VERSION ""

NS_ :

BS_:

BU_: VSIM TTPM TCM SGW SCCM RF_HUB PTS PCM ORC ITBM IRCM IC FTM FDCM ETM ESM ESC ECM DTCM DIAGNOST CBC ATMM ASCM AFLS 4 _ 0 C I w E 6 S A V Vector__XXX T

BO_ 992 VIN: 8 ECM
 SG_ VIN_MSG : 0|2@1+ (1,0) [0|0] "" FTM,TTPM,ATMM,IRCM,SGW,ITBM,FDCM,VSIM,TCM,SCCM,RF_HUB,PTS,ORC,IC,ETM,ESM,ESC,DTCM,CBC,ASCM,AFLS
 SG_ VIN_DATA : 15|56@0+ (1,0) [0|0] "" FTM,TTPM,ATMM,IRCM,SGW,ITBM,FDCM,VSIM,TCM,SCCM,RF_HUB,PTS,ORC,IC,ETM,ESM,ESC,DTCM,CBC,ASCM,AFLS

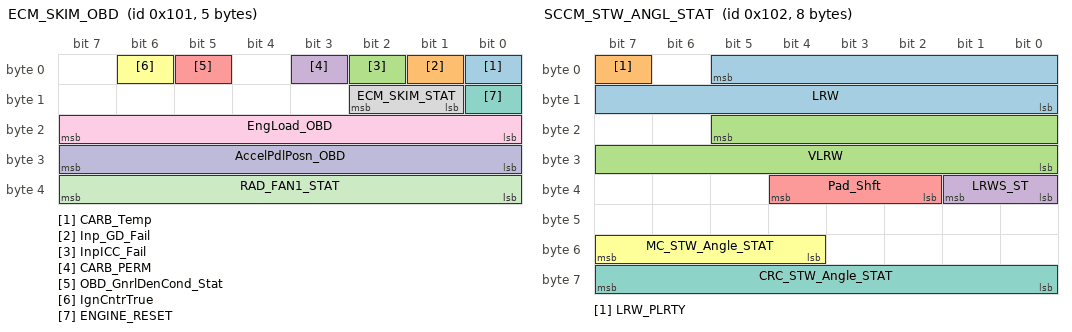
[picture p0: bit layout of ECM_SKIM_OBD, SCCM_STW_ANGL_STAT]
BO_ 257 ECM_SKIM_OBD: 5 ECM
 SG_ CARB_Temp : 0|1@1+ (1,0) [0|0] "" SGW,TCM
 SG_ Inp_GD_Fail : 1|1@1+ (1,0) [0|0] "" SGW,TCM
 SG_ InpICC_Fail : 2|1@1+ (1,0) [0|0] "" SGW,TCM
 SG_ CARB_PERM : 3|1@1+ (1,0) [0|0] "" SGW,TCM
 SG_ OBD_GnrlDenCond_Stat : 5|1@1+ (1,0) [0|0] "" SGW,TCM
 SG_ IgnCntrTrue : 6|1@1+ (1,0) [0|0] "" SGW,TCM
 SG_ ENGINE_RESET : 8|1@1+ (1,0) [0|0] "" SGW
 SG_ ECM_SKIM_STAT : 9|2@1+ (1,0) [0|0] "" SGW
 SG_ EngLoad_OBD : 16|8@1+ (0.3922,0) [0|100] "%" FTM,SGW,TCM,ETM
 SG_ AccelPdlPosn_OBD : 24|8@1+ (0.3922,0) [0|100] "%" SGW,VSIM,TCM,ETM
 SG_ RAD_FAN1_STAT : 32|8@1+ (1,0) [0|100] "%" FTM,SGW,ETM

BO_ 258 SCCM_STW_ANGL_STAT: 8 SCCM
 SG_ LRW : 5|14@0+ (0.5,-2048) [-2048|2047] "Degrees" FTM,IRCM,SGW,PCM,TCM,ORC,ESC,ECM,DTCM,CBC,ASCM,AFLS
 SG_ LRW_PLRTY : 7|1@1+ (1,0) [0|0] "" IRCM,SGW,ORC,ETM,ESC,AFLS
 SG_ VLRW : 21|14@0+ (0.5,-2048) [-2048|2047] "°/s" IRCM,SGW,PCM,ESC,ECM,DTCM,AFLS
 SG_ LRWS_ST : 32|2@1+ (1,0) [0|0] "" IRCM,SGW,PCM,ORC,ESC,ECM,DTCM,CBC,ASCM,AFLS
 SG_ Pad_Shft : 34|3@1+ (1,0) [0|0] "" SGW,PCM,TCM
 SG_ MC_STW_Angle_STAT : 52|4@1+ (1,0) [0|15] "" IRCM,SGW,PCM,PTS,ORC,ETM,ESC,ECM
 SG_ CRC_STW_Angle_STAT : 56|8@1+ (1,0) [0|0] "" IRCM,SGW,PCM,PTS,ORC,ETM,ESC,ECM

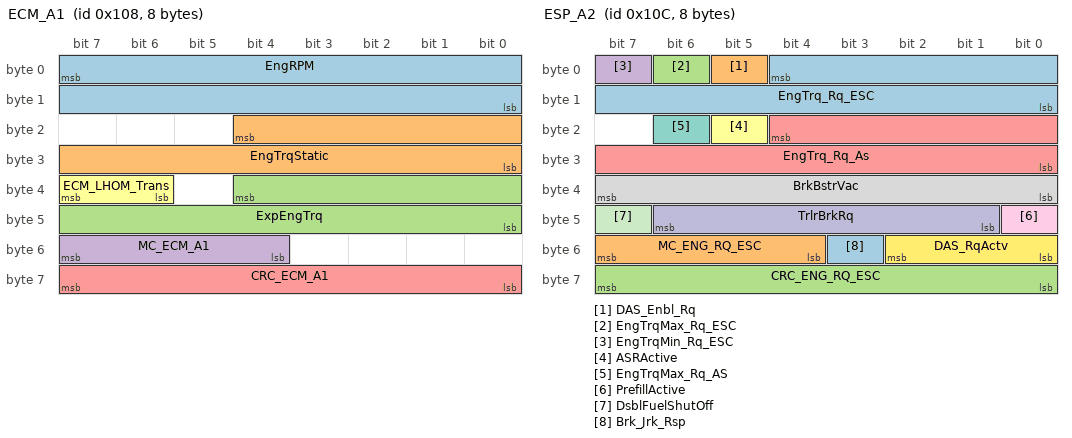
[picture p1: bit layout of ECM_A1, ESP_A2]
BO_ 264 ECM_A1: 8 ECM
 SG_ EngRPM : 7|16@0+ (1,0) [0|65534] "rpm" ATMM,IRCM,SGW,VSIM,TCM,RF_HUB,ORC,IC,ETM,ESC,DTCM,CBC,ASCM,AFLS
 SG_ EngTrqStatic : 20|13@0+ (0.25,-500) [-500|1547.5] "Nm" FTM,IRCM,SGW,TCM,ORC,ETM,ESC,DTCM
 SG_ ExpEngTrq : 36|13@0+ (0.25,-500) [-500|1547.5] "Nm" IRCM,SGW,TCM,ESC
 SG_ MC_ECM_A1 : 52|4@1+ (1,0) [0|15] "" IRCM,SGW,TCM,ESC
 SG_ CRC_ECM_A1 : 56|8@1+ (1,0) [0|0] "" IRCM,SGW,TCM,ESC
 SG_ ECM_LHOM_Trans : 38|2@1+ (1,0) [0|0] "" SGW,TCM

BO_ 268 ESP_A2: 8 ESC
 SG_ EngTrq_Rq_ESC : 4|13@0+ (0.25,-500) [-500|1547.5] "Nm" FTM,SGW,PCM,ETM,ECM
 SG_ DAS_Enbl_Rq : 5|1@1+ (1,0) [0|0] "" IRCM,SGW
 SG_ EngTrqMax_Rq_ESC : 6|1@1+ (1,0) [0|0] "" SGW,PCM,VSIM,TCM,ECM
 SG_ EngTrqMin_Rq_ESC : 7|1@1+ (1,0) [0|0] "" SGW,PCM,VSIM,TCM,ECM,DTCM
 SG_ EngTrq_Rq_As : 20|13@0+ (0.25,-500) [-500|1547.5] "Nm" IRCM,SGW,PCM,ORC,ECM
 SG_ ASRActive : 21|1@1+ (1,0) [0|0] "" FTM,IRCM,SGW,VSIM,ORC
 SG_ EngTrqMax_Rq_AS : 22|1@1+ (1,0) [0|0] "" SGW,PCM,ECM
 SG_ BrkBstrVac : 32|8@1+ (0.55,-119.7) [-119.7|20] "kPa" SGW,PCM,ORC,ECM
 SG_ PrefillActive : 40|1@1+ (1,0) [0|0] "" IRCM,SGW
 SG_ TrlrBrkRq : 41|6@1+ (2,0) [0|100] "%" SGW,ITBM
 SG_ DsblFuelShutOff : 47|1@1+ (1,0) [0|0] "" SGW,PCM,ECM
 SG_ DAS_RqActv : 48|3@1+ (1,0) [0|0] "" IRCM,SGW,ORC
 SG_ Brk_Jrk_Rsp : 51|1@1+ (1,0) [0|0] "" IRCM,SGW,ORC
 SG_ MC_ENG_RQ_ESC : 52|4@1+ (1,0) [0|15] "" IRCM,SGW,PCM,TCM,ECM
 SG_ CRC_ENG_RQ_ESC : 56|8@1+ (1,0) [0|0] "" IRCM,SGW,PCM,TCM,ECM

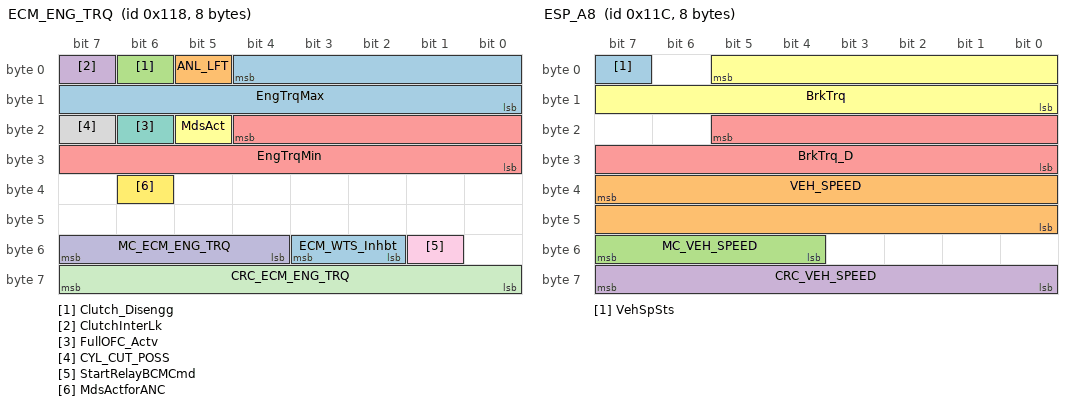
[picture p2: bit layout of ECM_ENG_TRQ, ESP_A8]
BO_ 280 ECM_ENG_TRQ: 8 ECM
 SG_ EngTrqMax : 4|13@0+ (0.25,-500) [-500|1547.5] "Nm" IRCM,SGW,TCM,ESC,DTCM
 SG_ ANL_LFT : 5|1@1+ (1,0) [0|0] "" SGW,CBC,ASCM
 SG_ Clutch_Disengg : 6|1@1+ (1,0) [0|0] "" SGW,ORC,ESC,CBC
 SG_ ClutchInterLk : 7|1@1+ (1,0) [0|0] "" SGW,ORC,ESC,DTCM
 SG_ EngTrqMin : 20|13@0+ (0.25,-500) [-500|1547.5] "Nm" IRCM,SGW,ESC,DTCM
 SG_ MdsAct : 21|1@1+ (1,0) [0|0] "" FTM,SGW,TCM,IC,ETM
 SG_ FullOFC_Actv : 22|1@1+ (1,0) [0|0] "" IRCM,SGW,ESC
 SG_ CYL_CUT_POSS : 23|1@1+ (1,0) [0|0] "" SGW
 SG_ StartRelayBCMCmd : 49|1@1+ (1,0) [0|0] "" SGW,CBC
 SG_ MC_ECM_ENG_TRQ : 52|4@1+ (1,0) [0|15] "" IRCM,SGW,TCM,ESC
 SG_ CRC_ECM_ENG_TRQ : 56|8@1+ (1,0) [0|0] "" IRCM,SGW,TCM,ESC
 SG_ MdsActforANC : 38|1@1+ (1,0) [0|0] "" ATMM,SGW,CBC
 SG_ ECM_WTS_Inhbt : 50|2@1+ (1,0) [0|0] "" SGW,CBC

BO_ 284 ESP_A8: 8 ESC
 SG_ VehSpSts : 7|1@1+ (1,0) [0|0] "" IRCM,SGW
 SG_ VEH_SPEED : 39|16@0+ (0.0078125,0) [0|511.984375] "km/h" FTM,TTPM,ATMM,IRCM,SGW,ITBM,FDCM,PCM,VSIM,TCM,RF_HUB,PTS,ORC,IC,ECM,DTCM,CBC,ASCM,AFLS
 SG_ MC_VEH_SPEED : 52|4@1+ (1,0) [0|15] "" IRCM,SGW,PCM,TCM,PTS,ORC,IC,ESM,ECM,CBC
 SG_ CRC_VEH_SPEED : 56|8@1+ (1,0) [0|0] "" IRCM,SGW,PCM,TCM,PTS,ORC,IC,ESM,ECM,CBC
 SG_ BrkTrq_D : 21|14@0+ (3,0) [0|49146] "Nm" IRCM,SGW,ECM
 SG_ BrkTrq : 5|14@0+ (3,0) [0|49146] "Nm" IRCM,SGW,ITBM,TCM,ORC,ECM

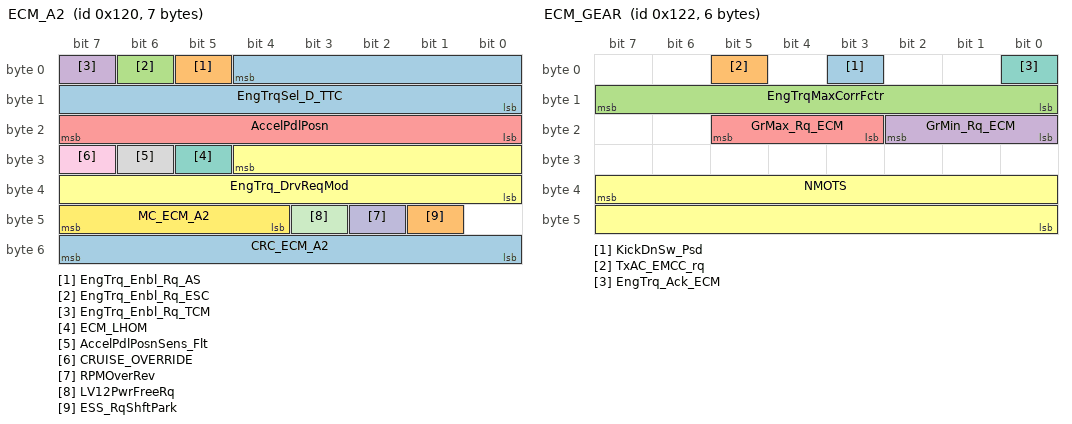
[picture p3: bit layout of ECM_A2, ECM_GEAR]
BO_ 288 ECM_A2: 7 ECM
 SG_ EngTrqSel_D_TTC : 4|13@0+ (0.25,-500) [-500|1547.5] "Nm" IRCM,SGW,TCM,ORC,ESC
 SG_ EngTrq_Enbl_Rq_AS : 5|1@1+ (1,0) [0|0] "" IRCM,SGW,ESC
 SG_ EngTrq_Enbl_Rq_ESC : 6|1@1+ (1,0) [0|0] "" IRCM,SGW,ESC
 SG_ EngTrq_Enbl_Rq_TCM : 7|1@1+ (1,0) [0|0] "" SGW,TCM,ORC
 SG_ AccelPdlPosn : 16|8@1+ (0.4,0) [0|100] "%" FTM,SGW,TCM,ETM,ESC,DTCM,CBC
 SG_ EngTrq_DrvReqMod : 28|13@0+ (0.25,-500) [-500|1547.5] "Nm" SGW,TCM,ESC
 SG_ ECM_LHOM : 29|1@1+ (1,0) [0|0] "" IRCM,SGW,TCM
 SG_ AccelPdlPosnSens_Flt : 30|1@1+ (1,0) [0|0] "" IRCM,SGW,TCM,ESC,CBC
 SG_ CRUISE_OVERRIDE : 31|1@1+ (1,0) [0|0] "" IRCM,SGW,TCM,ORC,ESC
 SG_ RPMOverRev : 42|1@1+ (1,0) [0|0] "" IRCM,SGW
 SG_ LV12PwrFreeRq : 43|1@1+ (1,0) [0|0] "" SGW,TCM,ESC
 SG_ MC_ECM_A2 : 44|4@1+ (1,0) [0|15] "" IRCM,SGW,TCM,ESC
 SG_ CRC_ECM_A2 : 48|8@1+ (1,0) [0|0] "" IRCM,SGW,TCM,ESC
 SG_ ESS_RqShftPark : 41|1@1+ (1,0) [0|0] "" SGW,TCM

BO_ 290 ECM_GEAR: 6 ECM
 SG_ KickDnSw_Psd : 3|1@1+ (1,0) [0|0] "" SGW,TCM,ESC
 SG_ TxAC_EMCC_rq : 5|1@1+ (1,0) [0|0] "" SGW,TCM
 SG_ EngTrqMaxCorrFctr : 8|8@1+ (0.0078,0) [0|1.98] "Nm" SGW,TCM
 SG_ GrMin_Rq_ECM : 16|3@1+ (1,0) [0|0] "" SGW,TCM
 SG_ GrMax_Rq_ECM : 19|3@1+ (1,0) [0|0] "" SGW,TCM
 SG_ NMOTS : 39|16@0+ (1,0) [0|65534] "rpm" SGW,TCM,ESC
 SG_ EngTrq_Ack_ECM : 0|1@1+ (1,0) [0|0] "" SGW,TCM

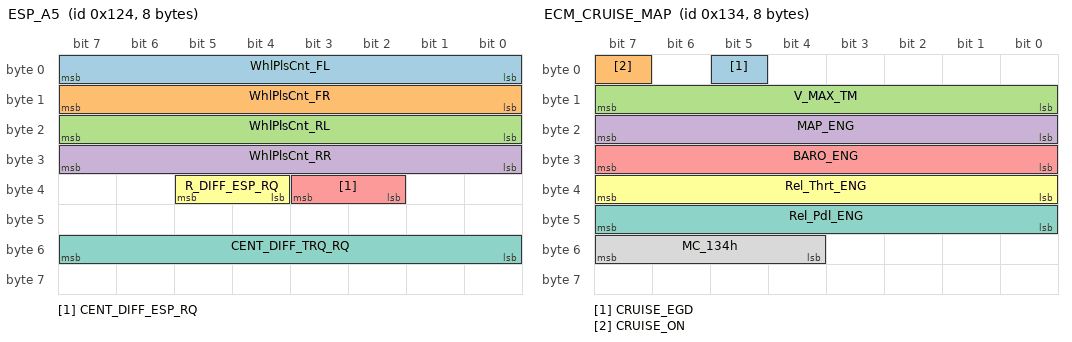
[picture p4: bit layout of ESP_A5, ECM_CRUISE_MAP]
BO_ 292 ESP_A5: 8 ESC
 SG_ WhlPlsCnt_FL : 0|8@1+ (1,0) [0|254] "Impulse" IRCM,SGW,RF_HUB,CBC
 SG_ WhlPlsCnt_FR : 8|8@1+ (1,0) [0|254] "Impulse" IRCM,SGW,RF_HUB,CBC
 SG_ WhlPlsCnt_RL : 16|8@1+ (1,0) [0|254] "Impulse" IRCM,SGW,RF_HUB,CBC
 SG_ WhlPlsCnt_RR : 24|8@1+ (1,0) [0|254] "Impulse" IRCM,SGW,RF_HUB,CBC
 SG_ CENT_DIFF_ESP_RQ : 34|2@1+ (1,0) [0|0] "" SGW,DTCM
 SG_ R_DIFF_ESP_RQ : 36|2@1+ (1,0) [0|0] "" SGW,FDCM
 SG_ CENT_DIFF_TRQ_RQ : 48|8@1+ (10,0) [0|2540] "Nm" SGW,DTCM

BO_ 308 ECM_CRUISE_MAP: 8 ECM
 SG_ CRUISE_EGD : 5|1@1+ (1,0) [0|0] "" FTM,SGW,VSIM,TCM,ORC,IC,ESC,CBC
 SG_ CRUISE_ON : 7|1@1+ (1,0) [0|0] "" FTM,SGW,TCM,ORC,IC,ESC
 SG_ V_MAX_TM : 8|8@1+ (1,0) [0|250] "km/h(mph)" SGW,TCM
 SG_ MAP_ENG : 16|8@1+ (0.8,0) [0|203.2] "kPa" FTM,SGW,ETM,ESC
 SG_ BARO_ENG : 24|8@1+ (1,0) [0|254] "kPaA" SGW,ETM,ESC
 SG_ Rel_Thrt_ENG : 32|8@1+ (0.019607843,0) [0|4.98] "Volts" SGW,ETM,ESC
 SG_ Rel_Pdl_ENG : 40|8@1+ (0.019607843,0) [0|4.98] "Volts" SGW,ETM,ESC
 SG_ MC_134h : 52|4@1+ (1,0) [0|15] "" SGW,TCM,ESC

BO_ 320 ESP_A1: 8 ESC
 SG_ Brk_Stat : 0|2@1+ (1,0) [0|0] "" FTM,SGW,ITBM,PCM,VSIM,TCM,ETM,ECM,CBC
 SG_ BrkPdl_Stat : 2|2@1+ (1,0) [0|0] "" IRCM,SGW,ITBM,PCM,VSIM,TCM,RF_HUB,ORC,ECM,DTCM,CBC
 SG_ BrkPdl_Flt : 4|1@1+ (1,0) [0|0] "" IRCM,SGW,PCM,TCM,ETM,ECM
 SG_ BrkIntrvntn_Actv_ESP : 5|1@1+ (1,0) [0|0] "" FTM,SGW,TCM,ORC,ETM,DTCM
 SG_ BrkIntrvntn_Actv_AS : 6|1@1+ (1,0) [0|0] "" IRCM,SGW,TCM,ETM
 SG_ BrkIntrvntn_Enbl : 7|1@1+ (1,0) [0|0] "" SGW,TCM,ORC,ECM
 SG_ EmgBrk_Actv : 8|1@1+ (1,0) [0|0] "" SGW,ORC
 SG_ FullBrk_Actv : 9|1@1+ (1,0) [0|0] "" SGW,ORC
 SG_ ESP_Sys_Stat : 10|2@1+ (1,0) [0|0] "" SGW,PCM,TCM,ETM,ECM
 SG_ ABS_BrkEvt : 14|1@1+ (1,0) [0|0] "" FTM,IRCM,SGW,PCM,VSIM,TCM,ORC,ETM,ECM,DTCM
 SG_ DTR_CC_Engaged : 15|1@1+ (1,0) [0|0] "" SGW,PCM,TCM,ECM,CBC
 SG_ GrMin_Rq_ESC : 16|3@1+ (1,0) [0|0] "" SGW,PCM,TCM
 SG_ GrMax_Rq_ESC : 19|3@1+ (1,0) [0|0] "" SGW,PCM,TCM
 SG_ GrMinMax_Rq_DTR : 22|1@1+ (1,0) [0|0] "" SGW,TCM
 SG_ DTR_CC_Enabled : 23|1@1+ (1,0) [0|0] "" SGW,PCM,ECM
 SG_ Brk_Thermdl : 25|1@1+ (1,0) [0|0] "" IRCM,SGW
 SG_ ShftChrDsp_Rq_ESC : 26|4@1+ (1,0) [0|0] "" SGW,PCM,TCM,ECM
 SG_ RollTestMd_Actv : 30|2@1+ (1,0) [0|0] "" IRCM,SGW,DTCM
 SG_ REF_VEH_SPEED : 33|10@0+ (0.5,0) [0|511] "km/h" SGW,TCM,ORC,ECM
 SG_ SPCR_AS_Off_Rq : 38|2@1+ (1,0) [0|0] "" IRCM,SGW,PCM,ECM
 SG_ MC_Brk_Stat : 52|4@1+ (1,0) [0|15] "" IRCM,SGW,PCM,TCM,PTS,ORC,ECM
 SG_ CRC_Brk_Stat : 56|8@1+ (1,0) [0|0] "" IRCM,SGW,PCM,TCM,PTS,ORC,ECM

BO_ 324 TRNS_SPD: 8 TCM
 SG_ K_STO_B : 0|1@1+ (1,0) [0|0] "" FTM,SGW,ETM,ECM
 SG_ EngSt_Enbl_Rq_TCM : 5|1@1+ (1,0) [0|0] "" FTM,SGW,RF_HUB,ETM
 SG_ Gr : 8|4@1+ (1,0) [0|0] "" FTM,IRCM,SGW,VSIM,RF_HUB,ORC,IC,ESC,ECM,DTCM,CBC,ASCM
 SG_ Gr_Target : 12|4@1+ (1,0) [0|0] "" FTM,IRCM,SGW,ESC,ECM,CBC
 SG_ K_G_B : 17|1@1+ (1,0) [0|0] "" FTM,SGW,ETM,ECM
 SG_ K_O_B : 18|1@1+ (1,0) [0|0] "" FTM,SGW,ETM,ECM
 SG_ K_S_B : 19|1@1+ (1,0) [0|0] "" FTM,SGW,ETM,ECM
 SG_ Trns_EMCC_Achvd : 20|1@1+ (1,0) [0|0] "" FTM,SGW,ETM,ECM
 SG_ OUTPUT_SPEED : 31|16@0+ (1,0) [0|65534] "rpm" FTM,SGW,ETM,ESC,ECM,DTCM
 SG_ N_Turb : 47|16@0+ (1,0) [0|65534] "rpm" FTM,SGW,ETM,ECM
 SG_ OutputSpdPolarity : 56|2@1+ (1,0) [0|0] "" SGW,ETM
 SG_ TCM_TmpManMd : 62|1@1+ (1,0) [0|0] "" SGW
 SG_ TCM_ManMd : 63|1@1+ (1,0) [0|0] "" SGW,IC
 SG_ DrvRst_Hi : 4|1@1+ (1,0) [0|0] "" SGW,ECM
 SG_ GearSwitchActiveSts : 2|1@1+ (1,0) [0|0] "" SGW,ETM
 SG_ KS : 16|1@1+ (1,0) [0|0] "" FTM,SGW,ETM,ECM
 SG_ TRNS_SPD_MC : 58|4@1+ (1,0) [0|15] "" FTM,SGW,ETM,ESC,ECM
 SG_ Ups_Inh_Act : 1|1@1+ (1,0) [0|0] "" SGW,ECM
 SG_ OD_OFF : 3|1@1+ (1,0) [0|0] "" SGW
 SG_ EngBrkCanRq : 22|1@1+ (1,0) [0|0] "" SGW,ECM
 SG_ PTO_Enbl : 23|1@1+ (1,0) [0|0] "" SGW,VSIM,ECM

BO_ 331 ESP_A3: 8 ESC
 SG_ BrkPrss_TMC : 2|11@0+ (0.1,0) [0|200] "bar" FTM,SGW,TCM,ORC,ETM,ECM
 SG_ HSA_BrkPrss : 32|6@1+ (1,0) [0|50] "bar" SGW,ITBM,PCM,ORC,ETM,ECM
 SG_ BrkBstrVac_OBD : 40|8@1+ (0.019607843,0) [0|5] "Volts" SGW,ECM
 SG_ MC_ESP_A3 : 52|4@1+ (1,0) [0|15] "" SGW,PCM,TCM,PTS,ORC,ECM
 SG_ CRC_ESP_A3 : 56|8@1+ (1,0) [0|0] "" SGW,PCM,TCM,PTS,ORC,ECM

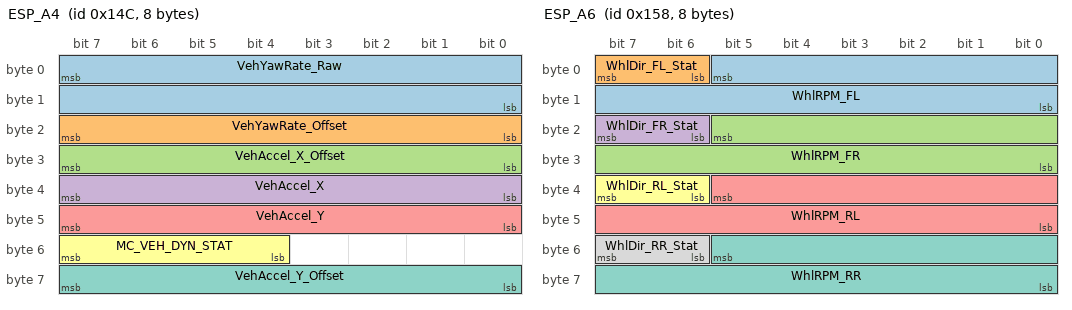
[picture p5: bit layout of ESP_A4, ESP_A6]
BO_ 332 ESP_A4: 8 ESC
 SG_ VehYawRate_Raw : 7|16@0+ (0.01,-327.68) [-327.68|327.66] "°/s" IRCM,SGW,ETM,DTCM,CBC,AFLS
 SG_ VehYawRate_Offset : 16|8@1+ (0.08,-10.24) [-6.96|6.96] "" IRCM,SGW,ORC,DTCM,AFLS
 SG_ VehAccel_X_Offset : 24|8@1+ (0.02,-2.56) [-2.56|2.52] "m/s²" IRCM,SGW,TCM,ETM,ECM,DTCM
 SG_ VehAccel_X : 32|8@1+ (0.08,-10.24) [-10.24|10.08] "m/s²" FTM,IRCM,SGW,TCM,ECM,DTCM,CBC,ASCM
 SG_ VehAccel_Y : 40|8@1+ (0.08,-10.24) [-10.24|10.08] "m/s²" FTM,IRCM,SGW,TCM,ECM,DTCM,CBC,ASCM
 SG_ MC_VEH_DYN_STAT : 52|4@1+ (1,0) [0|15] "" IRCM,SGW,PCM,TCM,PTS,ORC,ETM,ECM
 SG_ VehAccel_Y_Offset : 56|8@1+ (0.02,-2.56) [-2.56|2.52] "m/s²" IRCM,SGW,TCM,ETM,ECM,DTCM

BO_ 344 ESP_A6: 8 ESC
 SG_ WhlRPM_FL : 5|14@0+ (0.5,0) [0|8191] "rpm" FTM,IRCM,SGW,FDCM,TCM,ORC,ETM,DTCM
 SG_ WhlDir_FL_Stat : 6|2@1+ (1,0) [0|0] "" IRCM,SGW
 SG_ WhlRPM_FR : 21|14@0+ (0.5,0) [0|8191] "rpm" FTM,IRCM,SGW,FDCM,TCM,ORC,ETM,ECM,DTCM
 SG_ WhlDir_FR_Stat : 22|2@1+ (1,0) [0|0] "" IRCM,SGW
 SG_ WhlRPM_RL : 37|14@0+ (0.5,0) [0|8191] "rpm" FTM,IRCM,SGW,FDCM,TCM,ORC,ETM,DTCM
 SG_ WhlDir_RL_Stat : 38|2@1+ (1,0) [0|0] "" IRCM,SGW
 SG_ WhlRPM_RR : 53|14@0+ (0.5,0) [0|8191] "rpm" FTM,IRCM,SGW,FDCM,TCM,ORC,ETM,ECM,DTCM
 SG_ WhlDir_RR_Stat : 54|2@1+ (1,0) [0|0] "" IRCM,SGW

BO_ 352 DTCM_A1: 8 CBC
 SG_ TCASE_STAT : 1|3@1+ (1,0) [0|0] "" FTM,IRCM,SGW,FDCM,PCM,TCM,ORC,IC,ESC,ECM,CBC,ASCM
 SG_ ACT_CNT_DIF_TRQ : 24|8@1+ (10,0) [0|2540] "Nm" SGW,ESC
 SG_ DES_CNT_DIF_TRQ : 48|8@1+ (10,0) [0|2540] "Nm" SGW
 SG_ SHFT_ABRT : 4|1@1+ (1,0) [0|0] "" SGW

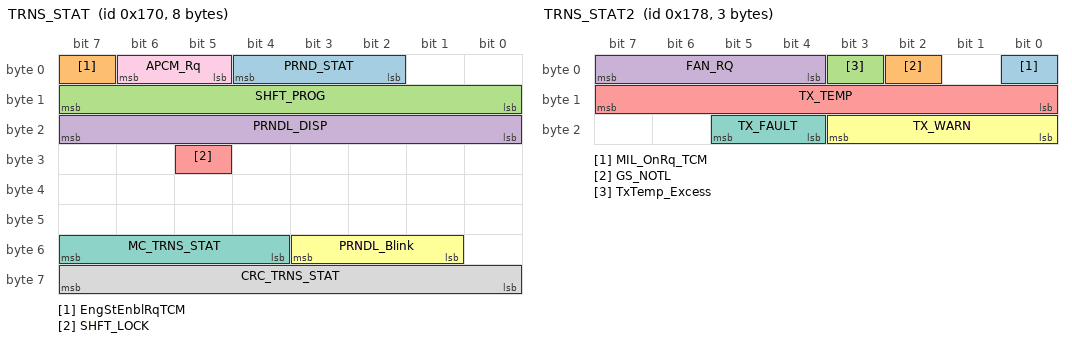
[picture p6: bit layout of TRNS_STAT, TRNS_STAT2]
BO_ 368 TRNS_STAT: 8 TCM
 SG_ PRND_STAT : 2|3@1+ (1,0) [0|0] "" FTM,IRCM,SGW,PTS,ORC,IC,ESC,ECM,CBC
 SG_ EngStEnblRqTCM : 7|1@1+ (1,0) [0|0] "" SGW,RF_HUB,ECM
 SG_ SHFT_PROG : 8|8@1+ (1,0) [0|0] "" FTM,SGW,IC,ESC,ECM,CBC
 SG_ PRNDL_DISP : 16|8@1+ (1,0) [0|0] "" SGW,VSIM,ORC,IC,ESM,ESC,ECM,DTCM,CBC,AFLS
 SG_ SHFT_LOCK : 29|1@1+ (1,0) [0|0] "" SGW,ESM
 SG_ PRNDL_Blink : 49|3@1+ (1,0) [0|0] "" SGW,IC,ESM
 SG_ MC_TRNS_STAT : 52|4@1+ (1,0) [0|15] "" IRCM,SGW,PTS,ESM,ESC,ECM
 SG_ CRC_TRNS_STAT : 56|8@1+ (1,0) [0|0] "" IRCM,SGW,PTS,ESM,ESC,ECM
 SG_ APCM_Rq : 5|2@1+ (1,0) [0|0] "" SGW,ESM

BO_ 376 TRNS_STAT2: 3 TCM
 SG_ MIL_OnRq_TCM : 0|1@1+ (1,0) [0|0] "" FTM,SGW,VSIM,ECM
 SG_ GS_NOTL : 2|1@1+ (1,0) [0|0] "" IRCM,SGW,ORC,ECM
 SG_ TxTemp_Excess : 3|1@1+ (1,0) [0|0] "" FTM,SGW,IC,ETM,ECM
 SG_ FAN_RQ : 4|4@1+ (7.2,0) [0|100] "%" SGW,ECM
 SG_ TX_TEMP : 8|8@1+ (1,-50) [-50|204] "°C" FTM,SGW,VSIM,IC,ECM,DTCM,CBC
 SG_ TX_WARN : 16|4@1+ (1,0) [0|0] "" SGW,IC,ETM
 SG_ TX_FAULT : 20|2@1+ (1,0) [0|0] "" SGW,RF_HUB,ETM

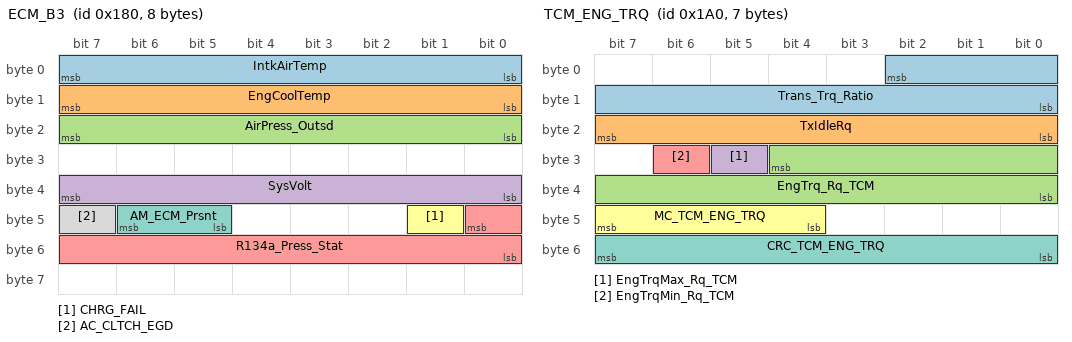
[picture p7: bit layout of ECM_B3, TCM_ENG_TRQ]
BO_ 384 ECM_B3: 8 ECM
 SG_ IntkAirTemp : 0|8@1+ (1,-40) [-40|214] "°C" SGW,VSIM,TCM,ETM
 SG_ EngCoolTemp : 8|8@1+ (1,-40) [-40|214] "°C" FTM,SGW,VSIM,TCM,IC,ETM,ESC,DTCM,CBC
 SG_ AirPress_Outsd : 16|8@1+ (1,0) [0|254] "kPaA" TTPM,IRCM,SGW,VSIM,TCM,RF_HUB,ESC
 SG_ SysVolt : 32|8@1+ (0.0618,0) [0|15.6972] "Volts" SGW
 SG_ R134a_Press_Stat : 40|9@0+ (0.1,0) [0|40] "bar" SGW,CBC
 SG_ CHRG_FAIL : 41|1@1+ (1,0) [0|0] "" FTM,SGW,IC,ETM
 SG_ AM_ECM_Prsnt : 45|2@1+ (1,0) [0|0] "" SGW,CBC
 SG_ AC_CLTCH_EGD : 47|1@1+ (1,0) [0|0] "" FTM,SGW,VSIM,TCM,CBC

BO_ 416 TCM_ENG_TRQ: 7 TCM
 SG_ Trans_Trq_Ratio : 2|11@0+ (0.01,0) [0|20.46] "" FTM,IRCM,SGW,ETM,ESC,ECM
 SG_ TxIdleRq : 16|8@1+ (4,500) [500|1516] "rpm" SGW,ESC,ECM
 SG_ EngTrq_Rq_TCM : 28|13@0+ (0.25,-500) [-500|1547.5] "Nm" SGW,ESC,ECM
 SG_ EngTrqMax_Rq_TCM : 29|1@1+ (1,0) [0|0] "" SGW,ESC,ECM
 SG_ EngTrqMin_Rq_TCM : 30|1@1+ (1,0) [0|0] "" SGW,ESC,ECM
 SG_ MC_TCM_ENG_TRQ : 44|4@1+ (1,0) [0|15] "" IRCM,SGW,ESC,ECM
 SG_ CRC_TCM_ENG_TRQ : 48|8@1+ (1,0) [0|0] "" IRCM,SGW,ESC,ECM

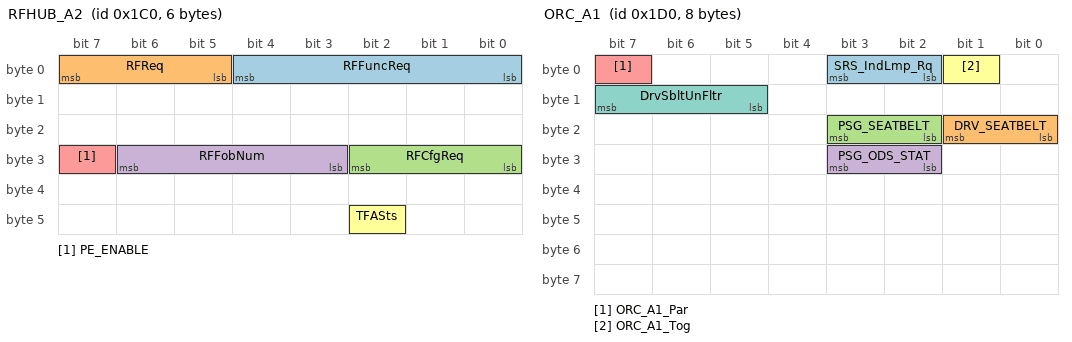
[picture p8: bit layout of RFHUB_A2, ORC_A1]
BO_ 448 RFHUB_A2: 6 RF_HUB
 SG_ RFFuncReq : 0|5@1+ (1,0) [0|0] "" SGW,VSIM,IC,ETM,CBC
 SG_ RFReq : 5|3@1+ (1,0) [0|0] "" SGW,IC,CBC
 SG_ RFCfgReq : 24|3@1+ (1,0) [0|0] "" SGW,CBC
 SG_ RFFobNum : 27|4@1+ (1,0) [0|0] "" SGW,CBC
 SG_ PE_ENABLE : 31|1@1+ (1,0) [0|0] "" SGW,IC,CBC
 SG_ TFASts : 42|1@1+ (1,0) [0|0] "" SGW,IC,CBC

BO_ 456 CBC_VTA: 4 CBC
 SG_ VTA_STAT : 0|3@1+ (1,0) [0|0] "" SGW,VSIM,RF_HUB,ETM

BO_ 464 ORC_A1: 8 ORC
 SG_ SRS_IndLmp_Rq : 2|2@1+ (1,0) [0|0] "" FTM,SGW,IC,ETM
 SG_ DRV_SEATBELT : 16|2@1+ (1,0) [0|0] "" FTM,IRCM,SGW,PCM,VSIM,TCM,IC,ETM,ESC,ECM
 SG_ PSG_SEATBELT : 18|2@1+ (1,0) [0|0] "" FTM,SGW,VSIM,IC
 SG_ PSG_ODS_STAT : 26|2@1+ (1,0) [0|0] "" FTM,SGW,VSIM,IC
 SG_ ORC_A1_Par : 7|1@1+ (1,0) [0|0] "" IRCM,SGW
 SG_ ORC_A1_Tog : 1|1@1+ (1,0) [0|0] "" IRCM,SGW
 SG_ DrvSbltUnFltr : 13|3@1+ (1,0) [0|0] "" SGW

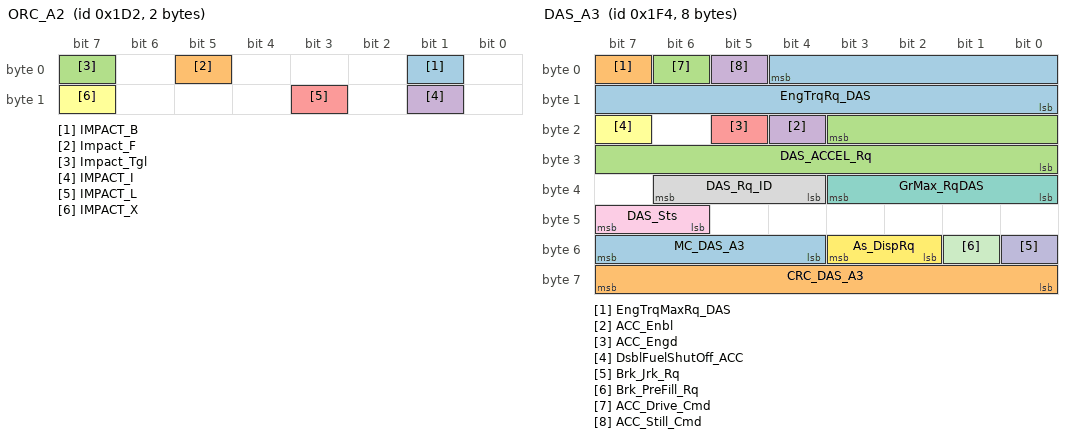
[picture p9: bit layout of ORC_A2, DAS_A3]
BO_ 466 ORC_A2: 2 ORC
 SG_ IMPACT_B : 1|1@1+ (1,0) [0|0] "" FTM,SGW,ETM
 SG_ Impact_F : 5|1@1+ (1,0) [0|0] "" FTM,SGW,ETM
 SG_ Impact_Tgl : 7|1@1+ (1,0) [0|0] "" FTM,SGW,PCM,ETM,ECM,CBC
 SG_ IMPACT_I : 9|1@1+ (1,0) [0|0] "" FTM,SGW,ETM
 SG_ IMPACT_L : 11|1@1+ (1,0) [0|0] "" SGW,ETM
 SG_ IMPACT_X : 15|1@1+ (1,0) [0|0] "" FTM,SGW,PCM,VSIM,ETM,ECM,CBC

BO_ 500 DAS_A3: 8 IRCM
 SG_ EngTrqRq_DAS : 4|13@0+ (0.25,-500) [-500|1547.5] "Nm" SGW,ETM,ESC
 SG_ EngTrqMaxRq_DAS : 7|1@1+ (1,0) [0|0] "" SGW,ESC
 SG_ DAS_ACCEL_Rq : 19|12@0+ (0.004885,-16) [-16|4] "m/s²" SGW,ORC,ESC
 SG_ ACC_Enbl : 20|1@1+ (1,0) [0|0] "" SGW,IC,ESC
 SG_ ACC_Engd : 21|1@1+ (1,0) [0|0] "" FTM,SGW,IC,ESC,CBC
 SG_ DsblFuelShutOff_ACC : 23|1@1+ (1,0) [0|0] "" SGW,ESC
 SG_ GrMax_RqDAS : 32|4@1+ (1,0) [0|0] "" SGW,ESC
 SG_ DAS_Rq_ID : 36|3@1+ (1,0) [0|0] "" SGW,ITBM,ORC,ESC
 SG_ DAS_Sts : 46|2@1+ (1,0) [0|0] "" SGW,ESC
 SG_ Brk_Jrk_Rq : 48|1@1+ (1,0) [0|0] "" SGW,ESC
 SG_ Brk_PreFill_Rq : 49|1@1+ (1,0) [0|0] "" SGW,ESC
 SG_ As_DispRq : 50|2@1+ (1,0) [0|0] "" SGW,ORC,IC,ESC
 SG_ MC_DAS_A3 : 52|4@1+ (1,0) [0|15] "" SGW,PCM,ESC,ECM
 SG_ CRC_DAS_A3 : 56|8@1+ (1,0) [0|0] "" SGW,ESC
 SG_ ACC_Drive_Cmd : 6|1@1+ (1,0) [0|0] "" SGW,ESC
 SG_ ACC_Still_Cmd : 5|1@1+ (1,0) [0|0] "" SGW,ORC,ESC

BO_ 501 DAS_A4: 8 IRCM
 SG_ HMI_Screens : 0|8@1+ (1,0) [0|254] "Text" SGW,IC
 SG_ SetSpeed_KPH : 8|8@1+ (1,0) [0|250] "km/h" SGW,PCM,TCM,IC,ECM
 SG_ SetSpeed_MPH : 16|8@1+ (1,0) [0|250] "mph" SGW,PCM,TCM,ORC,IC
 SG_ FCW_Error : 26|2@1+ (1,0) [0|0] "" SGW,ORC,IC,ETM
 SG_ ACCOnOff : 36|3@1+ (1,0) [0|0] "" FTM,SGW,ORC,IC,ETM
 SG_ Sm_ICON_Dspl : 40|6@1+ (1,0) [0|0] "" SGW,IC
 SG_ RadarBlocked : 46|1@1+ (1,0) [0|0] "" SGW,ORC,IC,CBC
 SG_ ACConlyNA_DASMSts : 48|1@1+ (1,0) [0|0] "" FTM,SGW,IC,ETM
 SG_ NCConlyNA_DASMSts : 49|1@1+ (1,0) [0|0] "" SGW,IC
 SG_ ACCFaulted : 50|1@1+ (1,0) [0|0] "" FTM,SGW,ORC,IC,ETM
 SG_ FCWonlyNA_DASMSts : 51|1@1+ (1,0) [0|0] "" SGW,IC
 SG_ ACCNA_DASMSts : 52|1@1+ (1,0) [0|0] "" SGW,IC
 SG_ NCCNA_DASMSts : 53|1@1+ (1,0) [0|0] "" SGW,IC
 SG_ ObjIntrstDist : 56|8@1+ (1,0) [0|253] "m" SGW,PCM,TCM,ORC,ESC
 SG_ CameraBlocked : 54|1@1+ (1,0) [0|0] "" SGW,ORC,IC,CBC
 SG_ CameraFailure : 55|1@1+ (1,0) [0|0] "" SGW,ORC,IC
 SG_ CIPV_Fused : 30|1@1+ (1,0) [0|0] "" SGW,ORC
 SG_ FCW_BrkOn : 29|1@1+ (1,0) [0|0] "" SGW,ORC,CBC
 SG_ FCWBrakingOff : 47|1@1+ (1,0) [0|0] "" SGW,IC
 SG_ ACC_EB_Req : 39|1@1+ (1,0) [0|0] "" SGW,PCM,ECM

BO_ 512 CBC_PT3: 8 CBC
 SG_ AirTemp_Outsd : 0|8@1+ (0.5,-40) [-40|85] "°C" IRCM,SGW,PCM,ORC,ECM,DTCM
 SG_ AMB_TEMP_AVG : 15|16@0+ (0.01,-40) [-40|85] "°C" SGW,VSIM,TCM,RF_HUB,PTS,ESC,ASCM
 SG_ AMB_TEMP_VOLT : 24|8@1+ (0.019607843,0) [0|4.98] "Volts" SGW,PCM,ECM
 SG_ FUEL_VOLT : 32|8@1+ (0.019607843,0) [0|4.98] "Volts" SGW,PCM,IC,ECM
 SG_ FUEL_VOLT2 : 40|8@1+ (0.019607843,0) [0|4.98] "Volts" SGW,PCM,IC,ECM
 SG_ BATT_VOLT : 48|8@1+ (0.1,0) [5|18] "Volts" TTPM,ATMM,IRCM,SGW,ITBM,FDCM,PCM,VSIM,TCM,SCCM,RF_HUB,PTS,ORC,IC,ETM,ESM,ESC,ECM,DTCM,ASCM,AFLS

BO_ 514 WHEEL_SPEED_2: 8 ESC
 SG_ BrkPdlRawStat : 33|10@0+ (0.0048828125,0) [0|4.9951171875] "Volts" FTM,SGW,PCM,ETM,ECM

BO_ 520 CBC_PT6: 8 CBC
 SG_ AC_OutptCurrStat : 8|8@1+ (0.008,0) [0|2] "Amp" SGW,PCM,ECM
 SG_ BrkPdlStat_CBC : 18|2@1+ (1,0) [0|0] "" SGW,RF_HUB
 SG_ CBCEngineOffRequest : 48|1@1+ (1,0) [0|0] "" ECM
 SG_ CRC_CBC_PT6 : 56|8@1+ (1,0) [0|0] "" ECM
 SG_ MC_CBC_PT6 : 52|4@1+ (1,0) [0|15] "" ECM

BO_ 557 SWS_8: 8 CBC
 SG_ HrnSwPsd : 8|1@1+ (1,0) [0|0] "" SGW,VSIM

BO_ 559 ECM_A5: 8 ECM
 SG_ ActlAccelPdlPosn : 0|8@1+ (0.4,0) [0|100] "%" FTM,IRCM,SGW,ORC,ETM,ESC
 SG_ MC_ECM_A5 : 52|4@1+ (1,0) [0|15] "" IRCM,SGW,ESC
 SG_ CRC_ECM_A5 : 56|8@1+ (1,0) [0|0] "" IRCM,SGW,ESC
 SG_ ECM_WARN_BTO : 48|1@1+ (1,0) [0|0] "" SGW,IC

BO_ 584 PN14_STAT: 8 CBC
 SG_ PN14_LS_Actv : 0|1@1+ (1,0) [0|0] "" SGW,IC
 SG_ Batt_ST_Crit : 42|1@1+ (1,0) [0|0] "" SGW,IC,ASCM

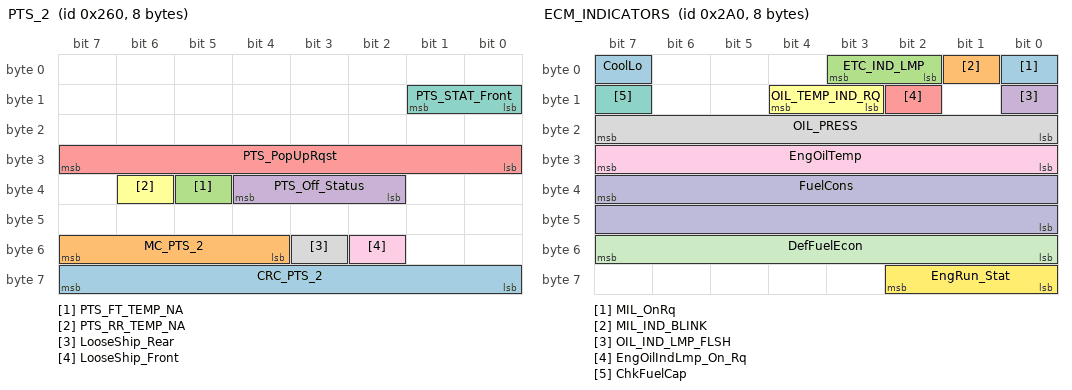
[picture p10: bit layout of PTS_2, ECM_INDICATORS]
BO_ 608 PTS_2: 8 PTS
 SG_ CRC_PTS_2 : 56|8@1+ (1,0) [0|0] "" SGW,ESC
 SG_ MC_PTS_2 : 52|4@1+ (1,0) [0|15] "" SGW,ESC
 SG_ PTS_FT_TEMP_NA : 37|1@1+ (1,0) [0|0] "" SGW,IC
 SG_ PTS_Off_Status : 34|3@1+ (1,0) [0|0] "" SGW,IC
 SG_ PTS_PopUpRqst : 24|8@1+ (1,0) [0|0] "" SGW,IC
 SG_ PTS_RR_TEMP_NA : 38|1@1+ (1,0) [0|0] "" SGW,IC
 SG_ PTS_STAT_Front : 8|2@1+ (1,0) [0|0] "" SGW,CBC
 SG_ LooseShip_Rear : 51|1@1+ (1,0) [0|0] "" SGW,IC
 SG_ LooseShip_Front : 50|1@1+ (1,0) [0|0] "" SGW,IC

BO_ 624 CBC_PT8: 8 CBC
 SG_ EngineOffTimer : 51|12@0+ (1,0) [0|4080] "min" SGW,PCM,ETM,ECM
 SG_ PNC_ALM_ACT : 55|1@1+ (1,0) [0|0] "" SGW,VSIM
 SG_ Gate_Req_PE : 22|2@1+ (1,0) [0|0] "" SGW,RF_HUB,ETM
 SG_ FuelTxfrSts : 42|2@1+ (1,0) [0|0] "" SGW,PCM,ECM
 SG_ HAZARD_STATUS : 47|1@1+ (1,0) [0|0] "" FTM,SGW,VSIM

BO_ 632 ECM_B2: 8 ECM
 SG_ CC_SetSpdDspl : 0|8@1+ (1,0) [0|250] "km/h" FTM,SGW,VSIM,IC
 SG_ EVPmpStat : 12|2@1+ (1,0) [0|0] "" SGW,ESC
 SG_ CC_SetSpdDsplMPH : 40|8@1+ (1,0) [0|254] "mph" FTM,SGW,IC,ETM
 SG_ IdleShutDwnApply : 11|1@1+ (1,0) [0|0] "" SGW,IC
 SG_ EnblFuelTxfr : 35|1@1+ (1,0) [0|0] "" SGW,CBC

BO_ 639 GW_IBS_DATA: 8 CBC
 SG_ IBS_Q_received : 7|16@0+ (0.125,0) [0|8191.75] "Ah" SGW
 SG_ IBS_Q_released : 23|16@0+ (0.125,0) [0|8191.75] "Ah" SGW
 SG_ IBS_Tm_Lst_Reset_Sec : 39|16@0+ (2,0) [0|86398] "sec" SGW
 SG_ IBS_Tm_Lst_Reset_Days : 51|12@0+ (1,0) [0|4094] "Days" SGW

BO_ 656 RF_CHAR: 4 RF_HUB
 SG_ UConnSeed1 : 0|8@1+ (1,0) [0|0] "" SGW,ETM
 SG_ UConnSeed2 : 8|8@1+ (1,0) [0|0] "" SGW,ETM
 SG_ UConnSeed3 : 16|8@1+ (1,0) [0|0] "" SGW,ETM
 SG_ UConnSeed4 : 24|8@1+ (1,0) [0|0] "" SGW,ETM

BO_ 660 DST_TOC: 8 ESC
 SG_ MC_294h : 52|4@1+ (1,0) [0|15] "" SGW
 SG_ CRC_294h : 56|8@1+ (1,0) [0|0] "" SGW
 SG_ BrkPrss_One : 17|10@0+ (0.0048828125,0) [0|4.9951171875] "Volts" SGW,PCM,ECM
 SG_ BrkPrss_Two : 33|10@0+ (0.0048828125,0) [0|4.9951171875] "Volts" SGW,PCM,ECM
 SG_ SyncPos : 37|3@1+ (1,0) [0|0] "" SGW,PCM,ECM

BO_ 672 ECM_INDICATORS: 8 ECM
 SG_ MIL_OnRq : 0|1@1+ (1,0) [0|0] "" FTM,SGW,VSIM,ORC,IC,ETM,CBC
 SG_ MIL_IND_BLINK : 1|1@1+ (1,0) [0|0] "" SGW,VSIM,ORC,IC,CBC
 SG_ ETC_IND_LMP : 2|2@1+ (1,0) [0|0] "" FTM,SGW,IC,ETM,CBC
 SG_ OIL_IND_LMP_FLSH : 8|1@1+ (1,0) [0|0] "" SGW,IC,ETM
 SG_ EngOilIndLmp_On_Rq : 10|1@1+ (1,0) [0|0] "" FTM,SGW,VSIM,IC,ETM,CBC
 SG_ OIL_TEMP_IND_RQ : 11|2@1+ (1,0) [0|0] "" FTM,SGW,IC,ETM
 SG_ ChkFuelCap : 15|1@1+ (1,0) [0|0] "" FTM,SGW,IC,ETM
 SG_ OIL_PRESS : 16|8@1+ (4,0) [0|1016] "kPaG" FTM,SGW,VSIM,IC,ETM
 SG_ EngOilTemp : 24|8@1+ (1,-40) [-40|160] "°C" FTM,SGW,TCM,IC,ETM
 SG_ FuelCons : 39|16@0+ (0.21668,0) [0|14200] "µl/100ms" FTM,SGW,VSIM,IC,ETM
 SG_ DefFuelEcon : 48|8@1+ (0.2,0) [0|50] "kmpl" SGW,IC
 SG_ EngRun_Stat : 56|3@1+ (1,0) [0|0] "" SGW,VSIM,TCM,RF_HUB,IC,ESC,CBC,ASCM
 SG_ CoolLo : 7|1@1+ (1,0) [0|0] "" FTM,SGW,IC

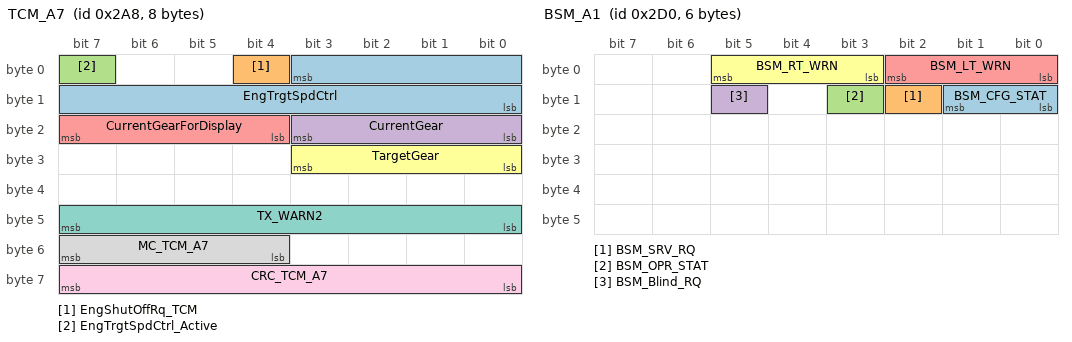
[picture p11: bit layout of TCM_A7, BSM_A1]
BO_ 680 TCM_A7: 8 TCM
 SG_ EngTrgtSpdCtrl : 3|12@0+ (2.5,0) [0|10235] "rpm" SGW,ECM
 SG_ EngShutOffRq_TCM : 4|1@1+ (1,0) [0|0] "" SGW,ECM
 SG_ EngTrgtSpdCtrl_Active : 7|1@1+ (1,0) [0|0] "" SGW,ECM
 SG_ CurrentGear : 16|4@1+ (1,0) [0|0] "" FTM,IRCM,SGW,ECM
 SG_ CurrentGearForDisplay : 20|4@1+ (1,0) [0|0] "" SGW,VSIM,IC
 SG_ TargetGear : 24|4@1+ (1,0) [0|0] "" IRCM,SGW,ECM
 SG_ TX_WARN2 : 40|8@1+ (1,0) [0|0] "" SGW,IC,ETM
 SG_ MC_TCM_A7 : 52|4@1+ (1,0) [0|15] "" IRCM,SGW,ESC,ECM
 SG_ CRC_TCM_A7 : 56|8@1+ (1,0) [0|0] "" IRCM,SGW,ESC,ECM

BO_ 698 Uconnect_1: 4 ETM
 SG_ UConnReq : 0|5@1+ (1,0) [0|0] "" RF_HUB
 SG_ UConnReqAuthCode : 15|16@0+ (1,0) [0|0] "" RF_HUB
 SG_ UConnReqFOBNum : 24|4@1+ (1,0) [0|0] "" RF_HUB

BO_ 706 EcuCfg15: 8 CBC
 SG_ EC_ECUCfg15_Stat : 0|2@1+ (1,0) [0|0] "" SGW,RF_HUB,ASCM
 SG_ EC_CBC15A : 2|6@1+ (1,0) [0|0] "" SGW,RF_HUB
 SG_ EC_CBC15B : 15|40@0+ (1,0) [0|0] "" SGW,RF_HUB
 SG_ EC_Suspension : 55|16@0+ (1,0) [0|0] "" SGW,RF_HUB

BO_ 707 EcuBuCfg15: 8 RF_HUB
 SG_ EC_BU_ECUCfg15_Stat : 0|2@1+ (1,0) [0|0] "" SGW,CBC
 SG_ EC_BU_CBC15A : 2|6@1+ (1,0) [0|0] "" SGW,CBC
 SG_ EC_BU_CBC15B : 15|40@0+ (1,0) [0|0] "" SGW,CBC
 SG_ EC_BU_Suspension : 55|16@0+ (1,0) [0|0] "" SGW,CBC

BO_ 719 STATUS_C_PTS: 8 PTS
 SG_ PTS_DBD : 16|1@1+ (1,0) [0|0] "" SGW,IC

BO_ 720 BSM_A1: 6 CBC
 SG_ BSM_CFG_STAT : 8|2@1+ (1,0) [0|0] "" IRCM,SGW,ORC,IC
 SG_ BSM_SRV_RQ : 10|1@1+ (1,0) [0|0] "" FTM,IRCM,SGW,ORC,IC
 SG_ BSM_OPR_STAT : 11|1@1+ (1,0) [0|0] "" FTM,IRCM,SGW,IC
 SG_ BSM_Blind_RQ : 13|1@1+ (1,0) [0|0] "" IRCM,SGW,ORC,IC
 SG_ BSM_LT_WRN : 0|3@1+ (1,0) [0|0] "" IRCM,SGW,ORC
 SG_ BSM_RT_WRN : 3|3@1+ (1,0) [0|0] "" IRCM,SGW,ORC

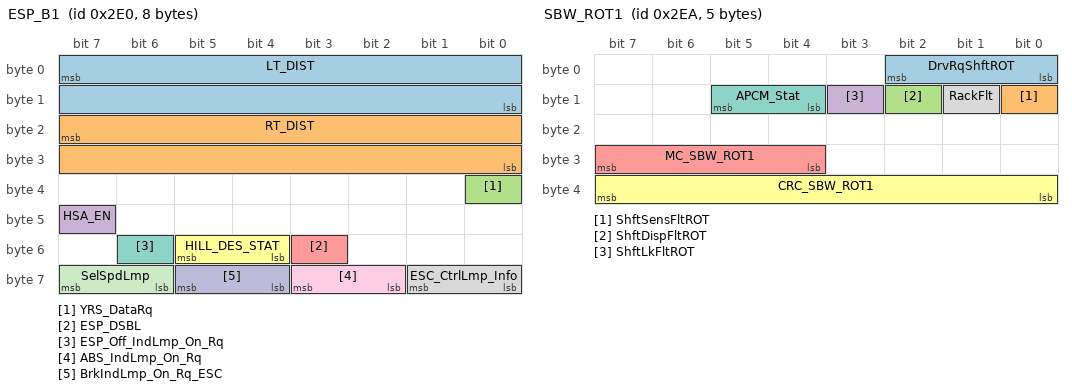
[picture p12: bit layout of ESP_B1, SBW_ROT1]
BO_ 736 ESP_B1: 8 ESC
 SG_ LT_DIST : 7|16@0+ (4,0) [0|262136] "cm" SGW,PCM,PTS,IC,ECM,CBC
 SG_ RT_DIST : 23|16@0+ (4,0) [0|262136] "cm" SGW,PCM,PTS,IC,ECM,CBC
 SG_ YRS_DataRq : 32|1@1+ (1,0) [0|0] "" SGW,ORC
 SG_ HSA_EN : 47|1@1+ (1,0) [0|0] "" SGW,IC,CBC
 SG_ ESP_DSBL : 51|1@1+ (1,0) [0|0] "" FTM,IRCM,SGW,PCM,ORC,IC,ECM,DTCM,CBC
 SG_ HILL_DES_STAT : 52|2@1+ (1,0) [0|0] "" SGW,PCM,TCM,ORC,IC,CBC
 SG_ ESP_Off_IndLmp_On_Rq : 54|1@1+ (1,0) [0|0] "" FTM,SGW,ORC,IC,DTCM,CBC
 SG_ ESC_CtrlLmp_Info : 56|2@1+ (1,0) [0|0] "" FTM,SGW,ORC,IC,ETM,DTCM
 SG_ ABS_IndLmp_On_Rq : 58|2@1+ (1,0) [0|0] "" FTM,SGW,VSIM,IC,ETM,ECM
 SG_ BrkIndLmp_On_Rq_ESC : 60|2@1+ (1,0) [0|0] "" FTM,SGW,ORC,IC,ETM
 SG_ SelSpdLmp : 62|2@1+ (1,0) [0|0] "" SGW,ORC,IC,ETM,CBC

BO_ 746 SBW_ROT1: 5 ESM
 SG_ DrvRqShftROT : 0|3@1+ (1,0) [0|0] "" FTM,SGW,TCM,RF_HUB,ETM,ECM
 SG_ ShftSensFltROT : 8|1@1+ (1,0) [0|0] "" SGW,TCM,IC
 SG_ ShftDispFltROT : 10|1@1+ (1,0) [0|0] "" SGW,TCM
 SG_ ShftLkFltROT : 11|1@1+ (1,0) [0|0] "" SGW,TCM
 SG_ MC_SBW_ROT1 : 28|4@1+ (1,0) [0|15] "" SGW,PCM,TCM
 SG_ CRC_SBW_ROT1 : 32|8@1+ (1,0) [0|0] "" SGW,PCM,TCM
 SG_ APCM_Stat : 12|2@1+ (1,0) [0|0] "" SGW,TCM
 SG_ RackFlt : 9|1@1+ (1,0) [0|0] "" SGW,TCM

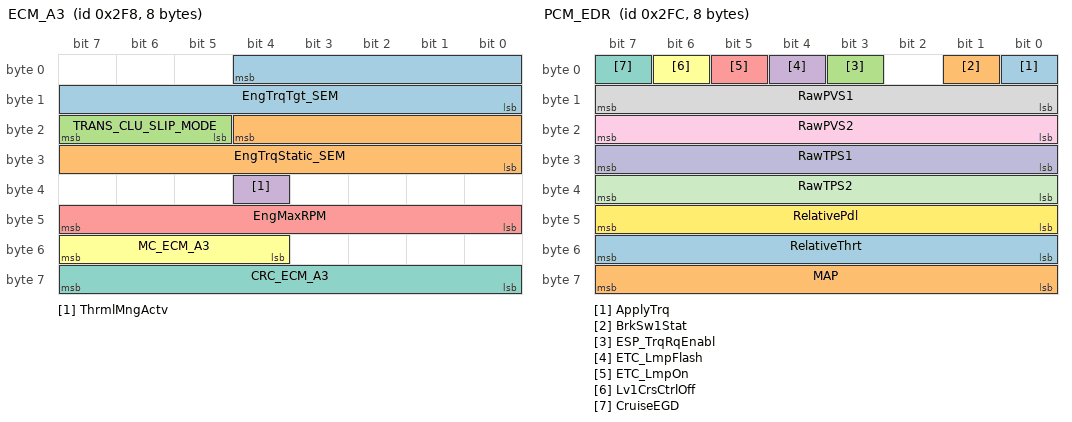
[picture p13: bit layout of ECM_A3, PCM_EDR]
BO_ 760 ECM_A3: 8 ECM
 SG_ EngTrqTgt_SEM : 4|13@0+ (0.25,-500) [-500|1547.5] "Nm" SGW,TCM
 SG_ EngTrqStatic_SEM : 20|13@0+ (0.25,-500) [-500|1547.5] "Nm" SGW,TCM
 SG_ TRANS_CLU_SLIP_MODE : 21|3@1+ (1,0) [0|0] "" SGW,TCM
 SG_ ThrmlMngActv : 36|1@1+ (1,0) [0|0] "" IRCM,SGW,TCM
 SG_ EngMaxRPM : 40|8@1+ (50,0) [0|12700] "rpm" SGW,TCM
 SG_ MC_ECM_A3 : 52|4@1+ (1,0) [0|15] "" IRCM,SGW,TCM,PTS,ESC
 SG_ CRC_ECM_A3 : 56|8@1+ (1,0) [0|0] "" IRCM,SGW,TCM,PTS,ESC

BO_ 761 TCM_EngTrq2: 8 TCM
 SG_ MC_TCM_EngTrq2 : 52|4@1+ (1,0) [0|15] "" IRCM,SGW,ECM
 SG_ CRC_TCM_EngTrq2 : 56|8@1+ (1,0) [0|0] "" IRCM,SGW,ECM

BO_ 764 PCM_EDR: 8 ECM
 SG_ ApplyTrq : 0|1@1+ (1,0) [0|0] "" SGW
 SG_ BrkSw1Stat : 1|1@1+ (1,0) [0|0] "" SGW,ETM
 SG_ ESP_TrqRqEnabl : 3|1@1+ (1,0) [0|0] "" SGW,ORC
 SG_ ETC_LmpFlash : 4|1@1+ (1,0) [0|0] "" SGW,ORC
 SG_ ETC_LmpOn : 5|1@1+ (1,0) [0|0] "" SGW,ORC
 SG_ Lv1CrsCtrlOff : 6|1@1+ (1,0) [0|0] "" SGW,ORC
 SG_ CruiseEGD : 7|1@1+ (1,0) [0|0] "" SGW
 SG_ RawPVS1 : 8|8@1+ (0.019607843,0) [0|4.98] "Volts" SGW,ORC
 SG_ RawPVS2 : 16|8@1+ (0.019607843,0) [0|4.98] "Volts" SGW,ORC
 SG_ RawTPS1 : 24|8@1+ (0.019607843,0) [0|4.98] "Volts" SGW,ORC
 SG_ RawTPS2 : 32|8@1+ (0.019607843,0) [0|4.98] "Volts" SGW,ORC
 SG_ RelativePdl : 40|8@1+ (0.019607843,0) [0|4.98] "Volts" SGW
 SG_ RelativeThrt : 48|8@1+ (0.019607843,0) [0|4.98] "Volts" SGW
 SG_ MAP : 56|8@1+ (0.8,0) [0|203.2] "kPa" FTM,SGW,ESC

BO_ 766 PCM_EDR2: 8 ECM
 SG_ VVT_ExhCam1Pos : 0|8@1+ (1,0) [1|255] "Degrees" SGW
 SG_ VVT_ExhCam2Pos : 8|8@1+ (1,0) [1|255] "Degrees" SGW
 SG_ VVT_IntCam1Pos : 16|8@1+ (1,0) [1|255] "Degrees" SGW
 SG_ VVT_IntCam2Pos : 24|8@1+ (1,0) [1|255] "Degrees" SGW
 SG_ GF_Charge : 39|16@0+ (0.2,0) [0|13106.8] "mg/cycle/cyl" SGW,ORC,ETM
 SG_ RelativeThrtPct : 48|8@1+ (0.4,0) [0|100] "%" SGW,ORC

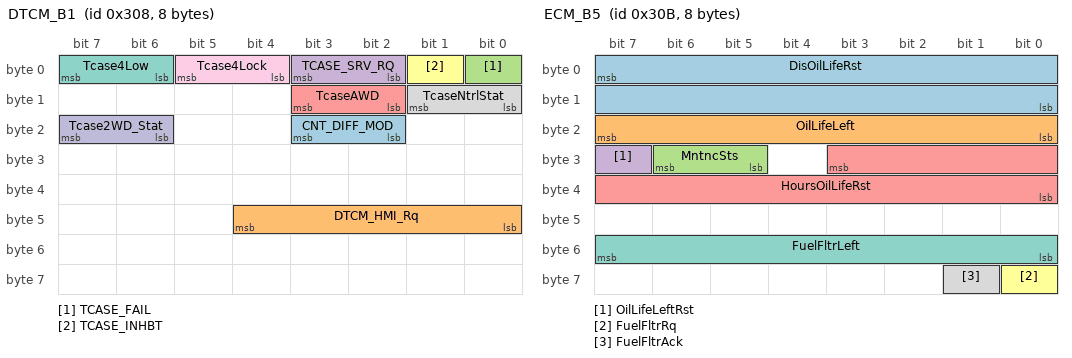
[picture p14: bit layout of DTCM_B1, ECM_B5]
BO_ 776 DTCM_B1: 8 DTCM
 SG_ CNT_DIFF_MOD : 18|2@1+ (1,0) [0|0] "" SGW
 SG_ DTCM_HMI_Rq : 40|5@1+ (1,0) [0|0] "" SGW,IC
 SG_ TCASE_FAIL : 0|1@1+ (1,0) [0|0] "" SGW,PCM,ECM
 SG_ TCASE_SRV_RQ : 2|2@1+ (1,0) [0|0] "" SGW,IC,ETM
 SG_ TcaseAWD : 10|2@1+ (1,0) [0|0] "" SGW,IC,CBC
 SG_ TCASE_INHBT : 1|1@1+ (1,0) [0|0] "" SGW
 SG_ Tcase4Low : 6|2@1+ (1,0) [0|0] "" SGW,IC,ETM,CBC
 SG_ TcaseNtrlStat : 8|2@1+ (1,0) [0|0] "" SGW,IC,ETM,CBC
 SG_ Tcase4Lock : 4|2@1+ (1,0) [0|0] "" SGW,IC,CBC
 SG_ Tcase2WD_Stat : 22|2@1+ (1,0) [0|0] "" SGW,CBC

BO_ 779 ECM_B5: 8 ECM
 SG_ DisOilLifeRst : 7|16@0+ (1,0) [0|65534] "km" FTM,SGW,IC,CBC
 SG_ OilLifeLeft : 16|8@1+ (1,0) [0|100] "%" FTM,SGW,IC,ETM
 SG_ MntncSts : 29|2@1+ (1,0) [0|0] "" FTM,SGW,IC,ETM
 SG_ OilLifeLeftRst : 31|1@1+ (1,0) [0|0] "" SGW,IC,ETM
 SG_ HoursOilLifeRst : 27|12@0+ (1,0) [0|4000] "Hours" SGW,CBC
 SG_ FuelFltrRq : 56|1@1+ (1,0) [0|0] "" SGW,IC
 SG_ FuelFltrLeft : 48|8@1+ (1,0) [0|100] "%" FTM,SGW,IC
 SG_ FuelFltrAck : 57|1@1+ (1,0) [0|0] "" SGW,IC

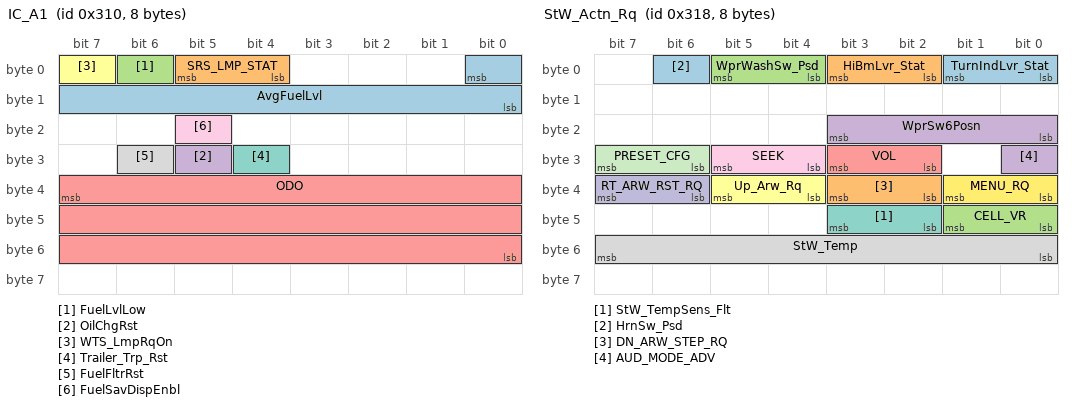
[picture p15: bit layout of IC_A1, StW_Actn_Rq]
BO_ 784 IC_A1: 8 IC
 SG_ AvgFuelLvl : 0|9@0+ (0.5,0) [0|255] "liters" FTM,SGW,PCM,VSIM,ETM,ECM,CBC
 SG_ SRS_LMP_STAT : 4|2@1+ (1,0) [0|0] "" FTM,SGW,ORC,ETM
 SG_ FuelLvlLow : 6|1@1+ (1,0) [0|0] "" FTM,SGW,PCM,ETM,ECM,CBC
 SG_ OilChgRst : 29|1@1+ (1,0) [0|0] "" SGW,PCM,ECM
 SG_ ODO : 39|24@0+ (0.1,0) [0|1677721.4] "km" FTM,TTPM,ATMM,IRCM,SGW,ITBM,FDCM,PCM,VSIM,TCM,SCCM,RF_HUB,PTS,ORC,ETM,ESM,ESC,ECM,DTCM,CBC,ASCM,AFLS
 SG_ WTS_LmpRqOn : 7|1@1+ (1,0) [0|0] "" SGW,PCM,ECM
 SG_ Trailer_Trp_Rst : 28|1@1+ (1,0) [0|0] "" SGW,ITBM
 SG_ FuelFltrRst : 30|1@1+ (1,0) [0|0] "" SGW,PCM,ECM
 SG_ FuelSavDispEnbl : 21|1@1+ (1,0) [0|0] "" SGW,CBC

BO_ 788 CFG_RQ: 3 CBC
 SG_ CFG_FEATURE : 0|8@1+ (1,0) [0|0] "" IRCM,SGW,ITBM,PCM,RF_HUB,PTS,IC,ESC,ECM,ASCM,AFLS
 SG_ CFG_STAT_RQ : 8|2@1+ (1,0) [0|0] "" IRCM,SGW,ITBM,PCM,RF_HUB,PTS,IC,ESC,ECM,ASCM,AFLS
 SG_ CFG_SET : 16|8@1+ (1,0) [0|255] "" IRCM,SGW,ITBM,PCM,RF_HUB,PTS,IC,ESC,ECM,ASCM,AFLS

BO_ 790 CFG_RQ_C: 3 IC
 SG_ CFG_FEATURE_C : 0|8@1+ (1,0) [0|0] "" IRCM,SGW,ITBM,PCM,RF_HUB,PTS,ESC,ECM,CBC,ASCM,AFLS
 SG_ CFG_STAT_RQ_C : 8|2@1+ (1,0) [0|0] "" IRCM,SGW,ITBM,PCM,RF_HUB,PTS,ESC,ECM,CBC,ASCM,AFLS
 SG_ CFG_SET_C : 16|8@1+ (1,0) [0|255] "" IRCM,SGW,ITBM,PCM,RF_HUB,PTS,ESC,ECM,CBC,ASCM,AFLS

BO_ 792 StW_Actn_Rq: 8 SCCM
 SG_ TurnIndLvr_Stat : 0|2@1+ (1,0) [0|0] "" IRCM,SGW,CBC
 SG_ HiBmLvr_Stat : 2|2@1+ (1,0) [0|0] "" SGW,ETM,CBC
 SG_ WprWashSw_Psd : 4|2@1+ (1,0) [0|0] "" SGW,ETM,CBC
 SG_ WprSw6Posn : 16|4@1+ (1,0) [0|0] "" IRCM,SGW,ETM,CBC
 SG_ VOL : 26|2@1+ (1,0) [0|0] "" SGW,CBC
 SG_ Up_Arw_Rq : 36|2@1+ (1,0) [0|0] "" SGW,IC,CBC
 SG_ StW_TempSens_Flt : 42|2@1+ (1,0) [0|0] "" SGW,CBC
 SG_ StW_Temp : 48|8@1+ (0.5,-40) [-40|85] "°C" SGW,CBC
 SG_ SEEK : 28|2@1+ (1,0) [0|0] "" SGW,CBC
 SG_ RT_ARW_RST_RQ : 38|2@1+ (1,0) [0|0] "" SGW,IC
 SG_ PRESET_CFG : 30|2@1+ (1,0) [0|0] "" SGW,CBC
 SG_ MENU_RQ : 32|2@1+ (1,0) [0|0] "" SGW,IC
 SG_ HrnSw_Psd : 6|1@1+ (1,0) [0|0] "" SGW,CBC
 SG_ DN_ARW_STEP_RQ : 34|2@1+ (1,0) [0|0] "" SGW,IC
 SG_ CELL_VR : 40|2@1+ (1,0) [0|0] "" SGW,CBC
 SG_ AUD_MODE_ADV : 24|1@1+ (1,0) [0|0] "" SGW,CBC

BO_ 799 GW_LIN_I_C2: 8 CBC
 SG_ IBS_R_Batt : 2|11@0+ (0.05,0) [0|20] "mOhm" SGW
 SG_ IBS_R_Batt_25 : 18|11@0+ (0.05,0) [0|20] "mOhm" SGW
 SG_ RainSensorFailSts : 63|1@1+ (1,0) [0|0] "" SGW,IC
 SG_ TGW_AUD_MD_CAB_DR : 3|5@1+ (1,0) [0|0] "" SGW,IC
 SG_ PSS_Display : 19|4@1+ (1,0) [0|0] "" SGW,IC

BO_ 804 CBC_PT4: 8 CBC
 SG_ TurnLmp_FL_Flt : 13|1@1+ (1,0) [0|0] "" FTM,SGW,IC,ETM
 SG_ TurnLmp_FR_Flt : 14|1@1+ (1,0) [0|0] "" FTM,SGW,IC,ETM
 SG_ TurnLmp_RL_Flt : 24|1@1+ (1,0) [0|0] "" FTM,SGW,IC,ETM
 SG_ TurnLmp_RR_Flt : 25|1@1+ (1,0) [0|0] "" FTM,SGW,IC,ETM
 SG_ ACC_DLY_ACT : 26|1@1+ (1,0) [0|0] "" SGW,IC
 SG_ RemSt_Inhibit : 32|8@1+ (1,0) [0|0] "" SGW,IC,ETM
 SG_ WPR_SYS_OFF : 40|1@1+ (1,0) [0|0] "" IRCM,SGW,ESC,DTCM
 SG_ WPR_SYS_LOW : 41|1@1+ (1,0) [0|0] "" IRCM,SGW,ESC,DTCM
 SG_ WPR_SYS_HIGH : 42|1@1+ (1,0) [0|0] "" IRCM,SGW,ESC,DTCM
 SG_ WPR_SYS_INT : 43|1@1+ (1,0) [0|0] "" IRCM,SGW,ESC,DTCM
 SG_ WPR_SYS_AUTO : 44|1@1+ (1,0) [0|0] "" IRCM,SGW,ESC,DTCM
 SG_ WPR_SYS_MIST : 45|1@1+ (1,0) [0|0] "" IRCM,SGW,ESC,DTCM
 SG_ WPR_SYS_WASH : 46|1@1+ (1,0) [0|0] "" IRCM,SGW,ESC,DTCM
 SG_ WPR_SYS_FLT : 47|1@1+ (1,0) [0|0] "" IRCM,SGW,ESC,DTCM
 SG_ AirSusp_DnSw : 18|2@1+ (1,0) [0|0] "" SGW,ASCM
 SG_ HdAjar : 10|1@1+ (1,0) [0|0] "" SGW,IC,ETM
 SG_ CargoLampOn : 27|1@1+ (1,0) [0|0] "" SGW,IC
 SG_ WTS_Active : 8|1@1+ (1,0) [0|0] "" SGW,CBC
 SG_ CBC_WTS_AS : 9|1@1+ (1,0) [0|0] "" SGW,IC

BO_ 808 TGW_DATA_IC: 8 CBC
 SG_ TGW_GrpNum_IC : 4|4@1+ (1,1) [1|16] "Group" SGW,IC
 SG_ TGW_GrpTyp_IC : 8|6@1+ (1,0) [1|40] "Text" SGW,IC
 SG_ TGW_HiGrpMark_IC : 14|1@1+ (1,0) [0|0] "" SGW,IC
 SG_ TGW_TEXT_IC : 23|48@0+ (1,0) [0|0] "" SGW,IC

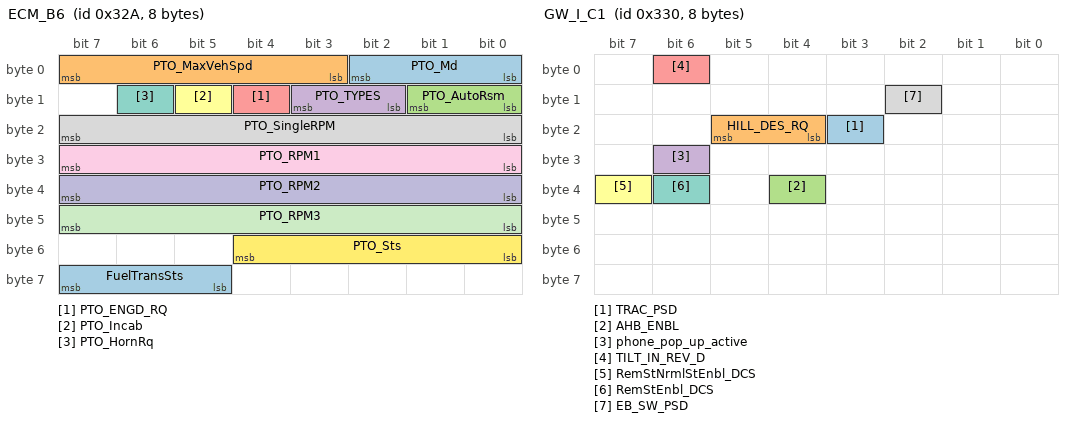
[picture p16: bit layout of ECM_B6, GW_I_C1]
BO_ 810 ECM_B6: 8 ECM
 SG_ PTO_Md : 0|3@1+ (1,0) [0|0] "" SGW,VSIM,TCM,IC
 SG_ PTO_MaxVehSpd : 3|5@1+ (1,0) [0|0] "" IRCM,SGW,IC
 SG_ PTO_AutoRsm : 8|2@1+ (1,0) [0|0] "" SGW,IC
 SG_ PTO_TYPES : 10|2@1+ (1,0) [0|0] "" SGW,TCM,IC
 SG_ PTO_ENGD_RQ : 12|1@1+ (1,0) [0|0] "" SGW,VSIM,TCM
 SG_ PTO_Incab : 13|1@1+ (1,0) [0|0] "" SGW
 SG_ PTO_HornRq : 14|1@1+ (1,0) [0|0] "" SGW,CBC
 SG_ PTO_SingleRPM : 16|8@1+ (25,600) [600|6950] "rpm" SGW,IC
 SG_ PTO_RPM1 : 24|8@1+ (25,600) [600|6950] "rpm" SGW,IC
 SG_ PTO_RPM2 : 32|8@1+ (25,600) [600|6950] "rpm" SGW,IC
 SG_ PTO_RPM3 : 40|8@1+ (25,600) [600|6950] "rpm" SGW,IC
 SG_ PTO_Sts : 48|5@1+ (1,0) [0|0] "" FTM,IRCM,SGW,VSIM,IC,CBC
 SG_ FuelTransSts : 61|3@1+ (1,0) [0|0] "" SGW,IC

BO_ 816 GW_I_C1: 8 CBC
 SG_ TRAC_PSD : 19|1@1+ (1,0) [0|0] "" SGW,ETM,ESC
 SG_ HILL_DES_RQ : 20|2@1+ (1,0) [0|0] "" SGW,ESC
 SG_ AHB_ENBL : 36|1@1+ (1,0) [0|0] "" SGW,IC
 SG_ phone_pop_up_active : 30|1@1+ (1,0) [0|0] "" SGW,IC
 SG_ TILT_IN_REV_D : 6|1@1+ (1,0) [0|0] "" SGW,IC
 SG_ RemStNrmlStEnbl_DCS : 39|1@1+ (1,0) [0|0] "" SGW,IC
 SG_ RemStEnbl_DCS : 38|1@1+ (1,0) [0|0] "" SGW,IC
 SG_ EB_SW_PSD : 10|1@1+ (1,0) [0|0] "" SGW,PCM,ECM

BO_ 820 CBC_PT1: 8 CBC
 SG_ FT_FOG_RQ : 2|1@1+ (1,0) [0|0] "" FTM,SGW,IC,ETM
 SG_ REV_GEAR : 4|1@1+ (1,0) [0|0] "" SGW,RF_HUB,ORC,IC,ESC,DTCM,ASCM
 SG_ DR_LK_STAT : 5|2@1+ (1,0) [0|0] "" SGW,VSIM
 SG_ FOB_SrchRq : 8|2@1+ (1,0) [0|0] "" SGW,RF_HUB
 SG_ AHB_ACT : 14|1@1+ (1,0) [0|0] "" SGW,IC
 SG_ PARK_LMP_ON : 16|1@1+ (1,0) [0|0] "" SGW,VSIM,IC,ETM
 SG_ DRV_AJAR : 17|1@1+ (1,0) [0|0] "" FTM,IRCM,SGW,PCM,VSIM,TCM,RF_HUB,IC,ETM,ESC,ECM,ASCM
 SG_ PSG_AJAR : 18|1@1+ (1,0) [0|0] "" FTM,SGW,PCM,VSIM,RF_HUB,IC,ETM,ESC,ECM,ASCM
 SG_ L_R_AJAR : 19|1@1+ (1,0) [0|0] "" FTM,SGW,PCM,VSIM,RF_HUB,IC,ETM,ECM,ASCM
 SG_ R_R_AJAR : 20|1@1+ (1,0) [0|0] "" FTM,SGW,PCM,VSIM,RF_HUB,IC,ETM,ECM,ASCM
 SG_ TLG_AJAR : 22|1@1+ (1,0) [0|0] "" FTM,SGW,ETM
 SG_ PARK_BRK_EGD : 23|1@1+ (1,0) [0|0] "" SGW,PCM,VSIM,RF_HUB,ORC,IC,ESC,ECM,ASCM
 SG_ IGN_OFF_TIME_LNG : 27|12@0+ (1,0) [0|4080] "min" FTM,IRCM,SGW,PCM,TCM,RF_HUB,ESC,DTCM
 SG_ SHIP_STAT : 28|2@1+ (1,0) [0|0] "" IRCM,SGW,PCM,RF_HUB,IC,ECM,ASCM
 SG_ TurnInd_LT_ON : 30|1@1+ (1,0) [0|0] "" FTM,SGW,VSIM,IC,ETM
 SG_ TurnInd_RT_ON : 31|1@1+ (1,0) [0|0] "" FTM,SGW,VSIM,IC,ETM
 SG_ DAY_LGT_MD : 40|1@1+ (1,0) [0|0] "" SGW,SCCM,RF_HUB,IC,ESM
 SG_ PANEL_INTS : 48|8@1+ (0.5,0) [0|100] "%" SGW,VSIM,SCCM,RF_HUB,IC,ESM
 SG_ FT_WPR_NOT_PRK : 56|1@1+ (1,0) [0|0] "" IRCM,SGW,PCM,ECM,DTCM
 SG_ LOBEAM_ON : 57|1@1+ (1,0) [0|0] "" SGW,PCM,VSIM,ETM,ECM,AFLS
 SG_ HIBEAM_ON : 58|1@1+ (1,0) [0|0] "" FTM,IRCM,SGW,PCM,VSIM,IC,ETM,ECM
 SG_ BRK_FLUID_LO : 62|1@1+ (1,0) [0|0] "" FTM,SGW,IC,ETM,ESC
 SG_ WASH_FLUID_LO : 63|1@1+ (1,0) [0|0] "" FTM,SGW,IC,ETM
 SG_ R_FOG_RQ : 3|1@1+ (1,0) [0|0] "" SGW,IC,ETM
 SG_ PTC_REL1_STAT : 42|2@1+ (1,0) [0|0] "" SGW,PCM,ECM
 SG_ PTC_REL2_STAT : 44|2@1+ (1,0) [0|0] "" SGW,PCM,ECM
 SG_ PTC_REL3_STAT : 46|2@1+ (1,0) [0|0] "" SGW,PCM,ECM
 SG_ PoliceStlthMdAct : 59|1@1+ (1,0) [0|0] "" SGW,RF_HUB,IC,ESM

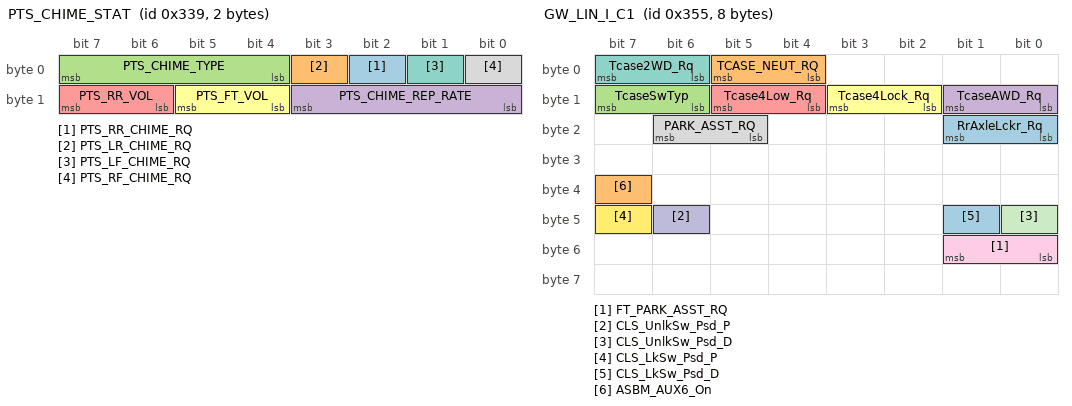
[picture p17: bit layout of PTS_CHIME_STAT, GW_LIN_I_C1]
BO_ 825 PTS_CHIME_STAT: 2 PTS
 SG_ PTS_RR_CHIME_RQ : 2|1@1+ (1,0) [0|0] "" SGW,CBC
 SG_ PTS_LR_CHIME_RQ : 3|1@1+ (1,0) [0|0] "" SGW,CBC
 SG_ PTS_CHIME_TYPE : 4|4@1+ (1,0) [0|0] "" SGW,CBC
 SG_ PTS_CHIME_REP_RATE : 8|4@1+ (1,0) [0|15] "Hz" SGW,CBC
 SG_ PTS_RR_VOL : 14|2@1+ (1,0) [0|0] "" SGW,IC,CBC
 SG_ PTS_FT_VOL : 12|2@1+ (1,0) [0|0] "" SGW,IC,CBC
 SG_ PTS_LF_CHIME_RQ : 1|1@1+ (1,0) [0|0] "" SGW,CBC
 SG_ PTS_RF_CHIME_RQ : 0|1@1+ (1,0) [0|0] "" SGW,CBC

BO_ 826 PTS_1: 8 PTS
 SG_ PTS_RR_NA : 4|1@1+ (1,0) [0|0] "" SGW,IC
 SG_ PTS_SRV_RQ : 5|1@1+ (1,0) [0|0] "" SGW,IC
 SG_ PTS_AlrRL : 24|4@1+ (1,0) [0|0] "" SGW,IC,CBC
 SG_ PTS_GraphicRL : 30|2@1+ (1,0) [0|0] "" SGW,IC
 SG_ PTS_AlrRR : 32|4@1+ (1,0) [0|0] "" SGW,IC,CBC
 SG_ PTS_GraphicRR : 38|2@1+ (1,0) [0|0] "" SGW,IC
 SG_ PTS_AlrRC : 48|4@1+ (1,0) [0|0] "" SGW,IC,CBC
 SG_ PTS_GraphicRC : 54|2@1+ (1,0) [0|0] "" SGW,IC
 SG_ PTS_RR_SRV : 59|1@1+ (1,0) [0|0] "" FTM,SGW,IC,ETM
 SG_ PTS_STAT : 60|2@1+ (1,0) [0|0] "" SGW,ETM,CBC
 SG_ PTS_AlrFC : 40|4@1+ (1,0) [0|0] "" SGW,IC,CBC
 SG_ PTS_AlrFL : 8|4@1+ (1,0) [0|0] "" SGW,IC,CBC
 SG_ PTS_AlrFR : 16|4@1+ (1,0) [0|0] "" SGW,IC,CBC
 SG_ PTS_FT_NA : 3|1@1+ (1,0) [0|0] "" SGW,IC
 SG_ PTS_FT_SRV : 58|1@1+ (1,0) [0|0] "" FTM,SGW,IC,ETM
 SG_ PTS_GraphicFC : 46|2@1+ (1,0) [0|0] "" SGW,IC
 SG_ PTS_GraphicFL : 14|2@1+ (1,0) [0|0] "" SGW,IC
 SG_ PTS_GraphicFR : 22|2@1+ (1,0) [0|0] "" SGW,IC

BO_ 832 IC_500Cyc: 8 IC
 SG_ VehSpd_MPH : 47|1@1+ (1,0) [0|0] "" SGW,PCM,ECM,CBC
 SG_ VehSpdDisp : 55|16@0+ (1,0) [0|65534] "" SGW,CBC
 SG_ xtended_AvgFuelLvl : 19|12@0+ (0.5,0) [0|2047] "liters" SGW,PCM,ECM,CBC

BO_ 838 AS_CHIME_STAT: 2 IRCM
 SG_ AS_RF_CHIME_RQ : 0|1@1+ (1,0) [0|0] "" SGW,CBC
 SG_ AS_LF_CHIME_RQ : 1|1@1+ (1,0) [0|0] "" SGW,CBC
 SG_ AS_CHIME_TYPE : 4|4@1+ (1,0) [0|0] "" SGW,ORC,CBC
 SG_ AS_CHIME_REP_RATE : 8|4@1+ (1,0) [0|15] "Hz" SGW,CBC

BO_ 840 ESP_C1: 8 ESC
 SG_ FailSafeError : 7|16@0+ (1,0) [0|65534] "" IRCM,SGW

BO_ 848 Clock_Date: 8 CBC
 SG_ DateTmSec : 0|8@1+ (1,0) [0|59] "sec" SGW,ITBM,IC
 SG_ DateTmMinute : 8|8@1+ (1,0) [0|59] "min" SGW,ITBM,VSIM,RF_HUB,IC
 SG_ DateTmHour : 16|8@1+ (1,0) [0|23] "Hours" SGW,ITBM,VSIM,RF_HUB,IC
 SG_ DateTmYear : 31|16@0+ (1,0) [0|65534] "Years" SGW,ITBM,RF_HUB,IC
 SG_ DateTmMonth : 40|8@1+ (1,0) [1|12] "Months" SGW,ITBM,RF_HUB,IC
 SG_ DateTmDay : 48|8@1+ (1,0) [1|31] "Days" SGW,ITBM,RF_HUB,IC
 SG_ DateTmFormat : 56|3@1+ (1,0) [0|0] "" SGW,ITBM,IC

BO_ 850 ECM_APPL2: 8 DIAGNOST
 SG_ ECM_APPL2 : 7|64@0+ (1,0) [0|0] "" PCM,ECM

BO_ 853 GW_LIN_I_C1: 8 CBC
 SG_ RrAxleLckr_Rq : 16|2@1+ (1,0) [0|0] "" SGW,FDCM
 SG_ TCASE_NEUT_RQ : 4|2@1+ (1,0) [0|0] "" SGW,DTCM
 SG_ TcaseSwTyp : 14|2@1+ (1,0) [0|0] "" SGW,DTCM
 SG_ TcaseAWD_Rq : 8|2@1+ (1,0) [0|0] "" SGW,DTCM
 SG_ Tcase4Low_Rq : 12|2@1+ (1,0) [0|0] "" SGW,DTCM
 SG_ Tcase4Lock_Rq : 10|2@1+ (1,0) [0|0] "" SGW,DTCM
 SG_ Tcase2WD_Rq : 6|2@1+ (1,0) [0|0] "" SGW,DTCM
 SG_ PARK_ASST_RQ : 21|2@1+ (1,0) [0|0] "" SGW,PTS
 SG_ FT_PARK_ASST_RQ : 48|2@1+ (1,0) [0|0] "" SGW,PTS
 SG_ CLS_UnlkSw_Psd_P : 46|1@1+ (1,0) [0|0] "" SGW,VSIM
 SG_ CLS_UnlkSw_Psd_D : 40|1@1+ (1,0) [0|0] "" SGW,VSIM
 SG_ CLS_LkSw_Psd_P : 47|1@1+ (1,0) [0|0] "" SGW,VSIM
 SG_ CLS_LkSw_Psd_D : 41|1@1+ (1,0) [0|0] "" SGW,VSIM
 SG_ ASBM_AUX6_On : 39|1@1+ (1,0) [0|0] "" SGW,PCM,ECM

BO_ 856 COMPASS_A1: 4 CBC
 SG_ CMP_DIR : 0|4@1+ (1,0) [0|0] "" FTM,SGW,IC
 SG_ VAR_VAL : 4|4@1+ (1,1) [1|15] "" SGW,IC
 SG_ CMP_DIR_RAW : 8|9@0+ (1,0) [0|359] "Degrees" SGW
 SG_ IN_CAL_MD : 11|1@1+ (1,0) [0|0] "" SGW,IC

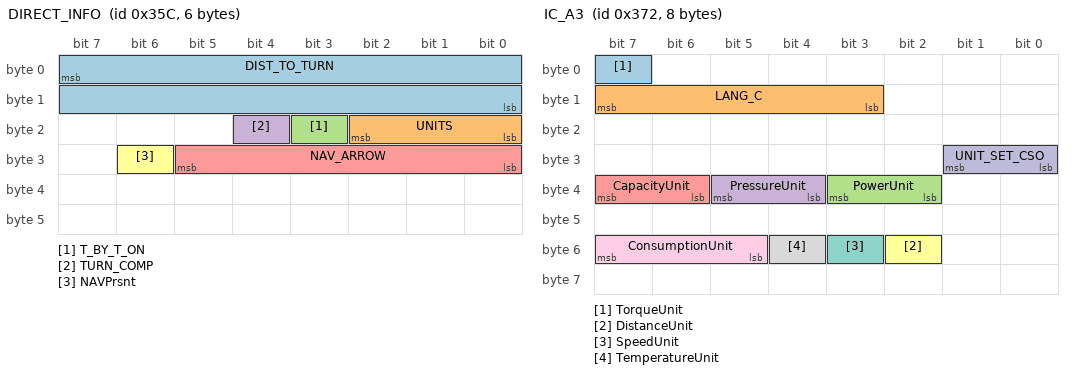
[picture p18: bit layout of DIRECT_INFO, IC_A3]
BO_ 860 DIRECT_INFO: 6 CBC
 SG_ DIST_TO_TURN : 7|16@0+ (1,0) [0|65534] "" SGW,IC
 SG_ UNITS : 16|3@1+ (1,0) [0|0] "" SGW,IC
 SG_ T_BY_T_ON : 19|1@1+ (1,0) [0|0] "" SGW,IC
 SG_ TURN_COMP : 20|1@1+ (1,0) [0|0] "" SGW,IC
 SG_ NAV_ARROW : 24|6@1+ (1,0) [1|63] "Arrow" SGW,IC
 SG_ NAVPrsnt : 30|1@1+ (1,0) [0|0] "" SGW,IC

BO_ 863 ECM_B8: 8 ECM
 SG_ RevOilLifeRst : 55|16@0+ (1000,0) [0|65534000] "Rev's" SGW,CBC

BO_ 864 ECM_APPL1: 8 ECM
 SG_ ECM_APPL1 : 7|64@0+ (1,0) [0|0] "" SGW,DIAGNOST

BO_ 872 TCM_HSA: 8 TCM
 SG_ TCM_HSA : 7|64@0+ (1,0) [0|0] "" SGW,DIAGNOST

BO_ 880 ECM_APPL3: 8 ECM
 SG_ ECM_APPL3 : 7|64@0+ (1,0) [0|0] "" SGW,DIAGNOST

BO_ 882 IC_A3: 8 IC
 SG_ TorqueUnit : 7|1@1+ (1,0) [0|0] "" SGW,CBC
 SG_ LANG_C : 11|5@1+ (1,0) [0|0] "" SGW,CBC
 SG_ PowerUnit : 34|2@1+ (1,0) [0|0] "" SGW,CBC
 SG_ PressureUnit : 36|2@1+ (1,0) [0|0] "" SGW,CBC
 SG_ CapacityUnit : 38|2@1+ (1,0) [0|0] "" SGW,CBC
 SG_ DistanceUnit : 50|1@1+ (1,0) [0|0] "" FTM,SGW,PCM,ECM,CBC
 SG_ SpeedUnit : 51|1@1+ (1,0) [0|0] "" IRCM,SGW,FDCM,PCM,IC,ECM,CBC
 SG_ TemperatureUnit : 52|1@1+ (1,0) [0|0] "" SGW,CBC
 SG_ ConsumptionUnit : 53|3@1+ (1,0) [0|0] "" FTM,SGW,CBC
 SG_ UNIT_SET_CSO : 24|2@1+ (1,0) [0|0] "" SGW,CBC

BO_ 888 TCM_HSB: 8 TCM
 SG_ TCM_HSB : 7|64@0+ (1,0) [0|0] "" SGW,DIAGNOST

BO_ 896 ECM_APPL4: 8 ECM
 SG_ ECM_APPL4 : 7|64@0+ (1,0) [0|0] "" SGW,DIAGNOST

BO_ 897 VehCfg7: 8 CBC
 SG_ VC_VehCfg7_Stat : 0|2@1+ (1,0) [0|0] "" IRCM,SGW,FDCM,PCM,TCM,SCCM,RF_HUB,PTS,ORC,IC,ESC,ECM,DTCM,ASCM
 SG_ VC_LDW : 2|1@1+ (1,0) [0|0] "" SGW,RF_HUB,IC
 SG_ VC_TrnsDrvMdPrsnt : 3|1@1+ (1,0) [0|0] "" SGW,TCM,RF_HUB
 SG_ VC_PdlsMdPrsnt : 4|1@1+ (1,0) [0|0] "" SGW,TCM,RF_HUB
 SG_ VC_DST_Present : 5|1@1+ (1,0) [0|0] "" SGW,RF_HUB
 SG_ VC_STP_PRSNT : 6|1@1+ (1,0) [0|0] "" SGW,RF_HUB
 SG_ VC_eShifter_Prsnt : 7|1@1+ (1,0) [0|0] "" SGW,RF_HUB
 SG_ VC_TransType : 8|6@1+ (1,0) [0|0] "" SGW,RF_HUB,IC,ESC
 SG_ VC_AS_ERS : 14|2@1+ (1,0) [0|0] "" SGW,TCM,RF_HUB,IC
 SG_ VC_FullSpeedRange_FCW : 18|1@1+ (1,0) [0|0] "" IRCM,SGW,RF_HUB,IC,ESC
 SG_ VC_ACC_Type : 19|2@1+ (1,0) [0|0] "" IRCM,SGW,PCM,TCM,RF_HUB,IC,ESC,ECM
 SG_ VC_SuspPrsnt : 21|1@1+ (1,0) [0|0] "" SGW,RF_HUB,ASCM
 SG_ VC_DampingPrsnt : 22|1@1+ (1,0) [0|0] "" SGW,RF_HUB
 SG_ VC_AxleLockerPrsnt : 26|2@1+ (1,0) [0|0] "" SGW,FDCM,RF_HUB,IC
 SG_ VC_PBTyp : 29|3@1+ (1,0) [0|0] "" IRCM,SGW,RF_HUB
 SG_ VC_RedKey : 24|1@1+ (1,0) [0|0] "" SGW,RF_HUB
 SG_ VC_TeenKey : 16|1@1+ (1,0) [0|0] "" SGW,RF_HUB
 SG_ VC_TPMS_Configuration : 32|3@1+ (1,0) [0|0] "" SGW,RF_HUB,IC
 SG_ VC_Trans_Equipped : 28|1@1+ (1,0) [0|0] "" IRCM,SGW,RF_HUB,PTS,ORC,IC,ESC
 SG_ VC_TSBM_Prsnt : 39|1@1+ (1,0) [0|0] "" SGW,RF_HUB
 SG_ VC_SVC_Prsnt : 17|1@1+ (1,0) [0|0] "" SGW,RF_HUB
 SG_ VC_Trans_N_Hold_Prsnt : 23|1@1+ (1,0) [0|0] "" SGW,RF_HUB
 SG_ VC_ABSM : 25|1@1+ (1,0) [0|0] "" SGW,RF_HUB
 SG_ VC_HybridType : 36|3@1+ (1,0) [0|0] "" SGW,RF_HUB
 SG_ VC_SUNR_Prsnt : 47|1@1+ (1,0) [0|0] "" SGW,RF_HUB
 SG_ VC_Temp_Display_Resolution : 42|1@1+ (1,0) [0|0] "" SGW,RF_HUB
 SG_ VC_Suspension_Type : 60|4@1+ (1,0) [0|0] "" SGW,RF_HUB
 SG_ VC_SmartAlternator : 35|1@1+ (1,0) [0|0] "" SGW,RF_HUB
 SG_ VC_PTCPrsnt : 43|1@1+ (1,0) [0|0] "" SGW,PCM,RF_HUB,ECM
 SG_ VC_MOC_Type : 45|2@1+ (1,0) [0|0] "" SGW,RF_HUB
 SG_ VC_Glovebox : 44|1@1+ (1,0) [0|0] "" SGW,RF_HUB
 SG_ VC_Brake_Type : 56|4@1+ (1,0) [0|0] "" SGW,RF_HUB
 SG_ VC_AGSprsnt : 41|1@1+ (1,0) [0|0] "" SGW,RF_HUB
 SG_ VC_ADR_PRSNT : 40|1@1+ (1,0) [0|0] "" SGW,RF_HUB
 SG_ VC_GlareFree_Prsnt : 48|1@1+ (1,0) [0|0] "" SGW,RF_HUB
 SG_ VC_Vehicle_Package : 50|3@1+ (1,0) [0|0] "" SGW,RF_HUB
 SG_ VC_TrafficSignInfo : 53|1@1+ (1,0) [0|0] "" SGW,RF_HUB
 SG_ VC_PAD_Lamp_Ctrl : 49|1@1+ (1,0) [0|0] "" SGW,RF_HUB
 SG_ VC_LDW_Audio : 55|1@1+ (1,0) [0|0] "" SGW,RF_HUB
 SG_ VC_LaneCentering : 54|1@1+ (1,0) [0|0] "" SGW,RF_HUB

BO_ 898 VehCfgBu7: 8 RF_HUB
 SG_ VC_BU_VehCfg7_Stat : 0|2@1+ (1,0) [0|0] "" SGW,CBC
 SG_ VC_BU_LDW : 2|1@1+ (1,0) [0|0] "" SGW,CBC
 SG_ VC_BU_TrnsDrvMdPrsnt : 3|1@1+ (1,0) [0|0] "" SGW,CBC
 SG_ VC_BU_PdlsMdPrsnt : 4|1@1+ (1,0) [0|0] "" SGW,CBC
 SG_ VC_BU_DST_Present : 5|1@1+ (1,0) [0|0] "" SGW,CBC
 SG_ VC_BU_STP_PRSNT : 6|1@1+ (1,0) [0|0] "" SGW,CBC
 SG_ VC_BU_eShifter_Prsnt : 7|1@1+ (1,0) [0|0] "" SGW,CBC
 SG_ VC_BU_TransType : 8|6@1+ (1,0) [0|0] "" SGW,CBC
 SG_ VC_BU_AS_ERS : 14|2@1+ (1,0) [0|0] "" SGW,CBC
 SG_ VC_BU_FullSpeedRange_FCW : 18|1@1+ (1,0) [0|0] "" SGW,CBC
 SG_ VC_BU_ACC_Type : 19|2@1+ (1,0) [0|0] "" SGW,CBC
 SG_ VC_BU_SuspPrsnt : 21|1@1+ (1,0) [0|0] "" SGW,CBC
 SG_ VC_BU_DampingPrsnt : 22|1@1+ (1,0) [0|0] "" SGW,CBC
 SG_ VC_BU_AxleLockerPrsnt : 26|2@1+ (1,0) [0|0] "" SGW,CBC
 SG_ VC_BU_PBTyp : 29|3@1+ (1,0) [0|0] "" SGW,CBC
 SG_ VC_BU_RedKey : 24|1@1+ (1,0) [0|0] "" SGW,CBC
 SG_ VC_BU_TeenKey : 16|1@1+ (1,0) [0|0] "" SGW,CBC
 SG_ VC_BU_TPMS_Configuration : 32|3@1+ (1,0) [0|0] "" SGW,CBC
 SG_ VC_BU_Trans_Equipped : 28|1@1+ (1,0) [0|0] "" SGW,CBC
 SG_ VC_BU_TSBM_Prsnt : 39|1@1+ (1,0) [0|0] "" SGW,CBC
 SG_ VC_BU_SVC_Prsnt : 17|1@1+ (1,0) [0|0] "" SGW,CBC
 SG_ VC_BU_Trans_N_Hold_Prsnt : 23|1@1+ (1,0) [0|0] "" SGW,CBC
 SG_ VC_BU_ABSM : 25|1@1+ (1,0) [0|0] "" SGW,CBC
 SG_ VC_BU_HybridType : 36|3@1+ (1,0) [0|0] "" SGW,CBC
 SG_ VC_BU_SUNR_Prsnt : 47|1@1+ (1,0) [0|0] "" SGW,CBC
 SG_ VC_BU_Temp_Display_Resolution : 42|1@1+ (1,0) [0|0] "" SGW,CBC
 SG_ VC_BU_Suspension_Type : 60|4@1+ (1,0) [0|0] "" SGW,CBC
 SG_ VC_BU_SmartAlternator : 35|1@1+ (1,0) [0|0] "" SGW,CBC
 SG_ VC_BU_PTCPrsnt : 43|1@1+ (1,0) [0|0] "" SGW,CBC
 SG_ VC_BU_MOC_Type : 45|2@1+ (1,0) [0|0] "" SGW,CBC
 SG_ VC_BU_Glovebox : 44|1@1+ (1,0) [0|0] "" SGW,CBC
 SG_ VC_BU_Brake_Type : 56|4@1+ (1,0) [0|0] "" SGW,CBC
 SG_ VC_BU_AGSprsnt : 41|1@1+ (1,0) [0|0] "" SGW,CBC
 SG_ VC_BU_ADR_PRSNT : 40|1@1+ (1,0) [0|0] "" SGW,CBC
 SG_ VC_BU_Vehicle_Package : 50|3@1+ (1,0) [0|0] "" SGW,CBC
 SG_ VC_BU_TrafficSignInfo : 53|1@1+ (1,0) [0|0] "" SGW,CBC
 SG_ VC_BU_PAD_Lamp_Ctrl : 49|1@1+ (1,0) [0|0] "" SGW,CBC
 SG_ VC_BU_GlareFree_Prsnt : 48|1@1+ (1,0) [0|0] "" SGW,CBC
 SG_ VC_BU_LDW_Audio : 55|1@1+ (1,0) [0|0] "" SGW,CBC
 SG_ VC_BU_LaneCentering : 54|1@1+ (1,0) [0|0] "" SGW,CBC

BO_ 904 TCM_HSC: 8 TCM
 SG_ TCM_HSC : 7|64@0+ (1,0) [0|0] "" SGW,DIAGNOST

BO_ 912 ECM_APPL5: 8 ECM
 SG_ ECM_APPL5 : 7|64@0+ (1,0) [0|0] "" SGW,DIAGNOST

BO_ 920 TCM_HSD: 8 TCM
 SG_ TCM_HSD : 7|64@0+ (1,0) [0|0] "" SGW,DIAGNOST

BO_ 928 ECM_APPL6: 8 ECM
 SG_ ECM_APPL6 : 7|64@0+ (1,0) [0|0] "" SGW,DIAGNOST

BO_ 936 ECM_APPL7: 8 ECM
 SG_ ECM_APPL7 : 7|64@0+ (1,0) [0|0] "" SGW,DIAGNOST

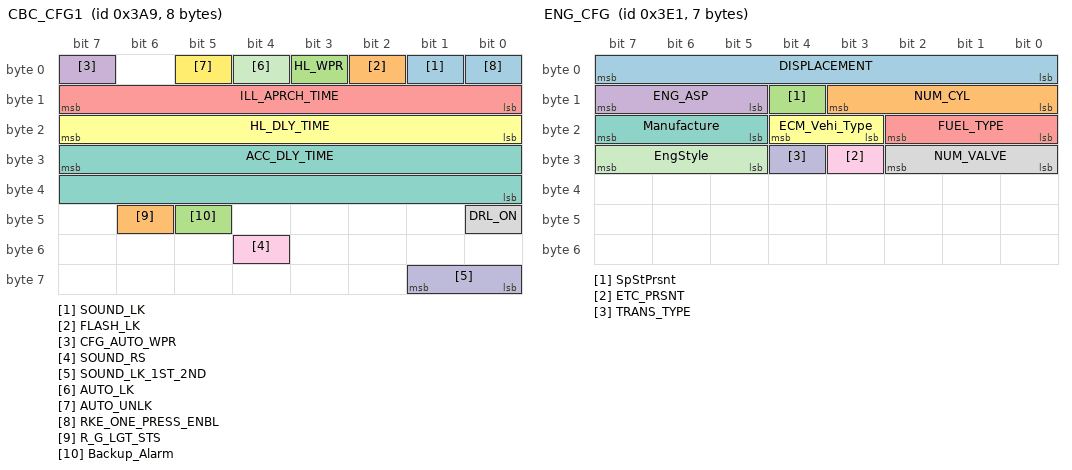
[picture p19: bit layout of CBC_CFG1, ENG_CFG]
BO_ 937 CBC_CFG1: 8 CBC
 SG_ SOUND_LK : 1|1@1+ (1,0) [0|0] "" SGW
 SG_ FLASH_LK : 2|1@1+ (1,0) [0|0] "" SGW,IC
 SG_ HL_WPR : 3|1@1+ (1,0) [0|0] "" SGW,IC
 SG_ CFG_AUTO_WPR : 7|1@1+ (1,0) [0|0] "" SGW,IC
 SG_ ILL_APRCH_TIME : 8|8@1+ (1,0) [0|254] "sec" SGW,IC
 SG_ HL_DLY_TIME : 16|8@1+ (1,0) [0|254] "sec" SGW,IC
 SG_ ACC_DLY_TIME : 31|16@0+ (1,0) [0|65534] "sec" SGW,IC
 SG_ DRL_ON : 40|1@1+ (1,0) [0|0] "" SGW,IC
 SG_ SOUND_RS : 52|1@1+ (1,0) [0|0] "" SGW,IC
 SG_ SOUND_LK_1ST_2ND : 56|2@1+ (1,0) [0|0] "" SGW,IC
 SG_ AUTO_LK : 4|1@1+ (1,0) [0|0] "" SGW,IC
 SG_ AUTO_UNLK : 5|1@1+ (1,0) [0|0] "" SGW,IC
 SG_ RKE_ONE_PRESS_ENBL : 0|1@1+ (1,0) [0|0] "" SGW,IC
 SG_ R_G_LGT_STS : 46|1@1+ (1,0) [0|0] "" SGW,IC
 SG_ Backup_Alarm : 45|1@1+ (1,0) [0|0] "" SGW,IC

BO_ 944 TCM_APPL2: 8 DIAGNOST
 SG_ TCM_APPL2 : 7|64@0+ (1,0) [0|0] "" PCM,TCM

BO_ 945 TCM_APPL1: 8 TCM
 SG_ TCM_APPL1 : 7|64@0+ (1,0) [0|0] "" SGW,DIAGNOST

BO_ 946 TCM_APPL3: 8 TCM
 SG_ TCM_APPL3 : 7|64@0+ (1,0) [0|0] "" SGW,DIAGNOST

BO_ 947 VehCfgCSM1: 8 CBC
 SG_ VC_VehCfgCSO1_Stat : 0|2@1+ (1,0) [0|0] "" SGW,RF_HUB,IC
 SG_ VC_PRK_AST_CSO : 2|2@1+ (1,0) [0|0] "" SGW,RF_HUB,IC
 SG_ VC_PRK_AST_BRK_CSO : 4|1@1+ (1,0) [0|0] "" SGW,RF_HUB
 SG_ VC_PRK_FT_VOL_CSO : 5|1@1+ (1,0) [0|0] "" SGW,RF_HUB,IC
 SG_ VC_PRK_RR_VOL_CSO : 6|1@1+ (1,0) [0|0] "" SGW,RF_HUB,IC
 SG_ VC_EPS_CSO : 7|1@1+ (1,0) [0|0] "" SGW,RF_HUB
 SG_ VC_FCW_CSO : 8|2@1+ (1,0) [0|0] "" SGW,RF_HUB
 SG_ VC_FCW_BRK_CSO : 10|1@1+ (1,0) [0|0] "" SGW,RF_HUB
 SG_ VC_HRN_RMT_LK_CSO : 11|2@1+ (1,0) [0|0] "" SGW,RF_HUB,IC
 SG_ VC_HRN_RMT_ST_CSO : 13|1@1+ (1,0) [0|0] "" SGW,RF_HUB,IC
 SG_ VC_HRN_RMT_LWR_CSO : 14|1@1+ (1,0) [0|0] "" SGW,RF_HUB
 SG_ VC_CHMSL_LINE_CSO : 15|1@1+ (1,0) [0|0] "" SGW,RF_HUB
 SG_ VC_DCS_CSO : 16|2@1+ (1,0) [0|0] "" SGW,RF_HUB,IC
 SG_ VC_AUX_SWS_CSO : 18|2@1+ (1,0) [0|0] "" SGW,RF_HUB,IC
 SG_ VC_CMRA_GRDLNS_CSO : 20|2@1+ (1,0) [0|0] "" SGW,RF_HUB
 SG_ VC_ACC_DLY_CSO : 24|1@1+ (1,0) [0|0] "" SGW,RF_HUB,IC
 SG_ VC_AFLS_CSO : 25|1@1+ (1,0) [0|0] "" SGW,RF_HUB,IC
 SG_ VC_AMB_DMR_CSO : 26|1@1+ (1,0) [0|0] "" SGW,RF_HUB
 SG_ VC_ASCM_TJ_CSO : 27|1@1+ (1,0) [0|0] "" SGW,RF_HUB,IC
 SG_ VC_ASCM_WRN_CSO : 28|1@1+ (1,0) [0|0] "" SGW,RF_HUB,IC
 SG_ VC_AUTO_AERO_CSO : 29|1@1+ (1,0) [0|0] "" SGW,RF_HUB
 SG_ VC_AUTO_HB_CSO : 30|1@1+ (1,0) [0|0] "" SGW,RF_HUB,IC
 SG_ VC_AUTO_PRK_CSO : 31|1@1+ (1,0) [0|0] "" SGW,RF_HUB
 SG_ VC_BLIND_SPOT_CSO : 32|1@1+ (1,0) [0|0] "" SGW,RF_HUB,IC
 SG_ VC_CAPACITY_CSO : 33|1@1+ (1,0) [0|0] "" SGW,RF_HUB,IC
 SG_ VC_CLK_DSP_CSO : 34|1@1+ (1,0) [0|0] "" SGW,RF_HUB,IC
 SG_ VC_CMP_CAL_CSO : 35|1@1+ (1,0) [0|0] "" SGW,RF_HUB,IC
 SG_ VC_CMP_VAR_CSO : 36|1@1+ (1,0) [0|0] "" SGW,RF_HUB,IC
 SG_ VC_CONS_CSO : 37|1@1+ (1,0) [0|0] "" SGW,RF_HUB,IC
 SG_ VC_DISTANCE_CSO : 38|1@1+ (1,0) [0|0] "" SGW,RF_HUB,IC
 SG_ VC_DR_LK_CSO : 39|1@1+ (1,0) [0|0] "" SGW,RF_HUB,IC
 SG_ VC_DR_UNLK_CSO : 40|1@1+ (1,0) [0|0] "" SGW,RF_HUB,IC
 SG_ VC_DRL_CSO : 41|1@1+ (1,0) [0|0] "" SGW,RF_HUB,IC
 SG_ VC_EASY_EXIT_CSO : 42|1@1+ (1,0) [0|0] "" SGW,RF_HUB,IC
 SG_ VC_ENTRY_EXIT_CSO : 43|1@1+ (1,0) [0|0] "" SGW,RF_HUB
 SG_ VC_EPB_SERV_CSO : 44|1@1+ (1,0) [0|0] "" SGW,RF_HUB
 SG_ VC_FLSH_LMP_LK_CSO : 45|1@1+ (1,0) [0|0] "" SGW,RF_HUB,IC
 SG_ VC_HL_DRP_CSO : 46|1@1+ (1,0) [0|0] "" SGW,RF_HUB
 SG_ VC_HL_OFF_DLY_CSO : 47|1@1+ (1,0) [0|0] "" SGW,RF_HUB,IC
 SG_ VC_HL_WPR_CSO : 48|1@1+ (1,0) [0|0] "" SGW,RF_HUB,IC
 SG_ VC_HSA_CSO : 49|1@1+ (1,0) [0|0] "" SGW,RF_HUB,IC
 SG_ VC_ILL_APPRCH_CSO : 50|1@1+ (1,0) [0|0] "" SGW,RF_HUB,IC
 SG_ VC_LDW_TRQ_CSO : 51|1@1+ (1,0) [0|0] "" SGW,RF_HUB
 SG_ VC_LDW_WRN_CSO : 52|1@1+ (1,0) [0|0] "" SGW,RF_HUB
 SG_ VC_LGHT_RMT_LWR_CSO : 53|1@1+ (1,0) [0|0] "" SGW,RF_HUB
 SG_ VC_NAV_TRN_CSO : 54|1@1+ (1,0) [0|0] "" SGW,RF_HUB,IC
 SG_ VC_PE_CSO : 55|1@1+ (1,0) [0|0] "" SGW,RF_HUB,IC
 SG_ VC_PER_SHFT_ENBL_CSO : 56|1@1+ (1,0) [0|0] "" SGW,RF_HUB
 SG_ VC_PER_SHFT_RPM_CSO : 57|1@1+ (1,0) [0|0] "" SGW,RF_HUB
 SG_ VC_PLG_CHM_CSO : 58|1@1+ (1,0) [0|0] "" SGW,RF_HUB
 SG_ VC_POWER_CSO : 59|1@1+ (1,0) [0|0] "" SGW,RF_HUB,IC
 SG_ VC_PRESSURE_CSO : 60|1@1+ (1,0) [0|0] "" SGW,RF_HUB,IC
 SG_ VC_PTO_CSO : 61|1@1+ (1,0) [0|0] "" SGW,RF_HUB,IC
 SG_ VC_RAIN_WPR_CSO : 62|1@1+ (1,0) [0|0] "" SGW,RF_HUB,IC
 SG_ VC_REAR_CMRA_CSO : 63|1@1+ (1,0) [0|0] "" SGW,RF_HUB
 SG_ VC_POLICE_PE_CSO : 23|1@1+ (1,0) [0|0] "" SGW,RF_HUB
 SG_ VC_UNIT_SET_CSO : 22|1@1+ (1,0) [0|0] "" SGW,RF_HUB,IC

BO_ 948 VehCfgCSM2: 8 CBC
 SG_ VC_VehCfgCSO2_Stat : 0|2@1+ (1,0) [0|0] "" SGW,RF_HUB,IC
 SG_ VC_REAR_CMRA_DLY_CSO : 2|1@1+ (1,0) [0|0] "" SGW,RF_HUB,IC
 SG_ VC_RKE_MEM_CSO : 3|1@1+ (1,0) [0|0] "" SGW,RF_HUB,IC
 SG_ VC_RKE_UNLK_CSO : 4|1@1+ (1,0) [0|0] "" SGW,RF_HUB,IC
 SG_ VC_SPEED_CSO : 5|1@1+ (1,0) [0|0] "" SGW,RF_HUB,IC
 SG_ VC_TLT_MRR_CSO : 6|1@1+ (1,0) [0|0] "" SGW,RF_HUB,IC
 SG_ VC_TORQUE_CSO : 7|1@1+ (1,0) [0|0] "" SGW,RF_HUB,IC
 SG_ VC_TRLR_CSO : 8|1@1+ (1,0) [0|0] "" SGW,RF_HUB,IC
 SG_ VC_TRLR_NAME_CSO : 9|1@1+ (1,0) [0|0] "" SGW,RF_HUB,IC
 SG_ VC_TRLR_TYPE_CSO : 10|1@1+ (1,0) [0|0] "" SGW,RF_HUB,IC
 SG_ VC_TRNS_MD_CSO : 11|1@1+ (1,0) [0|0] "" SGW,RF_HUB,IC
 SG_ VC_US_METRIC_CSO : 12|1@1+ (1,0) [0|0] "" SGW,RF_HUB
 SG_ VC_WHL_ALGN_CSO : 13|1@1+ (1,0) [0|0] "" SGW,RF_HUB,IC
 SG_ VC_FUEL_SAV_CSO : 14|1@1+ (1,0) [0|0] "" SGW,RF_HUB
 SG_ VC_TEMP_CSO : 15|1@1+ (1,0) [0|0] "" SGW,RF_HUB,IC
 SG_ VC_FCW_SW_CSO : 47|1@1+ (1,0) [0|0] "" SGW,RF_HUB
 SG_ VC_PADDLE_SHIFT_CSO : 39|1@1+ (1,0) [0|0] "" SGW,RF_HUB
 SG_ VC_PWR_FLD_MRR_CSO : 17|1@1+ (1,0) [0|0] "" SGW,RF_HUB
 SG_ VC_TEEN_FCW_BRK_CSO : 24|1@1+ (1,0) [0|0] "" SGW,RF_HUB
 SG_ VC_TEEN_FCW_SENS_CSO : 23|1@1+ (1,0) [0|0] "" SGW,RF_HUB
 SG_ VC_TEEN_MAX_SPEED_CSO : 28|1@1+ (1,0) [0|0] "" SGW,RF_HUB
 SG_ VC_HOLD_N_GO_CSO : 16|1@1+ (1,0) [0|0] "" SGW,RF_HUB
 SG_ VC_HANDS_FREE_LFT_CSO : 18|1@1+ (1,0) [0|0] "" SGW,RF_HUB
 SG_ VC_HANDS_FREE_SLDR_CSO : 19|1@1+ (1,0) [0|0] "" SGW,RF_HUB
 SG_ VC_SVC_GRIDLINES_CSO : 20|1@1+ (1,0) [0|0] "" SGW,RF_HUB,IC
 SG_ VC_SVC_DELAY_CSO : 21|1@1+ (1,0) [0|0] "" SGW,RF_HUB,IC
 SG_ VC_SLD_DR_ALRT_CSO : 22|1@1+ (1,0) [0|0] "" SGW,RF_HUB
 SG_ VC_TEEN_PRK_ASST_CSO : 25|1@1+ (1,0) [0|0] "" SGW,RF_HUB
 SG_ VC_TEEN_FT_PRK_VOL_CSO : 26|1@1+ (1,0) [0|0] "" SGW,RF_HUB
 SG_ VC_TEEN_RR_PRK_VOL_CSO : 27|1@1+ (1,0) [0|0] "" SGW,RF_HUB
 SG_ VC_TEEN_FUEL_WRN_CSO : 29|1@1+ (1,0) [0|0] "" SGW,RF_HUB
 SG_ VC_TEEN_FUEL_POPUP_CSO : 30|1@1+ (1,0) [0|0] "" SGW,RF_HUB
 SG_ VC_TEEN_BLIND_SPOT_CSO : 31|1@1+ (1,0) [0|0] "" SGW,RF_HUB
 SG_ VC_TEEN_RAIN_WPR_CSO : 32|1@1+ (1,0) [0|0] "" SGW,RF_HUB
 SG_ VC_TEEN_AUTO_HB_CSO : 33|1@1+ (1,0) [0|0] "" SGW,RF_HUB
 SG_ VC_TEEN_LGHT_WPR_CSO : 34|1@1+ (1,0) [0|0] "" SGW,RF_HUB
 SG_ VC_TEEN_SLD_DR_ALRT_CSO : 35|1@1+ (1,0) [0|0] "" SGW,RF_HUB
 SG_ VC_TEEN_PLG_CHIME_CSO : 36|1@1+ (1,0) [0|0] "" SGW,RF_HUB
 SG_ VC_SLD_DR_CHM_CSO : 37|1@1+ (1,0) [0|0] "" SGW,RF_HUB
 SG_ VC_TEEN_SLD_DR_CHM_CSO : 38|1@1+ (1,0) [0|0] "" SGW,RF_HUB
 SG_ VC_FLSH_LMP_SLDR_CSO : 40|1@1+ (1,0) [0|0] "" SGW,RF_HUB
 SG_ VC_SPEED_WARNING_CSO : 41|2@1+ (1,0) [0|0] "" SGW,RF_HUB
 SG_ VC_LDW_ON_CSO : 43|1@1+ (1,0) [0|0] "" SGW,RF_HUB
 SG_ VC_PRK_ASST_TYPE_CSO : 44|1@1+ (1,0) [0|0] "" SGW,RF_HUB
 SG_ VC_EPB_ON_CSO : 45|1@1+ (1,0) [0|0] "" SGW,RF_HUB
 SG_ VC_AIRBAG_ON_CSO : 46|1@1+ (1,0) [0|0] "" SGW,RF_HUB
 SG_ VC_RDY_DRV_CSO : 55|1@1+ (1,0) [0|0] "" SGW,RF_HUB
 SG_ VC_TEEN_PRK_ASST_BRK_CSO : 51|1@1+ (1,0) [0|0] "" SGW,RF_HUB
 SG_ VC_PCS_CSO : 52|1@1+ (1,0) [0|0] "" SGW,RF_HUB
 SG_ VC_FCW_WARN_BRK_CSO : 49|1@1+ (1,0) [0|0] "" SGW,RF_HUB
 SG_ VC_DOORS_OFF_ACC_DLY_CSO : 50|1@1+ (1,0) [0|0] "" SGW,RF_HUB
 SG_ VC_BSM_TRLR_CSO : 53|1@1+ (1,0) [0|0] "" SGW,RF_HUB
 SG_ VC_AUTO_SS_CSO : 54|1@1+ (1,0) [0|0] "" SGW,RF_HUB
 SG_ VC_MOTORIZED_SEATBELT_STRN_CSO : 57|1@1+ (1,0) [0|0] "" SGW,RF_HUB
 SG_ VC_MOTORIZED_SEATBELT_CSO : 56|1@1+ (1,0) [0|0] "" SGW,RF_HUB
 SG_ VC_LKA_CSO : 48|1@1+ (1,0) [0|0] "" SGW,RF_HUB
 SG_ VC_BLIND_SPOT_WARNING_CSO : 58|1@1+ (1,0) [0|0] "" SGW,RF_HUB
 SG_ VC_ABSD_WARNING_CSO : 60|1@1+ (1,0) [0|0] "" SGW,RF_HUB
 SG_ VC_ABSD_STRN_CSO : 62|1@1+ (1,0) [0|0] "" SGW,RF_HUB
 SG_ VC_ABSD_SENS_CSO : 61|1@1+ (1,0) [0|0] "" SGW,RF_HUB
 SG_ VC_ABSD_HAPTIC_CSO : 63|1@1+ (1,0) [0|0] "" SGW,RF_HUB
 SG_ VC_ABSD_CSO : 59|1@1+ (1,0) [0|0] "" SGW,RF_HUB

BO_ 949 VehCfgCSM1_BU: 8 RF_HUB
 SG_ VC_BU_VehCfgCSO1_Stat : 0|2@1+ (1,0) [0|0] "" SGW,CBC
 SG_ VC_BU_PRK_AST_CSO : 2|2@1+ (1,0) [0|0] "" SGW,CBC
 SG_ VC_BU_PRK_AST_BRK_CSO : 4|1@1+ (1,0) [0|0] "" SGW,CBC
 SG_ VC_BU_PRK_FT_VOL_CSO : 5|1@1+ (1,0) [0|0] "" SGW,CBC
 SG_ VC_BU_PRK_RR_VOL_CSO : 6|1@1+ (1,0) [0|0] "" SGW,CBC
 SG_ VC_BU_EPS_CSO : 7|1@1+ (1,0) [0|0] "" SGW,CBC
 SG_ VC_BU_FCW_CSO : 8|2@1+ (1,0) [0|0] "" SGW,CBC
 SG_ VC_BU_FCW_BRK_CSO : 10|1@1+ (1,0) [0|0] "" SGW,CBC
 SG_ VC_BU_HRN_RMT_LK_CSO : 11|2@1+ (1,0) [0|0] "" SGW,CBC
 SG_ VC_BU_HRN_RMT_ST_CSO : 13|1@1+ (1,0) [0|0] "" SGW,CBC
 SG_ VC_BU_HRN_RMT_LWR_CSO : 14|1@1+ (1,0) [0|0] "" SGW,CBC
 SG_ VC_BU_CHMSL_LINE_CSO : 15|1@1+ (1,0) [0|0] "" SGW,CBC
 SG_ VC_BU_DCS_CSO : 16|2@1+ (1,0) [0|0] "" SGW,CBC
 SG_ VC_BU_AUX_SWS_CSO : 18|2@1+ (1,0) [0|0] "" SGW,CBC
 SG_ VC_BU_CMRA_GRDLNS_CSO : 20|2@1+ (1,0) [0|0] "" SGW,CBC
 SG_ VC_BU_ACC_DLY_CSO : 24|1@1+ (1,0) [0|0] "" SGW,CBC
 SG_ VC_BU_AFLS_CSO : 25|1@1+ (1,0) [0|0] "" SGW,CBC
 SG_ VC_BU_AMB_DMR_CSO : 26|1@1+ (1,0) [0|0] "" SGW,CBC
 SG_ VC_BU_ASCM_TJ_CSO : 27|1@1+ (1,0) [0|0] "" SGW,CBC
 SG_ VC_BU_ASCM_WRN_CSO : 28|1@1+ (1,0) [0|0] "" SGW,CBC
 SG_ VC_BU_AUTO_AERO_CSO : 29|1@1+ (1,0) [0|0] "" SGW,CBC
 SG_ VC_BU_AUTO_HB_CSO : 30|1@1+ (1,0) [0|0] "" SGW,CBC
 SG_ VC_BU_AUTO_PRK_CSO : 31|1@1+ (1,0) [0|0] "" SGW,CBC
 SG_ VC_BU_BLIND_SPOT_CSO : 32|1@1+ (1,0) [0|0] "" SGW,CBC
 SG_ VC_BU_CAPACITY_CSO : 33|1@1+ (1,0) [0|0] "" SGW,CBC
 SG_ VC_BU_CLK_DSP_CSO : 34|1@1+ (1,0) [0|0] "" SGW,CBC
 SG_ VC_BU_CMP_CAL_CSO : 35|1@1+ (1,0) [0|0] "" SGW,CBC
 SG_ VC_BU_CMP_VAR_CSO : 36|1@1+ (1,0) [0|0] "" SGW,CBC
 SG_ VC_BU_CONS_CSO : 37|1@1+ (1,0) [0|0] "" SGW,CBC
 SG_ VC_BU_DISTANCE_CSO : 38|1@1+ (1,0) [0|0] "" SGW,CBC
 SG_ VC_BU_DR_LK_CSO : 39|1@1+ (1,0) [0|0] "" SGW,CBC
 SG_ VC_BU_DR_UNLK_CSO : 40|1@1+ (1,0) [0|0] "" SGW,CBC
 SG_ VC_BU_DRL_CSO : 41|1@1+ (1,0) [0|0] "" SGW,CBC
 SG_ VC_BU_EASY_EXIT_CSO : 42|1@1+ (1,0) [0|0] "" SGW,CBC
 SG_ VC_BU_ENTRY_EXIT_CSO : 43|1@1+ (1,0) [0|0] "" SGW,CBC
 SG_ VC_BU_EPB_SERV_CSO : 44|1@1+ (1,0) [0|0] "" SGW,CBC
 SG_ VC_BU_FLSH_LMP_LK_CSO : 45|1@1+ (1,0) [0|0] "" SGW,CBC
 SG_ VC_BU_HL_DRP_CSO : 46|1@1+ (1,0) [0|0] "" SGW,CBC
 SG_ VC_BU_HL_OFF_DLY_CSO : 47|1@1+ (1,0) [0|0] "" SGW,CBC
 SG_ VC_BU_HL_WPR_CSO : 48|1@1+ (1,0) [0|0] "" SGW,CBC
 SG_ VC_BU_HSA_CSO : 49|1@1+ (1,0) [0|0] "" SGW,CBC
 SG_ VC_BU_ILL_APPRCH_CSO : 50|1@1+ (1,0) [0|0] "" SGW,CBC
 SG_ VC_BU_LDW_TRQ_CSO : 51|1@1+ (1,0) [0|0] "" SGW,CBC
 SG_ VC_BU_LDW_WRN_CSO : 52|1@1+ (1,0) [0|0] "" SGW,CBC
 SG_ VC_BU_LGHT_RMT_LWR_CSO : 53|1@1+ (1,0) [0|0] "" SGW,CBC
 SG_ VC_BU_NAV_TRN_CSO : 54|1@1+ (1,0) [0|0] "" SGW,CBC
 SG_ VC_BU_PE_CSO : 55|1@1+ (1,0) [0|0] "" SGW,CBC
 SG_ VC_BU_PER_SHFT_ENBL_CSO : 56|1@1+ (1,0) [0|0] "" SGW,CBC
 SG_ VC_BU_PER_SHFT_RPM_CSO : 57|1@1+ (1,0) [0|0] "" SGW,CBC
 SG_ VC_BU_PLG_CHM_CSO : 58|1@1+ (1,0) [0|0] "" SGW,CBC
 SG_ VC_BU_POWER_CSO : 59|1@1+ (1,0) [0|0] "" SGW,CBC
 SG_ VC_BU_PRESSURE_CSO : 60|1@1+ (1,0) [0|0] "" SGW,CBC
 SG_ VC_BU_PTO_CSO : 61|1@1+ (1,0) [0|0] "" SGW,CBC
 SG_ VC_BU_RAIN_WPR_CSO : 62|1@1+ (1,0) [0|0] "" SGW,CBC
 SG_ VC_BU_REAR_CMRA_CSO : 63|1@1+ (1,0) [0|0] "" SGW,CBC
 SG_ VC_BU_POLICE_PE_CSO : 23|1@1+ (1,0) [0|0] "" SGW,CBC
 SG_ VC_BU_UNIT_SET_CSO : 22|1@1+ (1,0) [0|0] "" SGW,CBC

BO_ 950 VehCfgCSM2_BU: 8 RF_HUB
 SG_ VC_BU_VehCfgCSO2_Stat : 0|2@1+ (1,0) [0|0] "" SGW,CBC
 SG_ VC_BU_REAR_CMRA_DLY_CSO : 2|1@1+ (1,0) [0|0] "" SGW,CBC
 SG_ VC_BU_RKE_MEM_CSO : 3|1@1+ (1,0) [0|0] "" SGW,CBC
 SG_ VC_BU_RKE_UNLK_CSO : 4|1@1+ (1,0) [0|0] "" SGW,CBC
 SG_ VC_BU_SPEED_CSO : 5|1@1+ (1,0) [0|0] "" SGW,CBC
 SG_ VC_BU_TLT_MRR_CSO : 6|1@1+ (1,0) [0|0] "" SGW,CBC
 SG_ VC_BU_TORQUE_CSO : 7|1@1+ (1,0) [0|0] "" SGW,CBC
 SG_ VC_BU_TRLR_CSO : 8|1@1+ (1,0) [0|0] "" SGW,CBC
 SG_ VC_BU_TRLR_NAME_CSO : 9|1@1+ (1,0) [0|0] "" SGW,CBC
 SG_ VC_BU_TRLR_TYPE_CSO : 10|1@1+ (1,0) [0|0] "" SGW,CBC
 SG_ VC_BU_TRNS_MD_CSO : 11|1@1+ (1,0) [0|0] "" SGW,CBC
 SG_ VC_BU_US_METRIC_CSO : 12|1@1+ (1,0) [0|0] "" SGW,CBC
 SG_ VC_BU_WHL_ALGN_CSO : 13|1@1+ (1,0) [0|0] "" SGW,CBC
 SG_ VC_BU_FUEL_SAV_CSO : 14|1@1+ (1,0) [0|0] "" SGW,CBC
 SG_ VC_BU_TEMP_CSO : 15|1@1+ (1,0) [0|0] "" SGW,CBC
 SG_ VC_BU_FCW_SW_CSO : 47|1@1+ (1,0) [0|0] "" SGW,CBC
 SG_ VC_BU_PADDLE_SHIFT_CSO : 39|1@1+ (1,0) [0|0] "" SGW,CBC
 SG_ VC_BU_PWR_FLD_MRR_CSO : 17|1@1+ (1,0) [0|0] "" SGW,CBC
 SG_ VC_BU_TEEN_FCW_BRK_CSO : 24|1@1+ (1,0) [0|0] "" SGW,CBC
 SG_ VC_BU_TEEN_FCW_SENS_CSO : 23|1@1+ (1,0) [0|0] "" SGW,CBC
 SG_ VC_BU_TEEN_MAX_SPEED_CSO : 28|1@1+ (1,0) [0|0] "" SGW,CBC
 SG_ VC_BU_HOLD_N_GO_CSO : 16|1@1+ (1,0) [0|0] "" SGW,CBC
 SG_ VC_BU_HANDS_FREE_LFT_CSO : 18|1@1+ (1,0) [0|0] "" SGW,CBC
 SG_ VC_BU_HANDS_FREE_SLDR_CSO : 19|1@1+ (1,0) [0|0] "" SGW,CBC
 SG_ VC_BU_SVC_GRIDLINES_CSO : 20|1@1+ (1,0) [0|0] "" SGW,CBC
 SG_ VC_BU_SVC_DELAY_CSO : 21|1@1+ (1,0) [0|0] "" SGW,CBC
 SG_ VC_BU_SLD_DR_ALRT_CSO : 22|1@1+ (1,0) [0|0] "" SGW,CBC
 SG_ VC_BU_TEEN_PRK_ASST_CSO : 25|1@1+ (1,0) [0|0] "" SGW,CBC
 SG_ VC_BU_TEEN_FT_PRK_VOL_CSO : 26|1@1+ (1,0) [0|0] "" SGW,CBC
 SG_ VC_BU_TEEN_RR_PRK_VOL_CSO : 27|1@1+ (1,0) [0|0] "" SGW,CBC
 SG_ VC_BU_TEEN_FUEL_WRN_CSO : 29|1@1+ (1,0) [0|0] "" SGW,CBC
 SG_ VC_BU_TEEN_FUEL_POPUP_CSO : 30|1@1+ (1,0) [0|0] "" SGW,CBC
 SG_ VC_BU_TEEN_BLIND_SPOT_CSO : 31|1@1+ (1,0) [0|0] "" SGW,CBC
 SG_ VC_BU_TEEN_RAIN_WPR_CSO : 32|1@1+ (1,0) [0|0] "" SGW,CBC
 SG_ VC_BU_TEEN_AUTO_HB_CSO : 33|1@1+ (1,0) [0|0] "" SGW,CBC
 SG_ VC_BU_TEEN_LGHT_WPR_CSO : 34|1@1+ (1,0) [0|0] "" SGW,CBC
 SG_ VC_BU_TEEN_SLD_DR_ALRT_CSO : 35|1@1+ (1,0) [0|0] "" SGW,CBC
 SG_ VC_BU_TEEN_PLG_CHIME_CSO : 36|1@1+ (1,0) [0|0] "" SGW,CBC
 SG_ VC_BU_SLD_DR_CHM_CSO : 37|1@1+ (1,0) [0|0] "" SGW,CBC
 SG_ VC_BU_TEEN_SLD_DR_CHM_CSO : 38|1@1+ (1,0) [0|0] "" SGW,CBC
 SG_ VC_BU_FLSH_LMP_SLDR_CSO : 40|1@1+ (1,0) [0|0] "" SGW,CBC
 SG_ VC_BU_SPEED_WARNING_CSO : 41|2@1+ (1,0) [0|0] "" SGW,CBC
 SG_ VC_BU_LDW_ON_CSO : 43|1@1+ (1,0) [0|0] "" SGW,CBC
 SG_ VC_BU_PRK_ASST_TYPE_CSO : 44|1@1+ (1,0) [0|0] "" SGW,CBC
 SG_ VC_BU_EPB_ON_CSO : 45|1@1+ (1,0) [0|0] "" SGW,CBC
 SG_ VC_BU_AIRBAG_ON_CSO : 46|1@1+ (1,0) [0|0] "" SGW,CBC
 SG_ VC_BU_RDY_DRV_CSO : 55|1@1+ (1,0) [0|0] "" SGW,CBC
 SG_ VC_BU_TEEN_PRK_ASST_BRK_CSO : 51|1@1+ (1,0) [0|0] "" SGW,CBC
 SG_ VC_BU_PCS_CSO : 52|1@1+ (1,0) [0|0] "" SGW,CBC
 SG_ VC_BU_FCW_WARN_BRK_CSO : 49|1@1+ (1,0) [0|0] "" SGW,CBC
 SG_ VC_BU_DOORS_OFF_ACC_DLY_CSO : 50|1@1+ (1,0) [0|0] "" SGW,CBC
 SG_ VC_BU_BSM_TRLR_CSO : 53|1@1+ (1,0) [0|0] "" SGW,CBC
 SG_ VC_BU_AUTO_SS_CSO : 54|1@1+ (1,0) [0|0] "" SGW,CBC
 SG_ VC_BU_MOTORIZED_SEATBELT_CSO : 56|1@1+ (1,0) [0|0] "" SGW,CBC
 SG_ VC_BU_LKA_CSO : 48|1@1+ (1,0) [0|0] "" SGW,CBC
 SG_ VC_BU_BLIND_SPOT_WARNING_CSO : 58|1@1+ (1,0) [0|0] "" SGW,CBC
 SG_ VC_BU_ABSD_WARNING_CSO : 60|1@1+ (1,0) [0|0] "" SGW,CBC
 SG_ VC_BU_ABSD_STRN_CSO : 62|1@1+ (1,0) [0|0] "" SGW,CBC
 SG_ VC_BU_ABSD_SENS_CSO : 61|1@1+ (1,0) [0|0] "" SGW,CBC
 SG_ VC_BU_ABSD_HAPTIC_CSO : 63|1@1+ (1,0) [0|0] "" SGW,CBC
 SG_ VC_BU_ABSD_CSO : 59|1@1+ (1,0) [0|0] "" SGW,CBC
 SG_ VC_BU_MOTORIZED_SEATBELT_STRN_CS : 57|1@1+ (1,0) [0|0] "" SGW,CBC

BO_ 956 NAV_DATA: 8 CBC
 SG_ NAV_GrpNum : 4|4@1+ (1,1) [1|16] "Group" SGW,IC
 SG_ NAV_GrpTyp : 8|6@1+ (1,0) [1|40] "Text" SGW,IC
 SG_ NAV_HiGrpMark : 14|1@1+ (1,0) [0|0] "" SGW,IC
 SG_ NAV_TEXT : 23|48@0+ (1,0) [0|0] "" SGW,IC

BO_ 969 AMB_TEMP_DISP: 4 CBC
 SG_ AMB_TEMP_AVG_F : 0|8@1+ (1,-40) [-40|210] "°F" FTM,SGW,IC
 SG_ AMB_TEMP_AVG_C : 8|8@1+ (1,-40) [-40|210] "°C" FTM,SGW,IC

BO_ 974 GW_Dev: 5 CBC
 SG_ FT_HVAC_BLW_FN_SP : 0|7@1+ (1,0) [0|100] "Bars" SGW,PCM,ECM
 SG_ DRV_TEMP_DR_POS : 16|7@1+ (1,0) [0|100] "%" SGW,PCM,ECM

BO_ 977 TCM_CFG: 4 TCM
 SG_ TransTyp : 0|8@1+ (1,0) [0|0] "" SGW,DTCM

BO_ 979 EcuCfg14: 8 CBC
 SG_ EC_ECUCfg14_Stat : 0|2@1+ (1,0) [0|0] "" SGW,RF_HUB
 SG_ EC_CBC14A : 2|6@1+ (1,0) [0|0] "" SGW,RF_HUB
 SG_ EC_CBC14B : 15|56@0+ (1,0) [0|0] "" SGW,RF_HUB

BO_ 980 EcuCfg13: 8 CBC
 SG_ EC_ECUCfg13_Stat : 0|2@1+ (1,0) [0|0] "" SGW,RF_HUB
 SG_ EC_CBC13A : 2|6@1+ (1,0) [0|0] "" SGW,RF_HUB
 SG_ EC_CBC13B : 15|56@0+ (1,0) [0|0] "" SGW,RF_HUB

BO_ 981 EcuCfg12: 8 CBC
 SG_ EC_ECUCfg12_Stat : 0|2@1+ (1,0) [0|0] "" SGW,RF_HUB,IC
 SG_ EC_Cluster5A : 2|6@1+ (1,0) [0|0] "" SGW,RF_HUB
 SG_ EC_Cluster5B : 15|24@0+ (1,0) [0|0] "" SGW,RF_HUB
 SG_ EC_Cluster5C : 39|32@0+ (1,0) [0|0] "" SGW,RF_HUB

BO_ 982 EcuCfg11: 8 CBC
 SG_ EC_ECUCfg11_Stat : 0|2@1+ (1,0) [0|0] "" SGW,RF_HUB
 SG_ EC_CBC10A : 2|6@1+ (1,0) [0|0] "" SGW,RF_HUB
 SG_ EC_CBC10B : 15|24@0+ (1,0) [0|0] "" SGW,RF_HUB
 SG_ EC_CBC11 : 39|32@0+ (1,0) [0|0] "" SGW,RF_HUB

BO_ 983 EcuCfg10: 8 CBC
 SG_ EC_ECUCfg10_Stat : 0|2@1+ (1,0) [0|0] "" SGW,RF_HUB,IC
 SG_ EC_Cluster3A : 2|6@1+ (1,0) [0|0] "" SGW,RF_HUB
 SG_ EC_Cluster3B : 15|24@0+ (1,0) [0|0] "" SGW,RF_HUB
 SG_ EC_Cluster4 : 39|32@0+ (1,0) [0|0] "" SGW,RF_HUB

BO_ 984 EcuCfg9: 8 CBC
 SG_ EC_ECUCfg9_Stat : 0|2@1+ (1,0) [0|0] "" SGW,RF_HUB
 SG_ EC_CBC9A1 : 2|6@1+ (1,0) [0|0] "" SGW,RF_HUB
 SG_ EC_CBC9A2 : 15|24@0+ (1,0) [0|0] "" SGW,RF_HUB
 SG_ EC_CBC9B : 39|16@0+ (1,0) [0|0] "" SGW,RF_HUB
 SG_ EC_ITM : 55|16@0+ (1,0) [0|0] "" SGW,RF_HUB

BO_ 985 EcuBuCfg14: 8 RF_HUB
 SG_ EC_BU_ECUCfg14_Stat : 0|2@1+ (1,0) [0|0] "" SGW,CBC
 SG_ EC_BU_CBC14A : 2|6@1+ (1,0) [0|0] "" SGW,CBC
 SG_ EC_BU_CBC14B : 15|56@0+ (1,0) [0|0] "" SGW,CBC

BO_ 986 EcuBuCfg13: 8 RF_HUB
 SG_ EC_BU_ECUCfg13_Stat : 0|2@1+ (1,0) [0|0] "" SGW,CBC
 SG_ EC_BU_CBC13A : 2|6@1+ (1,0) [0|0] "" SGW,CBC
 SG_ EC_BU_CBC13B : 15|56@0+ (1,0) [0|0] "" SGW,CBC

BO_ 987 EcuBuCfg12: 8 RF_HUB
 SG_ EC_BU_ECUCfg12_Stat : 0|2@1+ (1,0) [0|0] "" SGW,CBC
 SG_ EC_BU_Cluster5A : 2|6@1+ (1,0) [0|0] "" SGW,CBC
 SG_ EC_BU_Cluster5B : 15|24@0+ (1,0) [0|0] "" SGW,CBC
 SG_ EC_BU_Cluster5C : 39|32@0+ (1,0) [0|0] "" SGW,CBC

BO_ 988 EcuBuCfg11: 8 RF_HUB
 SG_ EC_BU_ECUCfg11_Stat : 0|2@1+ (1,0) [0|0] "" SGW,CBC
 SG_ EC_BU_CBC10A : 2|6@1+ (1,0) [0|0] "" SGW,CBC
 SG_ EC_BU_CBC10B : 15|24@0+ (1,0) [0|0] "" SGW,CBC
 SG_ EC_BU_CBC11 : 39|32@0+ (1,0) [0|0] "" SGW,CBC

BO_ 989 EcuBuCfg10: 8 RF_HUB
 SG_ EC_BU_ECUCfg10_Stat : 0|2@1+ (1,0) [0|0] "" SGW,CBC
 SG_ EC_BU_Cluster3A : 2|6@1+ (1,0) [0|0] "" SGW,CBC
 SG_ EC_BU_Cluster3B : 15|24@0+ (1,0) [0|0] "" SGW,CBC
 SG_ EC_BU_Cluster4 : 39|32@0+ (1,0) [0|0] "" SGW,CBC

BO_ 991 EcuBuCfg9: 8 RF_HUB
 SG_ EC_BU_ECUCfg9_Stat : 0|2@1+ (1,0) [0|0] "" SGW,CBC
 SG_ EC_BU_CBC9A1 : 2|6@1+ (1,0) [0|0] "" SGW,CBC
 SG_ EC_BU_CBC9A2 : 15|24@0+ (1,0) [0|0] "" SGW,CBC
 SG_ EC_BU_CBC9B : 39|16@0+ (1,0) [0|0] "" SGW,CBC
 SG_ EC_BU_ITM : 55|16@0+ (1,0) [0|0] "" SGW,CBC

BO_ 993 ENG_CFG: 7 ECM
 SG_ DISPLACEMENT : 0|8@1+ (0.1,0) [0|25] "liters" IRCM,SGW,ETM,ESC,CBC,ASCM
 SG_ NUM_CYL : 8|4@1+ (1,0) [0|14] "cylinders" IRCM,SGW,IC,ETM,ESC
 SG_ SpStPrsnt : 12|1@1+ (1,0) [0|0] "" IRCM,SGW
 SG_ ENG_ASP : 13|3@1+ (1,0) [0|0] "" IRCM,SGW,ETM,ESC
 SG_ FUEL_TYPE : 16|3@1+ (1,0) [0|0] "" FTM,IRCM,SGW,ITBM,TCM,IC,ETM,ESC,CBC,ASCM
 SG_ ECM_Vehi_Type : 19|2@1+ (1,0) [0|0] "" SGW
 SG_ Manufacture : 21|3@1+ (1,0) [0|0] "" SGW
 SG_ NUM_VALVE : 24|3@1+ (1,0) [0|6] "valve-per-cylinder" IRCM,SGW
 SG_ ETC_PRSNT : 27|1@1+ (1,0) [0|0] "" SGW
 SG_ TRANS_TYPE : 28|1@1+ (1,0) [0|0] "" SGW,VSIM,IC,ETM,DTCM,CBC,ASCM
 SG_ EngStyle : 29|3@1+ (1,0) [0|0] "" SGW,TCM,ESC,CBC

BO_ 995 NET_CFG_INT: 8 CBC
 SG_ NET_CFG_STAT_INT : 0|2@1+ (1,0) [0|0] "" IRCM,SGW,VSIM,RF_HUB,PTS,IC,ASCM
 SG_ NetCfg_RBSS : 2|1@1+ (1,0) [0|0] "" SGW,RF_HUB
 SG_ NetCfg_BSM : 3|1@1+ (1,0) [0|0] "" IRCM,SGW,RF_HUB,IC
 SG_ NetCfg_CBC_IN : 4|1@1+ (1,0) [0|0] "" SGW,RF_HUB
 SG_ NetCfg_CSWM : 5|1@1+ (1,0) [0|0] "" SGW,RF_HUB
 SG_ NetCfg_DCM_DR : 6|1@1+ (1,0) [0|0] "" SGW,RF_HUB
 SG_ NetCfg_DCM_PASS : 7|1@1+ (1,0) [0|0] "" SGW,RF_HUB
 SG_ NetCfg_DCM_RL : 8|1@1+ (1,0) [0|0] "" SGW,RF_HUB
 SG_ NetCfg_DCM_RR : 9|1@1+ (1,0) [0|0] "" SGW,RF_HUB
 SG_ NetCfg_HVAC : 10|1@1+ (1,0) [0|0] "" SGW,RF_HUB
 SG_ NetCfg_MSM : 11|1@1+ (1,0) [0|0] "" SGW,RF_HUB
 SG_ NetCfg_PLG : 12|1@1+ (1,0) [0|0] "" SGW,RF_HUB
 SG_ NetCfg_VTM : 13|1@1+ (1,0) [0|0] "" SGW,RF_HUB
 SG_ NetCfg_PSD_LT : 14|1@1+ (1,0) [0|0] "" SGW,RF_HUB
 SG_ NetCfg_PSD_RT : 15|1@1+ (1,0) [0|0] "" SGW,RF_HUB
 SG_ NetCfg_FSM : 16|1@1+ (1,0) [0|0] "" SGW,RF_HUB
 SG_ NetCfg_PTCM : 17|1@1+ (1,0) [0|0] "" SGW,RF_HUB
 SG_ NetCfg_RBC : 18|1@1+ (1,0) [0|0] "" SGW,RF_HUB
 SG_ NetCfg_DTV : 19|1@1+ (1,0) [0|0] "" SGW,RF_HUB
 SG_ NetCfg_TGW : 20|1@1+ (1,0) [0|0] "" SGW,RF_HUB
 SG_ NetCfg_CLOCK : 21|1@1+ (1,0) [0|0] "" SGW,RF_HUB
 SG_ NetCfg_VSIM : 22|1@1+ (1,0) [0|0] "" SGW,RF_HUB
 SG_ NetCfg_ITM : 23|1@1+ (1,0) [0|0] "" SGW,RF_HUB
 SG_ NetCfg_AMP_I : 24|1@1+ (1,0) [0|0] "" SGW,RF_HUB
 SG_ NetCfg_DVD_CDM : 25|1@1+ (1,0) [0|0] "" SGW,RF_HUB
 SG_ NetCfg_HFM_CTM : 26|1@1+ (1,0) [0|0] "" SGW,RF_HUB
 SG_ NetCfg_ICS_I : 27|1@1+ (1,0) [0|0] "" SGW,RF_HUB
 SG_ NetCfg_VES2_I : 28|1@1+ (1,0) [0|0] "" SGW,RF_HUB
 SG_ NetCfg_VES3_I : 29|1@1+ (1,0) [0|0] "" SGW,RF_HUB
 SG_ NetCfg_CRSM : 30|1@1+ (1,0) [0|0] "" SGW,RF_HUB
 SG_ NetCfg_HVAC_R : 31|1@1+ (1,0) [0|0] "" SGW,RF_HUB
 SG_ NetCfg_DCSD : 37|1@1+ (1,0) [0|0] "" SGW,RF_HUB
 SG_ NetCfg_TBM : 38|1@1+ (1,0) [0|0] "" SGW,RF_HUB
 SG_ NetCfg_CVPM : 32|1@1+ (1,0) [0|0] "" SGW,RF_HUB
 SG_ NetCfg_TMM : 33|1@1+ (1,0) [0|0] "" SGW,RF_HUB
 SG_ NetCfg_ICS_R : 34|1@1+ (1,0) [0|0] "" SGW,RF_HUB
 SG_ NetCfg_MSM_PASS : 35|1@1+ (1,0) [0|0] "" SGW,RF_HUB
 SG_ NetCfg_VRM : 36|1@1+ (1,0) [0|0] "" SGW,RF_HUB
 SG_ NetCfg_ANC_I : 39|1@1+ (1,0) [0|0] "" SGW,RF_HUB
 SG_ NetCfg_TTM : 47|1@1+ (1,0) [0|0] "" SGW,RF_HUB
 SG_ NetCfg_UPFM : 46|1@1+ (1,0) [0|0] "" SGW,RF_HUB
 SG_ NetCfg_PSSM : 45|1@1+ (1,0) [0|0] "" SGW,RF_HUB,IC

BO_ 996 NET_CFG_PT: 8 CBC
 SG_ NET_CFG_STAT_PT : 0|2@1+ (1,0) [0|0] "" ATMM,IRCM,SGW,ITBM,FDCM,PCM,VSIM,TCM,SCCM,RF_HUB,PTS,ORC,IC,ESM,ESC,ECM,DTCM,ASCM,AFLS
 SG_ NetCfg_ACC : 2|1@1+ (1,0) [0|0] "" SGW,TCM,RF_HUB
 SG_ NetCfg_ADCM : 3|1@1+ (1,0) [0|0] "" SGW,RF_HUB
 SG_ NetCfg_AHLM : 4|1@1+ (1,0) [0|0] "" SGW,RF_HUB
 SG_ NetCfg_VSIM_C : 5|1@1+ (1,0) [0|0] "" SGW,PCM,RF_HUB,ECM
 SG_ NetCfg_ASCM : 6|1@1+ (1,0) [0|0] "" IRCM,SGW,RF_HUB,IC,ESC
 SG_ NetCfg_CBC_PT : 7|1@1+ (1,0) [0|0] "" IRCM,SGW,PCM,TCM,RF_HUB,ORC,ECM
 SG_ NetCfg_DTCM : 8|1@1+ (1,0) [0|0] "" IRCM,SGW,PCM,TCM,RF_HUB,IC,ESC,ECM,ASCM
 SG_ NetCfg_ECM : 9|1@1+ (1,0) [0|0] "" IRCM,SGW,PCM,TCM,RF_HUB,ORC,ECM
 SG_ NetCfg_EPS : 10|1@1+ (1,0) [0|0] "" SGW,PCM,RF_HUB,ECM
 SG_ NetCfg_ESM : 11|1@1+ (1,0) [0|0] "" SGW,PCM,RF_HUB,ECM
 SG_ NetCfg_ESC : 12|1@1+ (1,0) [0|0] "" IRCM,SGW,PCM,TCM,RF_HUB,ECM
 SG_ NetCfg_EPB : 13|1@1+ (1,0) [0|0] "" SGW,PCM,RF_HUB,ECM
 SG_ NetCfg_RF_HUB : 14|1@1+ (1,0) [0|0] "" IRCM,SGW,PCM,RF_HUB,ECM
 SG_ NetCfg_IC : 15|1@1+ (1,0) [0|0] "" IRCM,SGW,PCM,TCM,RF_HUB,ECM
 SG_ NetCfg_DASM : 16|1@1+ (1,0) [0|0] "" IRCM,SGW,ITBM,PCM,TCM,RF_HUB,IC,ESC,ECM
 SG_ NetCfg_FDCM : 17|1@1+ (1,0) [0|0] "" SGW,RF_HUB,IC
 SG_ NetCfg_EPPM : 18|1@1+ (1,0) [0|0] "" SGW,RF_HUB,ORC
 SG_ NetCfg_ORC : 19|1@1+ (1,0) [0|0] "" IRCM,SGW,PCM,RF_HUB,ECM
 SG_ NetCfg_PTS : 20|1@1+ (1,0) [0|0] "" SGW,RF_HUB,IC
 SG_ NetCfg_SCCM : 23|1@1+ (1,0) [0|0] "" IRCM,SGW,PCM,TCM,RF_HUB,ORC,ECM
 SG_ NetCfg_ELSD : 24|1@1+ (1,0) [0|0] "" SGW,RF_HUB,ESC
 SG_ NetCfg_TCM : 25|1@1+ (1,0) [0|0] "" IRCM,SGW,PCM,RF_HUB,ESM,ESC,ECM
 SG_ NetCfg_TPM : 26|1@1+ (1,0) [0|0] "" SGW,RF_HUB,ORC
 SG_ NetCfg_PASS_PT : 27|1@1+ (1,0) [0|0] "" SGW,RF_HUB
 SG_ NetCfg_AFLS : 28|1@1+ (1,0) [0|0] "" SGW,RF_HUB,IC
 SG_ NetCfg_ITBM : 29|1@1+ (1,0) [0|0] "" IRCM,SGW,RF_HUB,PTS,IC
 SG_ NetCfg_OCM : 30|1@1+ (1,0) [0|0] "" SGW,RF_HUB,ORC
 SG_ NetCfg_HaLF : 31|1@1+ (1,0) [0|0] "" SGW,RF_HUB
 SG_ NetCfg_ANC : 39|1@1+ (1,0) [0|0] "" SGW,RF_HUB
 SG_ NetCfg_HCP : 38|1@1+ (1,0) [0|0] "" SGW,RF_HUB
 SG_ NetCfg_ESL : 37|1@1+ (1,0) [0|0] "" SGW,RF_HUB
 SG_ NetCfg_BSMO : 36|1@1+ (1,0) [0|0] "" SGW,RF_HUB
 SG_ NetCfg_SGW : 34|1@1+ (1,0) [0|0] "" SGW,RF_HUB
 SG_ NetCfg_DPDM : 33|1@1+ (1,0) [0|0] "" SGW,RF_HUB
 SG_ NetCfg_ASBS : 35|1@1+ (1,0) [0|0] "" SGW,RF_HUB
 SG_ NetCfg_ATMM : 32|1@1+ (1,0) [0|0] "" SGW,RF_HUB,IC
 SG_ NetCfg_SWSM : 57|1@1+ (1,0) [0|0] "" SGW,RF_HUB
 SG_ NetCfg_MSBD : 56|1@1+ (1,0) [0|0] "" SGW,RF_HUB

BO_ 998 BU_NET_CFG_INT: 8 RF_HUB
 SG_ BU_NET_CFG_STAT_INT : 0|2@1+ (1,0) [0|0] "" SGW,CBC
 SG_ BU_NetCfg_RBSS : 2|1@1+ (1,0) [0|0] "" SGW,CBC
 SG_ BU_NetCfg_BSM : 3|1@1+ (1,0) [0|0] "" SGW,CBC
 SG_ BU_NetCfg_CBC_IN : 4|1@1+ (1,0) [0|0] "" SGW,CBC
 SG_ BU_NetCfg_CSWM : 5|1@1+ (1,0) [0|0] "" SGW,CBC
 SG_ BU_NetCfg_DCM_DR : 6|1@1+ (1,0) [0|0] "" SGW,CBC
 SG_ BU_NetCfg_DCM_PASS : 7|1@1+ (1,0) [0|0] "" SGW,CBC
 SG_ BU_NetCfg_DCM_RL : 8|1@1+ (1,0) [0|0] "" SGW,CBC
 SG_ BU_NetCfg_DCM_RR : 9|1@1+ (1,0) [0|0] "" SGW,CBC
 SG_ BU_NetCfg_HVAC : 10|1@1+ (1,0) [0|0] "" SGW,CBC
 SG_ BU_NetCfg_MSM : 11|1@1+ (1,0) [0|0] "" SGW,CBC
 SG_ BU_NetCfg_PLG : 12|1@1+ (1,0) [0|0] "" SGW,CBC
 SG_ BU_NetCfg_VTM : 13|1@1+ (1,0) [0|0] "" SGW,CBC
 SG_ BU_NetCfg_PSD_LT : 14|1@1+ (1,0) [0|0] "" SGW,CBC
 SG_ BU_NetCfg_PSD_RT : 15|1@1+ (1,0) [0|0] "" SGW,CBC
 SG_ BU_NetCfg_FSM : 16|1@1+ (1,0) [0|0] "" SGW,CBC
 SG_ BU_NetCfg_PTCM : 17|1@1+ (1,0) [0|0] "" SGW,CBC
 SG_ BU_NetCfg_RBC : 18|1@1+ (1,0) [0|0] "" SGW,CBC
 SG_ BU_NetCfg_DTV : 19|1@1+ (1,0) [0|0] "" SGW,CBC
 SG_ BU_NetCfg_TGW : 20|1@1+ (1,0) [0|0] "" SGW,CBC
 SG_ BU_NetCfg_CLOCK : 21|1@1+ (1,0) [0|0] "" SGW,CBC
 SG_ BU_NetCfg_VSIM : 22|1@1+ (1,0) [0|0] "" SGW,CBC
 SG_ BU_NetCfg_ITM : 23|1@1+ (1,0) [0|0] "" SGW,CBC
 SG_ BU_NetCfg_AMP_I : 24|1@1+ (1,0) [0|0] "" SGW,CBC
 SG_ BU_NetCfg_DVD_CDM : 25|1@1+ (1,0) [0|0] "" SGW,CBC
 SG_ BU_NetCfg_HFM_CTM : 26|1@1+ (1,0) [0|0] "" SGW,CBC
 SG_ BU_NetCfg_ICS_I : 27|1@1+ (1,0) [0|0] "" SGW,CBC
 SG_ BU_NetCfg_VES2_I : 28|1@1+ (1,0) [0|0] "" SGW,CBC
 SG_ BU_NetCfg_VES3_I : 29|1@1+ (1,0) [0|0] "" SGW,CBC
 SG_ BU_NetCfg_CRSM : 30|1@1+ (1,0) [0|0] "" SGW,CBC
 SG_ BU_NetCfg_HVAC_R : 31|1@1+ (1,0) [0|0] "" SGW,CBC
 SG_ BU_NetCfg_DCSD : 37|1@1+ (1,0) [0|0] "" SGW,CBC
 SG_ BU_NetCfg_TBM : 38|1@1+ (1,0) [0|0] "" SGW,CBC
 SG_ BU_NetCfg_CVPM : 32|1@1+ (1,0) [0|0] "" SGW,CBC
 SG_ BU_NetCfg_TMM : 33|1@1+ (1,0) [0|0] "" SGW,CBC
 SG_ BU_NetCfg_ICS_R : 34|1@1+ (1,0) [0|0] "" SGW,CBC
 SG_ BU_NetCfg_MSM_PASS : 35|1@1+ (1,0) [0|0] "" SGW,CBC
 SG_ BU_NetCfg_VRM : 36|1@1+ (1,0) [0|0] "" SGW,CBC
 SG_ BU_NetCfg_ANC_I : 39|1@1+ (1,0) [0|0] "" SGW,CBC
 SG_ BU_NetCfg_TTM : 47|1@1+ (1,0) [0|0] "" SGW,CBC
 SG_ BU_NetCfg_UPFM : 46|1@1+ (1,0) [0|0] "" SGW,CBC
 SG_ BU_NetCfg_PSSM : 45|1@1+ (1,0) [0|0] "" SGW,CBC

BO_TX_BU_ 992 : PCM,ECM;
BO_TX_BU_ 257 : PCM,ECM;
BO_TX_BU_ 264 : PCM,ECM;
BO_TX_BU_ 280 : PCM,ECM;
BO_TX_BU_ 288 : PCM,ECM;
BO_TX_BU_ 308 : PCM,ECM;
BO_TX_BU_ 324 : PCM,TCM;
BO_TX_BU_ 352 : DTCM,CBC;
BO_TX_BU_ 368 : PCM,TCM;
BO_TX_BU_ 376 : PCM,TCM;
BO_TX_BU_ 384 : PCM,ECM;
BO_TX_BU_ 416 : PCM,TCM;
BO_TX_BU_ 559 : PCM,ECM;
BO_TX_BU_ 632 : PCM,ECM;
BO_TX_BU_ 672 : PCM,ECM;
BO_TX_BU_ 680 : PCM,TCM;
BO_TX_BU_ 698 : SGW,ETM;
BO_TX_BU_ 760 : PCM,ECM;
BO_TX_BU_ 761 : PCM,TCM;
BO_TX_BU_ 764 : PCM,ECM;
BO_TX_BU_ 766 : PCM,ECM;
BO_TX_BU_ 779 : PCM,ECM;
BO_TX_BU_ 810 : PCM,ECM;
BO_TX_BU_ 850 : SGW,DIAGNOST;
BO_TX_BU_ 863 : PCM,ECM;
BO_TX_BU_ 864 : PCM,ECM;
BO_TX_BU_ 872 : PCM,TCM;
BO_TX_BU_ 880 : PCM,ECM;
BO_TX_BU_ 888 : PCM,TCM;
BO_TX_BU_ 896 : PCM,ECM;
BO_TX_BU_ 904 : PCM,TCM;
BO_TX_BU_ 912 : PCM,ECM;
BO_TX_BU_ 920 : PCM,TCM;
BO_TX_BU_ 928 : PCM,ECM;
BO_TX_BU_ 936 : PCM,ECM;
BO_TX_BU_ 944 : SGW,DIAGNOST;
BO_TX_BU_ 945 : PCM,TCM;
BO_TX_BU_ 946 : PCM,TCM;
BO_TX_BU_ 993 : PCM,ECM;

CM_ SG_ 992 VIN_MSG "VIN Message Information";
CM_ SG_ 992 VIN_DATA "VIN Digits (8 bit ascii encoded) - see Signal Description Doc for details";
CM_ SG_ 257 CARB_Temp "CARB warmup criteria is true [1]";
CM_ SG_ 257 Inp_GD_Fail "Inputs to the general denominator are in a pend or MIL fault.";
CM_ SG_ 257 InpICC_Fail "Inputs to the Ign Cycle Cntr are in a Pend or MIL cond.";
CM_ SG_ 257 CARB_PERM "CARB permanent fault code drive cycle";
CM_ SG_ 257 OBD_GnrlDenCond_Stat "General denominator conditions are met [1].";
CM_ SG_ 257 IgnCntrTrue "Ignition cycle counter is true [1]";
CM_ SG_ 257 ENGINE_RESET "ECM Reset Notification";
CM_ SG_ 257 ECM_SKIM_STAT "ECM Skim Status";
CM_ SG_ 257 EngLoad_OBD "Load value for OBD (ISO 15031-5.4 PID 4)";
CM_ SG_ 257 AccelPdlPosn_OBD "Pedal value for OBD (ISO 15031-5.4 PID 49)";
CM_ SG_ 257 RAD_FAN1_STAT "Low speed or single radiator fan requested duty cycle";
CM_ SG_ 258 LRW "Steering wheel angle";
CM_ SG_ 258 LRW_PLRTY "Steering angle polarity (0=ISO 8855 Polarity and CCW = Positive)";
CM_ SG_ 258 VLRW "Delta steering wheel angle";
CM_ SG_ 258 LRWS_ST "Steering wheel angle sensor status";
CM_ SG_ 258 Pad_Shft "Paddle Shift";
CM_ SG_ 258 MC_STW_Angle_STAT "Message counter";
CM_ SG_ 258 CRC_STW_Angle_STAT "CRC-checksum byte 1 to 7 according to SAE J1850";
CM_ SG_ 264 EngRPM "Engine revolutions per minute";
CM_ SG_ 264 EngTrqStatic "Static engine torque / Effective engine torque";
CM_ SG_ 264 ExpEngTrq "Expected Engine Torque based on target engine speed";
CM_ SG_ 264 MC_ECM_A1 "Message counter";
CM_ SG_ 264 CRC_ECM_A1 "CRC-checksum byte 1 to 7 according to SAE J1850";
CM_ SG_ 264 ECM_LHOM_Trans "Torque Accuracy Information for Transmission";
CM_ SG_ 268 EngTrq_Rq_ESC "Engine torque request";
CM_ SG_ 268 DAS_Enbl_Rq "Enable DAS request; True = [1]";
CM_ SG_ 268 EngTrqMax_Rq_ESC "Engine torque request maximum";
CM_ SG_ 268 EngTrqMin_Rq_ESC "Engine torque request minimum";
CM_ SG_ 268 EngTrq_Rq_As "Engine torque request";
CM_ SG_ 268 ASRActive "Traction control is active";
CM_ SG_ 268 EngTrqMax_Rq_AS "Engine torque request maximum; True = [1]";
CM_ SG_ 268 BrkBstrVac "Brake Booster Vacuum Level";
CM_ SG_ 268 PrefillActive "Brake prefill is active - True = [1]";
CM_ SG_ 268 TrlrBrkRq "Trailor brake request percentage";
CM_ SG_ 268 DsblFuelShutOff "Disable fuel shutoff; True = [1]";
CM_ SG_ 268 DAS_RqActv "DAS request active";
CM_ SG_ 268 Brk_Jrk_Rsp "Brake jerk response; True = [1]";
CM_ SG_ 268 MC_ENG_RQ_ESC "Message counter";
CM_ SG_ 268 CRC_ENG_RQ_ESC "CRC-checksum byte 1 to 7 according to SAE J1850";
CM_ SG_ 280 EngTrqMax "Maximum engine torque";
CM_ SG_ 280 ANL_LFT "Starter motor running (Cranking)";
CM_ SG_ 280 Clutch_Disengg "Clutch upstop position:  Upstop=[0]; partial=[1]";
CM_ SG_ 280 ClutchInterLk "Clutch interlock switch, clutch depressed = [0]";
CM_ SG_ 280 EngTrqMin "Minimum engine torque";
CM_ SG_ 280 MdsAct "MDS Active";
CM_ SG_ 280 FullOFC_Actv "Cylinder cut-out";
CM_ SG_ 280 CYL_CUT_POSS "Cylinder cut-out conditions fulfilled";
CM_ SG_ 280 StartRelayBCMCmd "Engine restart request for StopStart function";
CM_ SG_ 280 MC_ECM_ENG_TRQ "Message counter";
CM_ SG_ 280 CRC_ECM_ENG_TRQ "CRC-checksum byte 1 to 7 according to SAE J1850";
CM_ SG_ 280 MdsActforANC "MDS active for ANC; Active = [1]";
CM_ SG_ 280 ECM_WTS_Inhbt "Wait to start inhibit";
CM_ SG_ 284 VehSpSts "Vehicle is stopped status signal";
CM_ SG_ 284 VEH_SPEED "Vehicle speed";
CM_ SG_ 284 MC_VEH_SPEED "Message counter";
CM_ SG_ 284 CRC_VEH_SPEED "CRC-checksum byte 1 to 7 according to SAE J1850";
CM_ SG_ 284 BrkTrq_D "Brake torque requested by driver";
CM_ SG_ 284 BrkTrq "Actual brake torque";
CM_ SG_ 288 EngTrqSel_D_TTC "Corrected (substitute) driver torque demand";
CM_ SG_ 288 EngTrq_Enbl_Rq_AS "Allow LCM torque requests";
CM_ SG_ 288 EngTrq_Enbl_Rq_ESC "Allow ESC torque request";
CM_ SG_ 288 EngTrq_Enbl_Rq_TCM "Allow TRANS torque request";
CM_ SG_ 288 AccelPdlPosn "Throttle Pedal Position (Calculated)";
CM_ SG_ 288 EngTrq_DrvReqMod "Driver requested engine torque modifed";
CM_ SG_ 288 ECM_LHOM "Engine in limp home mode";
CM_ SG_ 288 AccelPdlPosnSens_Flt "Accelerator pedal position sensor fault";
CM_ SG_ 288 CRUISE_OVERRIDE "Driver is over-riding cruise set speed";
CM_ SG_ 288 RPMOverRev "RPM Overrev condition has occurred";
CM_ SG_ 288 LV12PwrFreeRq "Level 1 or 2 power free request - engine controller has depowered the throttle body";
CM_ SG_ 288 MC_ECM_A2 "Message counter";
CM_ SG_ 288 CRC_ECM_A2 "CRC-checksum byte 1 to 6 according to SAE J1850";
CM_ SG_ 288 ESS_RqShftPark "ESS Request shift to Park.  1 = True, 0 = False";
CM_ SG_ 290 KickDnSw_Psd "kick-down (change-over scenario open!)";
CM_ SG_ 290 TxAC_EMCC_rq "Transmission  AC converter clutch slip request; [1] = True";
CM_ SG_ 290 EngTrqMaxCorrFctr "Factor of reduction from max. torque";
CM_ SG_ 290 GrMin_Rq_ECM "Target gear lower limit (ECM requested limit)";
CM_ SG_ 290 GrMax_Rq_ECM "Target gear upper limit (ECM requested limit)";
CM_ SG_ 290 NMOTS "Target idle speed";
CM_ SG_ 290 EngTrq_Ack_ECM "Acknowledge TRANS torque request";
CM_ SG_ 292 WhlPlsCnt_FL "Wheel pulse counter front left (96 per rotation)";
CM_ SG_ 292 WhlPlsCnt_FR "Wheel pulse counter front right (96 per rotation)";
CM_ SG_ 292 WhlPlsCnt_RL "Wheel pulse counter rear left (96 per rotation)";
CM_ SG_ 292 WhlPlsCnt_RR "Wheel pulse counter rear right (96 per rotation)";
CM_ SG_ 292 CENT_DIFF_ESP_RQ "ESP Requested Center  Differential State";
CM_ SG_ 292 R_DIFF_ESP_RQ "ESP Requested Rear Differential State";
CM_ SG_ 292 CENT_DIFF_TRQ_RQ "Desired Torque for Center Diff";
CM_ SG_ 308 CRUISE_EGD "Cruise system is controlling speed";
CM_ SG_ 308 CRUISE_ON "Cruise control system 'on'";
CM_ SG_ 308 V_MAX_TM "Max. or cruise control set speed";
CM_ SG_ 308 MAP_ENG "Intake manifold pressure, extended rangeEDR ONLY - Intake manifold pressure";
CM_ SG_ 308 BARO_ENG "Ambient air pressure (barometric pressure)";
CM_ SG_ 308 Rel_Thrt_ENG "Relative throttle value";
CM_ SG_ 308 Rel_Pdl_ENG "Relative pedal value";
CM_ SG_ 308 MC_134h "Message counter";
CM_ SG_ 320 Brk_Stat "Brake state";
CM_ SG_ 320 BrkPdl_Stat "Brake pedal state";
CM_ SG_ 320 BrkPdl_Flt "Brake Pedal Fault is active, 1=Faulted";
CM_ SG_ 320 BrkIntrvntn_Actv_ESP "Brake intervention by ESP active";
CM_ SG_ 320 BrkIntrvntn_Actv_AS "Brake intervention by assistance system active";
CM_ SG_ 320 BrkIntrvntn_Enbl "Brake intervention enabled";
CM_ SG_ 320 EmgBrk_Actv "Emergency braking";
CM_ SG_ 320 FullBrk_Actv "Maximum (hard) braking (ALS controls all wheels)";
CM_ SG_ 320 ESP_Sys_Stat "ESP system state";
CM_ SG_ 320 ABS_BrkEvt "Any ABS brake event";
CM_ SG_ 320 DTR_CC_Engaged "ACC is engaged; True = [1]";
CM_ SG_ 320 GrMin_Rq_ESC "Requested gear, lower limit";
CM_ SG_ 320 GrMax_Rq_ESC "Requested gear, upper limit";
CM_ SG_ 320 GrMinMax_Rq_DTR "Gear limit request from DTR";
CM_ SG_ 320 DTR_CC_Enabled "ACC is enabled; True = [1]";
CM_ SG_ 320 Brk_Thermdl "Brake thermal over target";
CM_ SG_ 320 ShftChrDsp_Rq_ESC "Shift characteristic displacement request";
CM_ SG_ 320 RollTestMd_Actv "Roller test bench mode active";
CM_ SG_ 320 REF_VEH_SPEED "Reference vehicle actual speed";
CM_ SG_ 320 SPCR_AS_Off_Rq "Assistance system off request";
CM_ SG_ 320 MC_Brk_Stat "Message counter";
CM_ SG_ 320 CRC_Brk_Stat "CRC-checksum byte 1 to 7 according to SAE J1850";
CM_ SG_ 324 K_STO_B "Conf. (torque converter lock-up) clutch 'starts to open'";
CM_ SG_ 324 EngSt_Enbl_Rq_TCM "Enable engine start request";
CM_ SG_ 324 Gr "Current Gear";
CM_ SG_ 324 Gr_Target "Target Gear";
CM_ SG_ 324 K_G_B "Conf. (torque converter lock-up) clutch 'closed'";
CM_ SG_ 324 K_O_B "Conf. (torque converter lock-up) clutch 'open'";
CM_ SG_ 324 K_S_B "Conf. (torque converter lock-up) clutch 'slip'";
CM_ SG_ 324 Trns_EMCC_Achvd "Trans A/C Converter Clutch Slipping; [1] = True";
CM_ SG_ 324 OUTPUT_SPEED "Output Shaft Speed";
CM_ SG_ 324 N_Turb "Unfiltered turbine speed (n_t_v)";
CM_ SG_ 324 OutputSpdPolarity "Output shaft speed polarity";
CM_ SG_ 324 TCM_TmpManMd "Transmission in temporary manual mode";
CM_ SG_ 324 TCM_ManMd "Transmission in manual mode";
CM_ SG_ 324 DrvRst_Hi "Drive resistance high/Grade detection";
CM_ SG_ 324 GearSwitchActiveSts "Transmission shift in progress";
CM_ SG_ 324 KS "Garage shift torque demand";
CM_ SG_ 324 TRNS_SPD_MC "TRNS_SPD message counter";
CM_ SG_ 324 Ups_Inh_Act "Upshift inhibit active";
CM_ SG_ 324 OD_OFF "Overdrive lock out";
CM_ SG_ 324 EngBrkCanRq "Engine braking cancel request";
CM_ SG_ 324 PTO_Enbl "PTO Enabled";
CM_ SG_ 331 BrkPrss_TMC "Master cylinder pressure";
CM_ SG_ 331 HSA_BrkPrss "Hill start assist brake pressure";
CM_ SG_ 331 BrkBstrVac_OBD "Brake booster vacuum level, raw";
CM_ SG_ 331 MC_ESP_A3 "Message counter";
CM_ SG_ 331 CRC_ESP_A3 "CRC-checksum byte 1 to 7 according to SAE J1850";
CM_ SG_ 332 VehYawRate_Raw "Vehicle yaw rate unfiltered/unadjusted (+ means left)";
CM_ SG_ 332 VehYawRate_Offset "Offset of vehicle yaw rate unfiltered/unadjusted (+ means left)";
CM_ SG_ 332 VehAccel_X_Offset "Offset of vehicle longitudinal acceleration (+ means forward)";
CM_ SG_ 332 VehAccel_X "Vehicle longitudinal acceleration (+ means forward)";
CM_ SG_ 332 VehAccel_Y "Vehicle lateral acceleration (+ means left, specific to center of gravity, offset-corrected )";
CM_ SG_ 332 MC_VEH_DYN_STAT "Message counter";
CM_ SG_ 332 VehAccel_Y_Offset "Offset of vehicle lateral acceleration (+ means left)";
CM_ SG_ 344 WhlRPM_FL "Wheel rpm front left";
CM_ SG_ 344 WhlDir_FL_Stat "Direction of rotation of front left wheel";
CM_ SG_ 344 WhlRPM_FR "Wheel rpm front right";
CM_ SG_ 344 WhlDir_FR_Stat "Direction of rotation of front right wheel";
CM_ SG_ 344 WhlRPM_RL "Wheel rpm rear left";
CM_ SG_ 344 WhlDir_RL_Stat "Direction of rotation of rear left wheel";
CM_ SG_ 344 WhlRPM_RR "Wheel rpm rear right";
CM_ SG_ 344 WhlDir_RR_Stat "Direction of rotation of rear right wheel";
CM_ SG_ 352 TCASE_STAT "Transfer Case Status";
CM_ SG_ 352 ACT_CNT_DIF_TRQ "Actual center differential torque lock";
CM_ SG_ 352 DES_CNT_DIF_TRQ "Desired center differential torque lock";
CM_ SG_ 352 SHFT_ABRT "Shift has been abortet";
CM_ SG_ 368 PRND_STAT "PRND Status";
CM_ SG_ 368 EngStEnblRqTCM "Engine start enable request from the transmission";
CM_ SG_ 368 SHFT_PROG "Driving program display code";
CM_ SG_ 368 PRNDL_DISP "PRNDL display request";
CM_ SG_ 368 SHFT_LOCK "Shiftlock state locked; false = [1]";
CM_ SG_ 368 PRNDL_Blink "Request gear shift display indicator blink";
CM_ SG_ 368 MC_TRNS_STAT "Message counter";
CM_ SG_ 368 CRC_TRNS_STAT "CRC-checksum byte 1 to 7 according to SAE J1850";
CM_ SG_ 368 APCM_Rq "Auto position correction mode request";
CM_ SG_ 376 MIL_OnRq_TCM "MIL on request from the transmission";
CM_ SG_ 376 GS_NOTL "TRANS in limp home mode";
CM_ SG_ 376 TxTemp_Excess "Excessive transmission temperature";
CM_ SG_ 376 FAN_RQ "Cooling fan request";
CM_ SG_ 376 TX_TEMP "Transmission fluid temperature";
CM_ SG_ 376 TX_WARN "Transmission warning";
CM_ SG_ 376 TX_FAULT "Transmission fault";
CM_ SG_ 384 IntkAirTemp "Engine Intake Air Temperature";
CM_ SG_ 384 EngCoolTemp "Engine coolant temperature";
CM_ SG_ 384 AirPress_Outsd "Ambient air pressure (barometric pressure)";
CM_ SG_ 384 SysVolt "Engine system voltage";
CM_ SG_ 384 R134a_Press_Stat "Refrigerant pressure (R134a or R1234YF)";
CM_ SG_ 384 CHRG_FAIL "Charging system Failure (battery indicator request)";
CM_ SG_ 384 AM_ECM_Prsnt "Aftermarket ECM present";
CM_ SG_ 384 AC_CLTCH_EGD "AC clutch engauged";
CM_ SG_ 416 Trans_Trq_Ratio "Transmission torque ratio";
CM_ SG_ 416 TxIdleRq "Transmission idle speed request";
CM_ SG_ 416 EngTrq_Rq_TCM "Engine torque request";
CM_ SG_ 416 EngTrqMax_Rq_TCM "Engine torque request maximum";
CM_ SG_ 416 EngTrqMin_Rq_TCM "Engine torque request minimum";
CM_ SG_ 416 MC_TCM_ENG_TRQ "Message counter";
CM_ SG_ 416 CRC_TCM_ENG_TRQ "CRC-checksum byte 1 to 6 according to SAE J1850";
CM_ SG_ 448 RFFuncReq "Basic request (RKE, PE, Remstart)";
CM_ SG_ 448 RFReq "Who's asking for the request";
CM_ SG_ 448 RFCfgReq "Change customer programmable items by RKE";
CM_ SG_ 448 RFFobNum "FOB number making the request";
CM_ SG_ 448 PE_ENABLE "Passive entry feature enabled; [1] = True";
CM_ SG_ 448 TFASts "Tire fill alert status; Disabled = [0], Enabled = [1]";
CM_ SG_ 456 VTA_STAT "VTA status";
CM_ SG_ 464 SRS_IndLmp_Rq "SRS indication lamp request";
CM_ SG_ 464 DRV_SEATBELT "Drivers seat belt status";
CM_ SG_ 464 PSG_SEATBELT "Passengers seat belt status";
CM_ SG_ 464 PSG_ODS_STAT "Passenger Occupant Detection Sensor Status";
CM_ SG_ 464 ORC_A1_Par "ORC_A1 even parity bit";
CM_ SG_ 464 ORC_A1_Tog "ORC_A1 toggle bit";
CM_ SG_ 464 DrvSbltUnFltr "Drivers seat belt fault status - unfiltered";
CM_ SG_ 466 IMPACT_B "EARS Rear Event; actuate = [1]; do_not_actuate = [0]";
CM_ SG_ 466 Impact_F "EARS lower severity front event; actuate = [1]; do_not_actuate = [0]";
CM_ SG_ 466 Impact_Tgl "Toggle bit for all impact events; See Signal Description Document";
CM_ SG_ 466 IMPACT_I "EARS Rollover Event; actuate = [1]; do_not_actuate = [0]";
CM_ SG_ 466 IMPACT_L "EARS Side Event; actuate = [1]; do_not_actuate = [0]";
CM_ SG_ 466 IMPACT_X "Any impact event; actuate = [1]; do_not_actuate = [0]";
CM_ SG_ 500 EngTrqRq_DAS "Requested engine torque";
CM_ SG_ 500 EngTrqMaxRq_DAS "Engine torque request maximum; True = [1]";
CM_ SG_ 500 DAS_ACCEL_Rq "DASM acceleration request";
CM_ SG_ 500 ACC_Enbl "ACC cruise control enabled; True = [1]";
CM_ SG_ 500 ACC_Engd "ACC engaged; True = [1]";
CM_ SG_ 500 DsblFuelShutOff_ACC "Disable fuel shutoff; True = [1]";
CM_ SG_ 500 GrMax_RqDAS "Requested gear, upper limit";
CM_ SG_ 500 DAS_Rq_ID "DAS request ID";
CM_ SG_ 500 DAS_Sts "DASM fault status";
CM_ SG_ 500 Brk_Jrk_Rq "Brake jerk request; True = [1]";
CM_ SG_ 500 Brk_PreFill_Rq "Brakes pre-fill request; True = [1]";
CM_ SG_ 500 As_DispRq "Assistance system display request (priority)";
CM_ SG_ 500 MC_DAS_A3 "Message counter";
CM_ SG_ 500 CRC_DAS_A3 "CRC-checksum byte 1 to 7 according to SAE J1850";
CM_ SG_ 500 ACC_Drive_Cmd "ACC drive off commanded; True = [1]";
CM_ SG_ 500 ACC_Still_Cmd "ACC stop commanded; True = [1]";
CM_ SG_ 501 HMI_Screens "HMI screens";
CM_ SG_ 501 SetSpeed_KPH "Desired set speed in kilometers per hour";
CM_ SG_ 501 SetSpeed_MPH "Desired set speed in miles per hour";
CM_ SG_ 501 FCW_Error "Forward collision warning error";
CM_ SG_ 501 ACCOnOff "ACC on off status";
CM_ SG_ 501 Sm_ICON_Dspl "Small graphic display";
CM_ SG_ 501 RadarBlocked "ACC FCW not available: clean radar snsr; True = [1]";
CM_ SG_ 501 ACConlyNA_DASMSts "ACC only not available: vehicle system error; True = [1]";
CM_ SG_ 501 NCConlyNA_DASMSts "NCC only not available: vehicle system error; True = [1]";
CM_ SG_ 501 ACCFaulted "ACC faulted; True = [1]";
CM_ SG_ 501 FCWonlyNA_DASMSts "FCW only not available: vehicle system error; True = [1]";
CM_ SG_ 501 ACCNA_DASMSts "ACC/FCW not avail: vehicle system error; True = [1]";
CM_ SG_ 501 NCCNA_DASMSts "NCC/FCW not avail: vehicle system error; True = [1]";
CM_ SG_ 501 ObjIntrstDist "Object of interest distance";
CM_ SG_ 501 CameraBlocked "ACC FCW limited functionality: camera blocked; True = [1]";
CM_ SG_ 501 CameraFailure "ACC/FCW limited functionality: camera failure; True = [1]";
CM_ SG_ 501 CIPV_Fused "Closest in-path vehicle is fused; True = [1]";
CM_ SG_ 501 FCW_BrkOn "FCW braking is on; true = [1]";
CM_ SG_ 501 FCWBrakingOff "FCW autobraking disabled; True = [1]";
CM_ SG_ 501 ACC_EB_Req "Request for exhaust break;1='On'";
CM_ SG_ 512 AirTemp_Outsd "Outside air temperature";
CM_ SG_ 512 AMB_TEMP_AVG "Averaged ambient temperature";
CM_ SG_ 512 AMB_TEMP_VOLT "Ambient Temp Sensor A/D Voltage";
CM_ SG_ 512 FUEL_VOLT "Fuel level A/D Voltage (Single tank OR Primary on Saddle/Dual Tank)";
CM_ SG_ 512 FUEL_VOLT2 "Sub Side Fuel level sensor A/D Voltage (saddle/Dual tank)";
CM_ SG_ 512 BATT_VOLT "System voltage";
CM_ SG_ 514 BrkPdlRawStat "Brake pedal state raw value";
CM_ SG_ 520 AC_OutptCurrStat "AC output current status";
CM_ SG_ 520 BrkPdlStat_CBC "Brake pedal state reported by CBC";
CM_ SG_ 557 HrnSwPsd "Horn switch pressed (1=pressed)";
CM_ SG_ 559 ActlAccelPdlPosn "Throttle Pedal Position (actual)";
CM_ SG_ 559 MC_ECM_A5 "Message counter";
CM_ SG_ 559 CRC_ECM_A5 "CRC-checksum byte 1 to 7 according to SAE J1850";
CM_ SG_ 559 ECM_WARN_BTO "Status of the BTO failure is transmitted from ECM to cluster, appropriate EVIC message will be displayed by cluster";
CM_ SG_ 584 PN14_LS_Actv "14 V powernet Load Shed active";
CM_ SG_ 584 Batt_ST_Crit "Battery reached critical state";
CM_ SG_ 608 CRC_PTS_2 "CRC-checksum byte 1 to 7 according to SAE J1850";
CM_ SG_ 608 MC_PTS_2 "Message counter";
CM_ SG_ 608 PTS_FT_TEMP_NA "ParkSense front system temporarily not available; True = [1]";
CM_ SG_ 608 PTS_Off_Status "ParkSense system on/off status indication";
CM_ SG_ 608 PTS_PopUpRqst "ParkSense HMI pop-up message request";
CM_ SG_ 608 PTS_RR_TEMP_NA "ParkSense rear system temporarily not available; True = [1]";
CM_ SG_ 608 PTS_STAT_Front "Front park assist system - LED control status";
CM_ SG_ 608 LooseShip_Rear "Rear LooseShip customer setting confirmation. Enabled = [1]";
CM_ SG_ 608 LooseShip_Front "Front LooseShip customer setting confirmation. Enabled = [1]";
CM_ SG_ 624 EngineOffTimer "Engine off timer - engine off ignition NOT lock.";
CM_ SG_ 624 PNC_ALM_ACT "Panic alarm active; [1] = True";
CM_ SG_ 624 Gate_Req_PE "Gate passive entry requested; True = [1]";
CM_ SG_ 624 FuelTxfrSts "Fuel transfer relay status";
CM_ SG_ 624 HAZARD_STATUS "Hazard lamps; active = [1]";
CM_ SG_ 632 CC_SetSpdDspl "Cruise control set speed for display (kmph only)";
CM_ SG_ 632 EVPmpStat "Electric vacuum pump status";
CM_ SG_ 632 CC_SetSpdDsplMPH "Cruise control set speed for display in miles per hour";
CM_ SG_ 632 IdleShutDwnApply "Idle Shut down applied; 1 = True";
CM_ SG_ 632 EnblFuelTxfr "Enable fuel transfer; True = [1]";
CM_ SG_ 639 IBS_Q_received "LifeTime charge received";
CM_ SG_ 639 IBS_Q_released "Lifetime charge released";
CM_ SG_ 639 IBS_Tm_Lst_Reset_Sec "Accumulated time since last reset in seconds";
CM_ SG_ 639 IBS_Tm_Lst_Reset_Days "Accumulated time since last reset in days";
CM_ SG_ 656 UConnSeed1 "Character 1";
CM_ SG_ 656 UConnSeed2 "Character 2";
CM_ SG_ 656 UConnSeed3 "Character 3";
CM_ SG_ 656 UConnSeed4 "Character 4";
CM_ SG_ 660 MC_294h "Message counter";
CM_ SG_ 660 CRC_294h "CRC-checksum byte 1 to 7 according to SAE J1850";
CM_ SG_ 660 BrkPrss_One "Brake Pressure One (P1)";
CM_ SG_ 660 BrkPrss_Two "Brake Pressure Two (P2 if supported)";
CM_ SG_ 660 SyncPos "Signal P2 sync position";
CM_ SG_ 672 MIL_OnRq "MIL on request from the engine";
CM_ SG_ 672 MIL_IND_BLINK "Request MIL blink (OBD II)";
CM_ SG_ 672 ETC_IND_LMP "ETC faulty, indicator lamp request";
CM_ SG_ 672 OIL_IND_LMP_FLSH "Oil indicator lamp flash (for in plant use)";
CM_ SG_ 672 EngOilIndLmp_On_Rq "Request oil level/oil pressure indicator lamp";
CM_ SG_ 672 OIL_TEMP_IND_RQ "Engine oil overtemp. indicator request";
CM_ SG_ 672 ChkFuelCap "Check fuel cap";
CM_ SG_ 672 OIL_PRESS "Oil pressure";
CM_ SG_ 672 EngOilTemp "Oil temperature";
CM_ SG_ 672 FuelCons "Fuel consumption";
CM_ SG_ 672 DefFuelEcon "Default fuel economy";
CM_ SG_ 672 EngRun_Stat "Engine running state";
CM_ SG_ 672 CoolLo "Engine coolant is low";
CM_ SG_ 680 EngTrgtSpdCtrl "Engine target speed control";
CM_ SG_ 680 EngShutOffRq_TCM "TCM request engine shut off";
CM_ SG_ 680 EngTrgtSpdCtrl_Active "Engine target speed control active";
CM_ SG_ 680 CurrentGear "Current Gear";
CM_ SG_ 680 CurrentGearForDisplay "Current Gear for display";
CM_ SG_ 680 TargetGear "Target Gear - protected";
CM_ SG_ 680 TX_WARN2 "Transmission warning #2";
CM_ SG_ 680 MC_TCM_A7 "Message counter";
CM_ SG_ 680 CRC_TCM_A7 "CRC-checksum byte 1 to 7 according to SAE J1850";
CM_ SG_ 698 UConnReq "Basic Uconnect request";
CM_ SG_ 698 UConnReqAuthCode "Authorization for requests";
CM_ SG_ 698 UConnReqFOBNum "FOB number making the request";
CM_ SG_ 706 EC_ECUCfg15_Stat "ECU Configuration messages status 15";
CM_ SG_ 706 EC_CBC15A "CBC ecu configuration 15A";
CM_ SG_ 706 EC_CBC15B "CBC ecu configuration 15B";
CM_ SG_ 706 EC_Suspension "Suspension ecu configuration";
CM_ SG_ 707 EC_BU_ECUCfg15_Stat "Backup for ECU Configuration messages status 15";
CM_ SG_ 707 EC_BU_CBC15A "Backup for CBC ecu configuration 15A";
CM_ SG_ 707 EC_BU_CBC15B "Backup for CBC ecu configuration 15B";
CM_ SG_ 707 EC_BU_Suspension "Backup for Suspension ecu configuration";
CM_ SG_ 719 PTS_DBD "Park assist system disabled; System_Disabled = [1]";
CM_ SG_ 720 BSM_CFG_STAT "BSM configuration status";
CM_ SG_ 720 BSM_SRV_RQ "BSM service warning request; 1= service request";
CM_ SG_ 720 BSM_OPR_STAT "BSM operation status; 1= operational failure";
CM_ SG_ 720 BSM_Blind_RQ "Sensor blinded request from BSM; 1= sensor blocked request";
CM_ SG_ 720 BSM_LT_WRN "Blind spot detection left side warning";
CM_ SG_ 720 BSM_RT_WRN "Blind spot detection Right side warning";
CM_ SG_ 736 LT_DIST "Distance Traveled by Left Wheel";
CM_ SG_ 736 RT_DIST "Distance Traveled by Right Wheel";
CM_ SG_ 736 YRS_DataRq "Request from ESC for YRS information";
CM_ SG_ 736 HSA_EN "Hill Start Assist enabled (1=enabled)";
CM_ SG_ 736 ESP_DSBL "ESP feature is completely disabled = [1]";
CM_ SG_ 736 HILL_DES_STAT "Hill descent feature status";
CM_ SG_ 736 ESP_Off_IndLmp_On_Rq "ESP-OFF indication lamp on request";
CM_ SG_ 736 ESC_CtrlLmp_Info "ESC control lamp information";
CM_ SG_ 736 ABS_IndLmp_On_Rq "ABS indication lamp on request";
CM_ SG_ 736 BrkIndLmp_On_Rq_ESC "Brake indication lamp (red) on request";
CM_ SG_ 736 SelSpdLmp "Select speed lamp status";
CM_ SG_ 746 DrvRqShftROT "Driver requested gear shift position";
CM_ SG_ 746 ShftSensFltROT "Shift sensor single fault - rotary shifter, 1=fault";
CM_ SG_ 746 ShftDispFltROT "Gear shifter display/trigger fault status - rotary shifter, 1=fault";
CM_ SG_ 746 ShftLkFltROT "Shift lock fault - rotary shifter, 1=fault";
CM_ SG_ 746 MC_SBW_ROT1 "Message counter";
CM_ SG_ 746 CRC_SBW_ROT1 "CRC-checksum byte 1 to 4 according to SAE J1850";
CM_ SG_ 746 APCM_Stat "Auto position correction mode status";
CM_ SG_ 746 RackFlt "Rack / detent sensor fault, 1=fault";
CM_ SG_ 760 EngTrqTgt_SEM "Target Torque  - trans trq. request";
CM_ SG_ 760 EngTrqStatic_SEM "Static engine torque - trans trq request";
CM_ SG_ 760 TRANS_CLU_SLIP_MODE "Clutch Slip Request Mode";
CM_ SG_ 760 ThrmlMngActv "Indicates ECM RPM Limitation Status, Active = 1";
CM_ SG_ 760 EngMaxRPM "Engine maximum RPM";
CM_ SG_ 760 MC_ECM_A3 "Message counter";
CM_ SG_ 760 CRC_ECM_A3 "CRC-checksum byte 1 to 7 according to SAE J1850";
CM_ SG_ 761 MC_TCM_EngTrq2 "Message counter";
CM_ SG_ 761 CRC_TCM_EngTrq2 "CRC-checksum byte 1 to 7 according to SAE J1850";
CM_ SG_ 764 ApplyTrq "EDR ONLY - Torque may be applied to the wheels";
CM_ SG_ 764 BrkSw1Stat "EDR ONLY - Brake switch1 status, off = [0]";
CM_ SG_ 764 ESP_TrqRqEnabl "EDR ONLY - ESP torque requests are allowed = [1]";
CM_ SG_ 764 ETC_LmpFlash "EDR ONLY - ETC lamp is flashing";
CM_ SG_ 764 ETC_LmpOn "EDR ONLY - ETC lamp is on";
CM_ SG_ 764 Lv1CrsCtrlOff "EDR ONLY - Level is requested cruise off";
CM_ SG_ 764 CruiseEGD "EDR ONLY - Cruise system is engaged";
CM_ SG_ 764 RawPVS1 "EDR ONLY - Raw pedal value sensor #1";
CM_ SG_ 764 RawPVS2 "EDR ONLY - Raw pedal value sensor #2";
CM_ SG_ 764 RawTPS1 "EDR ONLY - Raw throttle position sensor #1";
CM_ SG_ 764 RawTPS2 "EDR ONLY - Raw throttle position sensor #2";
CM_ SG_ 764 RelativePdl "EDR ONLY - Relative pedal value";
CM_ SG_ 764 RelativeThrt "EDR ONLY - Relative throttle value";
CM_ SG_ 764 MAP "EDR ONLY - Intake manifold pressure";
CM_ SG_ 766 VVT_ExhCam1Pos "EDR ONLY - Centerline position for exhaust cam on bank 1";
CM_ SG_ 766 VVT_ExhCam2Pos "EDR ONLY - Centerline position for exhaust cam on bank 2";
CM_ SG_ 766 VVT_IntCam1Pos "EDR ONLY - Centerline position for intake cam on bank 1";
CM_ SG_ 766 VVT_IntCam2Pos "EDR ONLY - Centerline position for intake cam on bank 2";
CM_ SG_ 766 GF_Charge "EDR ONLY - Port flow per cylinder per stroke";
CM_ SG_ 766 RelativeThrtPct "EDR ONLY - Relative throttle percent";
CM_ SG_ 776 CNT_DIFF_MOD "Actual mode of center differential";
CM_ SG_ 776 DTCM_HMI_Rq "DTCM AWD / 4WD HMI display request";
CM_ SG_ 776 TCASE_FAIL "T Case System Fault (Limp in)";
CM_ SG_ 776 TCASE_SRV_RQ "Transfer case service indicator request";
CM_ SG_ 776 TcaseAWD "Transfer case High range / AWD LED status";
CM_ SG_ 776 TCASE_INHBT "All wheel drive mode inhibited";
CM_ SG_ 776 Tcase4Low "Transfer case low range LED status";
CM_ SG_ 776 TcaseNtrlStat "Transfer case neutral LED status";
CM_ SG_ 776 Tcase4Lock "Transfer case 4WD locked status";
CM_ SG_ 776 Tcase2WD_Stat "Transfer case 2 wheel drive status";
CM_ SG_ 779 DisOilLifeRst "Distance since last oil life reset";
CM_ SG_ 779 OilLifeLeft "Oil life left";
CM_ SG_ 779 MntncSts "Maintenance reminder status";
CM_ SG_ 779 OilLifeLeftRst "Oil life remaining has been reset";
CM_ SG_ 779 HoursOilLifeRst "Hours since last oil life reset";
CM_ SG_ 779 FuelFltrRq "Fuel filter reminder request";
CM_ SG_ 779 FuelFltrLeft "Fuel filter life left";
CM_ SG_ 779 FuelFltrAck "Fuel filter reset acknowledge";
CM_ SG_ 784 AvgFuelLvl "Average filtered fuel level in liters";
CM_ SG_ 784 SRS_LMP_STAT "Airbag indicator lamp status";
CM_ SG_ 784 FuelLvlLow "Fuel level low";
CM_ SG_ 784 OilChgRst "Oil change reminder reset request";
CM_ SG_ 784 ODO "Odometer";
CM_ SG_ 784 WTS_LmpRqOn "Wait to start lamp requested on; true = [1]";
CM_ SG_ 784 Trailer_Trp_Rst "Trailer Trip Reset Request";
CM_ SG_ 784 FuelFltrRst "Fuel filter maintenance reminder reset";
CM_ SG_ 784 FuelSavDispEnbl "Fuel saver display indicator status (1=enabled)";
CM_ SG_ 788 CFG_FEATURE "Configurable feature";
CM_ SG_ 788 CFG_STAT_RQ "Configurable feature status request";
CM_ SG_ 788 CFG_SET "Specific setting or value (see reference)";
CM_ SG_ 790 CFG_FEATURE_C "Configurable feature";
CM_ SG_ 790 CFG_STAT_RQ_C "Configurable feature status request";
CM_ SG_ 790 CFG_SET_C "Specific setting or value (see reference)";
CM_ SG_ 792 TurnIndLvr_Stat "Turn indicator lever state";
CM_ SG_ 792 HiBmLvr_Stat "High beam lever state";
CM_ SG_ 792 WprWashSw_Psd "Front wiper switch pressed";
CM_ SG_ 792 WprSw6Posn "Wiper switch (6 stages) position";
CM_ SG_ 792 VOL "Volume up/down";
CM_ SG_ 792 Up_Arw_Rq "Up Arrow Request / Step";
CM_ SG_ 792 StW_TempSens_Flt "Steering wheel temperature sensor fault";
CM_ SG_ 792 StW_Temp "Steering wheel temperature";
CM_ SG_ 792 SEEK "Seek up/down";
CM_ SG_ 792 RT_ARW_RST_RQ "Right Arrow Reset Request";
CM_ SG_ 792 PRESET_CFG "Preset Configuration";
CM_ SG_ 792 MENU_RQ "Menu Switch Request / Back";
CM_ SG_ 792 HrnSw_Psd "Horn switch pressed (1=pressed)";
CM_ SG_ 792 DN_ARW_STEP_RQ "Down Arrow Request / Odometer Trip Reset";
CM_ SG_ 792 CELL_VR "Cell Phone/Voice Recognition Request";
CM_ SG_ 792 AUD_MODE_ADV "Audio-mode advance";
CM_ SG_ 799 IBS_R_Batt "Calculated battery resistance";
CM_ SG_ 799 IBS_R_Batt_25 "Batt resistance at 100% SOC and 25 degC";
CM_ SG_ 799 RainSensorFailSts "Fail present = 1";
CM_ SG_ 799 TGW_AUD_MD_CAB_DR "TGW audio mode for Cabin/Driver";
CM_ SG_ 799 PSS_Display "Power side step display";
CM_ SG_ 804 TurnLmp_FL_Flt "Turn indication lamp front left fault";
CM_ SG_ 804 TurnLmp_FR_Flt "Turn indication lamp front right fault";
CM_ SG_ 804 TurnLmp_RL_Flt "Turn indication lamp rear left fault";
CM_ SG_ 804 TurnLmp_RR_Flt "Turn indication lamp rear right fault";
CM_ SG_ 804 ACC_DLY_ACT "Accessory Delay Active";
CM_ SG_ 804 RemSt_Inhibit "Remote start inhibit";
CM_ SG_ 804 WPR_SYS_OFF "Wiper system off; [1] = switch is OFF";
CM_ SG_ 804 WPR_SYS_LOW "Wiper system low; [1] = switch is LOW";
CM_ SG_ 804 WPR_SYS_HIGH "Wiper system high; [1] = switch is HIGH";
CM_ SG_ 804 WPR_SYS_INT "Wiper system intermittent; [1] = switch is INT";
CM_ SG_ 804 WPR_SYS_AUTO "Wiper system auto; [1] = Auto wipers equipped";
CM_ SG_ 804 WPR_SYS_MIST "Wiper system mist; [1] = mist request";
CM_ SG_ 804 WPR_SYS_WASH "Wiper system wash; [1] = wash request";
CM_ SG_ 804 WPR_SYS_FLT "Wiper system fault present; [1] = fault present";
CM_ SG_ 804 AirSusp_DnSw "Air suspension down (Trailer) switch status";
CM_ SG_ 804 HdAjar "Hood latch ajar, left or single (1=ajar)";
CM_ SG_ 804 CargoLampOn "Cargo lamp is on";
CM_ SG_ 804 WTS_Active "Indicates WTS feature is active";
CM_ SG_ 804 CBC_WTS_AS "WTS automatic start is active";
CM_ SG_ 808 TGW_GrpNum_IC "TGW group number to IC";
CM_ SG_ 808 TGW_GrpTyp_IC "Group type to send text data from TGW to IC";
CM_ SG_ 808 TGW_HiGrpMark_IC "TGW high group mark to IC; [0] = Not True, [1] = True";
CM_ SG_ 808 TGW_TEXT_IC "TGW text string information to IC";
CM_ SG_ 810 PTO_Md "PTO mode selected";
CM_ SG_ 810 PTO_MaxVehSpd "PTO maximum vehicle speed";
CM_ SG_ 810 PTO_AutoRsm "PTO - resume on ignition on";
CM_ SG_ 810 PTO_TYPES "PTO type selected";
CM_ SG_ 810 PTO_ENGD_RQ "Power takeoff engage request";
CM_ SG_ 810 PTO_Incab "Power takeoff - in cab switch status; On = [1]";
CM_ SG_ 810 PTO_HornRq "Power ake Off HORN ON Request; On = 1";
CM_ SG_ 810 PTO_SingleRPM "PTO single set RPM";
CM_ SG_ 810 PTO_RPM1 "PTO preset 1 RPM setting";
CM_ SG_ 810 PTO_RPM2 "PTO preset 2 RPM setting";
CM_ SG_ 810 PTO_RPM3 "PTO preset 3 RPM setting";
CM_ SG_ 810 PTO_Sts "PTO warning status";
CM_ SG_ 810 FuelTransSts "Fuel transfer status";
CM_ SG_ 816 TRAC_PSD "Traction on/off button pressed; [0] = Not Pressed, [1] = Pressed";
CM_ SG_ 816 HILL_DES_RQ "Hill descent or select speed status";
CM_ SG_ 816 AHB_ENBL "Auto highbeam enable";
CM_ SG_ 816 phone_pop_up_active "Phone pop up is active; True = [1]";
CM_ SG_ 816 TILT_IN_REV_D "Tilt in reverese feature enabled; [0] = no, [1] = yes";
CM_ SG_ 816 RemStNrmlStEnbl_DCS "Driver comfort system remote & normal start status; [0] = Off, [1] = On";
CM_ SG_ 816 RemStEnbl_DCS "Driver comfort system remote start status; [0] = Off, [1] = On";
CM_ SG_ 816 EB_SW_PSD "Exhaust brake switch pressed (1=pressed)";
CM_ SG_ 820 FT_FOG_RQ "Front fog request; off=[0], on=[1]";
CM_ SG_ 820 REV_GEAR "Reverse Gear (manual trans)";
CM_ SG_ 820 DR_LK_STAT "Door lock status";
CM_ SG_ 820 FOB_SrchRq "FOB search request";
CM_ SG_ 820 AHB_ACT "Automatic high beam active";
CM_ SG_ 820 PARK_LMP_ON "Parklamps are on; off=[0], on=[1]";
CM_ SG_ 820 DRV_AJAR "Driver door ajar (1 = Door Ajar)";
CM_ SG_ 820 PSG_AJAR "Passenger door ajar";
CM_ SG_ 820 L_R_AJAR "Left rear door ajar";
CM_ SG_ 820 R_R_AJAR "Right rear door ajar";
CM_ SG_ 820 TLG_AJAR "Trunk/Liftgate ajar";
CM_ SG_ 820 PARK_BRK_EGD "Park brake switch engaged";
CM_ SG_ 820 IGN_OFF_TIME_LNG "Time since last ignition on (long)";
CM_ SG_ 820 SHIP_STAT "Shipping status";
CM_ SG_ 820 TurnInd_LT_ON "Turn indication left is on";
CM_ SG_ 820 TurnInd_RT_ON "Turn indication right is on";
CM_ SG_ 820 DAY_LGT_MD "Day light brightness mode; Night=[0], Day=[1]";
CM_ SG_ 820 PANEL_INTS "Panel-/display intensity";
CM_ SG_ 820 FT_WPR_NOT_PRK "Front wiper outside park position";
CM_ SG_ 820 LOBEAM_ON "Low beam is on; off=[0], on=[1]";
CM_ SG_ 820 HIBEAM_ON "High beam is on; off=[0], on=[1]";
CM_ SG_ 820 BRK_FLUID_LO "Low brake fluid warning; low = [1]";
CM_ SG_ 820 WASH_FLUID_LO "Low washer fluid warning (1=Fluid is low)";
CM_ SG_ 820 R_FOG_RQ "Rear fog request; [0] = off, [1] = on";
CM_ SG_ 820 PTC_REL1_STAT "PTC Relay # 1 Status (diesel only)";
CM_ SG_ 820 PTC_REL2_STAT "PTC Relay # 2 Status (diesel only)";
CM_ SG_ 820 PTC_REL3_STAT "PTC Relay # 3 Status (diesel only)";
CM_ SG_ 820 PoliceStlthMdAct "Police stealth mode active; true = [1]";
CM_ SG_ 825 PTS_RR_CHIME_RQ "PTS right rear chime on request; True = [1]";
CM_ SG_ 825 PTS_LR_CHIME_RQ "PTS left rear chime on request; True = [1]";
CM_ SG_ 825 PTS_CHIME_TYPE "PTS chime type";
CM_ SG_ 825 PTS_CHIME_REP_RATE "PTS chime repetition rate";
CM_ SG_ 825 PTS_RR_VOL "PTS Rear Volume Setting";
CM_ SG_ 825 PTS_FT_VOL "PTS Front Volume Setting";
CM_ SG_ 825 PTS_LF_CHIME_RQ "PTS left front chime on request; True = [1]";
CM_ SG_ 825 PTS_RF_CHIME_RQ "PTS right front chime on request; True = [1]";
CM_ SG_ 826 PTS_RR_NA "Rear park assist not available - blinded sensor; True = [1]";
CM_ SG_ 826 PTS_SRV_RQ "PTS service warning request; True = [1]";
CM_ SG_ 826 PTS_AlrRL "PTS alert rear left";
CM_ SG_ 826 PTS_GraphicRL "PTS graphic flash rate rear left";
CM_ SG_ 826 PTS_AlrRR "PTS alert rear right";
CM_ SG_ 826 PTS_GraphicRR "PTS graphic flash rate rear right";
CM_ SG_ 826 PTS_AlrRC "PTS alert rear center";
CM_ SG_ 826 PTS_GraphicRC "PTS graphic flash rate rear center";
CM_ SG_ 826 PTS_RR_SRV "Rear PTS sensor service request; True = [1]";
CM_ SG_ 826 PTS_STAT "Park Assist System - LED control status";
CM_ SG_ 826 PTS_AlrFC "PTS alert front center";
CM_ SG_ 826 PTS_AlrFL "PTS alert front left";
CM_ SG_ 826 PTS_AlrFR "PTS alert front right";
CM_ SG_ 826 PTS_FT_NA "Front park assist not available - blinded sensor; True = [1]";
CM_ SG_ 826 PTS_FT_SRV "Front PTS sensor service request; True = [1]";
CM_ SG_ 826 PTS_GraphicFC "PTS graphic flash rate front center";
CM_ SG_ 826 PTS_GraphicFL "PTS graphic flash rate front left";
CM_ SG_ 826 PTS_GraphicFR "PTS graphic flash rate front right";
CM_ SG_ 832 VehSpd_MPH "Vehicle speed signal is in miles per hour format";
CM_ SG_ 832 VehSpdDisp "Vehicle speed - displayed";
CM_ SG_ 832 xtended_AvgFuelLvl "Epanded average filtered fuel level in liters";
CM_ SG_ 838 AS_RF_CHIME_RQ "AS right front chime on request; True = [1]";
CM_ SG_ 838 AS_LF_CHIME_RQ "AS left front chime on request; True = [1]";
CM_ SG_ 838 AS_CHIME_TYPE "AS chime type";
CM_ SG_ 838 AS_CHIME_REP_RATE "AS chime repetition rate";
CM_ SG_ 840 FailSafeError "Fail safe error";
CM_ SG_ 848 DateTmSec "Time of day: SECONDS";
CM_ SG_ 848 DateTmMinute "Time of day: MINUTES";
CM_ SG_ 848 DateTmHour "Time of day: HOURS";
CM_ SG_ 848 DateTmYear "Date year";
CM_ SG_ 848 DateTmMonth "Month";
CM_ SG_ 848 DateTmDay "Day";
CM_ SG_ 848 DateTmFormat "Date and Time Format";
CM_ SG_ 850 ECM_APPL2 "Application";
CM_ SG_ 853 RrAxleLckr_Rq "Rear axle locker request";
CM_ SG_ 853 TCASE_NEUT_RQ "Transfer case neutral request";
CM_ SG_ 853 TcaseSwTyp "Transfer case LIN switch type";
CM_ SG_ 853 TcaseAWD_Rq "Transfer case all wheel drive request";
CM_ SG_ 853 Tcase4Low_Rq "Transfer case 4 wheel low request";
CM_ SG_ 853 Tcase4Lock_Rq "Transfer case 4 wheel lock request";
CM_ SG_ 853 Tcase2WD_Rq "Transfer case 2 wheel drive request";
CM_ SG_ 853 PARK_ASST_RQ "Park Assist Request";
CM_ SG_ 853 FT_PARK_ASST_RQ "Front park assist request";
CM_ SG_ 853 CLS_UnlkSw_Psd_P "Central locking system unlock switch pressed - passenger side";
CM_ SG_ 853 CLS_UnlkSw_Psd_D "Central locking system unlock switch pressed - driver side";
CM_ SG_ 853 CLS_LkSw_Psd_P "Central locking system lock switch pressed - passenger side";
CM_ SG_ 853 CLS_LkSw_Psd_D "Central locking system lock switch pressed - driver side";
CM_ SG_ 853 ASBM_AUX6_On "Aux Switch 6 Status ON;ON=1";
CM_ SG_ 856 CMP_DIR "Compass direction (WK/LX)";
CM_ SG_ 856 VAR_VAL "RCM Variance Value";
CM_ SG_ 856 CMP_DIR_RAW "Compass direction raw";
CM_ SG_ 856 IN_CAL_MD "In Calibration Mode";
CM_ SG_ 860 DIST_TO_TURN "Numeric distance to next turn";
CM_ SG_ 860 UNITS "Unit of measure";
CM_ SG_ 860 T_BY_T_ON "Turn by turn on";
CM_ SG_ 860 TURN_COMP "Turn complete";
CM_ SG_ 860 NAV_ARROW "Navigation arrow type";
CM_ SG_ 860 NAVPrsnt "A navigation system module is present";
CM_ SG_ 863 RevOilLifeRst "Engine revolutions since last oil life reset";
CM_ SG_ 864 ECM_APPL1 "Application";
CM_ SG_ 872 TCM_HSA "Manual control at test bench";
CM_ SG_ 880 ECM_APPL3 "CCP synchronous - TDC event DAQ";
CM_ SG_ 882 TorqueUnit "Torque units; Foot Pounds (ft-lb) = [1]";
CM_ SG_ 882 LANG_C "Language preference (5 bit)";
CM_ SG_ 882 PowerUnit "Power units";
CM_ SG_ 882 PressureUnit "Pressure units";
CM_ SG_ 882 CapacityUnit "Fuel capacity units";
CM_ SG_ 882 DistanceUnit "Distance (odometer) units; Miles = [1]";
CM_ SG_ 882 SpeedUnit "Speed (speedometer) units; Miles = [1]";
CM_ SG_ 882 TemperatureUnit "Temperature units; Farenheit = [1]";
CM_ SG_ 882 ConsumptionUnit "Fuel consumption units";
CM_ SG_ 882 UNIT_SET_CSO "Unit set status enable/disable";
CM_ SG_ 888 TCM_HSB "Manual control at test bench";
CM_ SG_ 896 ECM_APPL4 "CCP 5ms DAQ  (from ENGINE to external tool)";
CM_ SG_ 897 VC_VehCfg7_Stat "Configuration messages status 7";
CM_ SG_ 897 VC_LDW "Lane Departure Warning present; present = [1]";
CM_ SG_ 897 VC_TrnsDrvMdPrsnt "Transmission drive mode feature; present = [1]";
CM_ SG_ 897 VC_PdlsMdPrsnt "Paddles lock-out feature; present = [1]";
CM_ SG_ 897 VC_DST_Present "Dynamic steering torque present; True = [1]";
CM_ SG_ 897 VC_STP_PRSNT "Super trac pack present; True = [1]";
CM_ SG_ 897 VC_eShifter_Prsnt "e-shifter present; present = [1]";
CM_ SG_ 897 VC_TransType "Automatic transmission type";
CM_ SG_ 897 VC_AS_ERS "Shift feature autostick / electronic range select status";
CM_ SG_ 897 VC_FullSpeedRange_FCW "Full speed range forward collision warning plus system present; Present = 1";
CM_ SG_ 897 VC_ACC_Type "Type of adaptive cruise control (ACC) system present";
CM_ SG_ 897 VC_SuspPrsnt "NetCfg_ASCM contains suspension; present = [1]";
CM_ SG_ 897 VC_DampingPrsnt "NetCfg_ASCM contains active damping; present = [1]";
CM_ SG_ 897 VC_AxleLockerPrsnt "Axle locker configuration";
CM_ SG_ 897 VC_PBTyp "Park brake type";
CM_ SG_ 897 VC_RedKey "RedKey feature is present; Present = [1]";
CM_ SG_ 897 VC_TeenKey "TeenKey feature is present; Present = [1]";
CM_ SG_ 897 VC_TPMS_Configuration "TPMS configuration";
CM_ SG_ 897 VC_Trans_Equipped "Transmission equipped: 0 = Automatic & 1 = Manual";
CM_ SG_ 897 VC_TSBM_Prsnt "TSBM LIN slave is present; True = [1]";
CM_ SG_ 897 VC_SVC_Prsnt "Surround view camera; present = [1]";
CM_ SG_ 897 VC_Trans_N_Hold_Prsnt "Transmission neutral hold feature; present = [1]";
CM_ SG_ 897 VC_ABSM "Active Blind Spot present; present = [1]";
CM_ SG_ 897 VC_HybridType "Identify the kind of hybrid vehicle";
CM_ SG_ 897 VC_SUNR_Prsnt "Sunroof is present; True = 1";
CM_ SG_ 897 VC_Temp_Display_Resolution "Toggle between 0.5degC and 1degC temperature display";
CM_ SG_ 897 VC_Suspension_Type "Suspension type";
CM_ SG_ 897 VC_SmartAlternator "Smart alternator is present; True = [1]";
CM_ SG_ 897 VC_PTCPrsnt "PTC Present/Absent;  Present = 1";
CM_ SG_ 897 VC_MOC_Type "Motor on caliper type";
CM_ SG_ 897 VC_Glovebox "Glovebox control; Present = 1";
CM_ SG_ 897 VC_Brake_Type "Brake type";
CM_ SG_ 897 VC_AGSprsnt "AGS Present/Absent;  Present = 1";
CM_ SG_ 897 VC_ADR_PRSNT "ADR feature present; True = [1]";
CM_ SG_ 897 VC_GlareFree_Prsnt "Glare Free Present";
CM_ SG_ 897 VC_Vehicle_Package "Vehicle Package Content";
CM_ SG_ 897 VC_TrafficSignInfo "Traffic Sign Information Feature";
CM_ SG_ 897 VC_PAD_Lamp_Ctrl "ECU Controlling PAD Lamp";
CM_ SG_ 897 VC_LDW_Audio "LDW without Haptic Feedback feature";
CM_ SG_ 897 VC_LaneCentering "Lane Centering / HAS feature";
CM_ SG_ 898 VC_BU_VehCfg7_Stat "Backup for Configuration messages status 7";
CM_ SG_ 898 VC_BU_LDW "Lane departure warning present; present = [1]";
CM_ SG_ 898 VC_BU_TrnsDrvMdPrsnt "Backup for transmission drive mode feature; present = [1]";
CM_ SG_ 898 VC_BU_PdlsMdPrsnt "Backup for paddles lock-out feature; present = [1]";
CM_ SG_ 898 VC_BU_DST_Present "Backup for dynamic steering torque present; True = [1]";
CM_ SG_ 898 VC_BU_STP_PRSNT "Backup for super trac pack present; True = [1]";
CM_ SG_ 898 VC_BU_eShifter_Prsnt "Backup for e-shifter present; present = [1]";
CM_ SG_ 898 VC_BU_TransType "Backup for automatic transmission type";
CM_ SG_ 898 VC_BU_AS_ERS "Backup for shift feature autostick / electronic range select status";
CM_ SG_ 898 VC_BU_FullSpeedRange_FCW "Backup for full speed range forward collision warning plus system present; Present = 1";
CM_ SG_ 898 VC_BU_ACC_Type "Backup for type of adaptive cruise control (ACC) system present";
CM_ SG_ 898 VC_BU_SuspPrsnt "backup for ASCM contains suspension; present = [1]";
CM_ SG_ 898 VC_BU_DampingPrsnt "Backup for ASCM contains active damping; present = [1]";
CM_ SG_ 898 VC_BU_AxleLockerPrsnt "Backup for axle locker configuration";
CM_ SG_ 898 VC_BU_PBTyp "Backup for park brake type";
CM_ SG_ 898 VC_BU_RedKey "Backup for RedKey feature is present; Present = [1]";
CM_ SG_ 898 VC_BU_TeenKey "Backup for teenKey feature is present; Present = [1]";
CM_ SG_ 898 VC_BU_TPMS_Configuration "Backup for TPMS configuration";
CM_ SG_ 898 VC_BU_Trans_Equipped "Backup for Transmission equipped: 0 = Automatic & 1 = Manual";
CM_ SG_ 898 VC_BU_TSBM_Prsnt "Backup for TSBM LIN slave is present; True = [1]";
CM_ SG_ 898 VC_BU_SVC_Prsnt "Backup for surround view camera; present = [1]";
CM_ SG_ 898 VC_BU_Trans_N_Hold_Prsnt "Backup for Transmission neutral hold feature; present = [1]";
CM_ SG_ 898 VC_BU_ABSM "Backup for Active Blind Spot present; present = [1]";
CM_ SG_ 898 VC_BU_HybridType "Backup for identify the kind of hybrid vehicle";
CM_ SG_ 898 VC_BU_SUNR_Prsnt "Backup for sunroof is present; True = 1";
CM_ SG_ 898 VC_BU_Temp_Display_Resolution "Backup for toggle between 0.5degC and 1degC temperature display";
CM_ SG_ 898 VC_BU_Suspension_Type "Backup for suspension type";
CM_ SG_ 898 VC_BU_SmartAlternator "Backup for smart alternator is present; True = [1]";
CM_ SG_ 898 VC_BU_PTCPrsnt "Backup for PTC present/absent config signal;  Present = 1";
CM_ SG_ 898 VC_BU_MOC_Type "Backup for motor on caliper type";
CM_ SG_ 898 VC_BU_Glovebox "Backup for Glovebox control; Present = 1";
CM_ SG_ 898 VC_BU_Brake_Type "Backup for brake type";
CM_ SG_ 898 VC_BU_AGSprsnt "Backup for AGS present/absent config signal;  Present = 1";
CM_ SG_ 898 VC_BU_ADR_PRSNT "Backup for ADR feature present; True = [1]";
CM_ SG_ 898 VC_BU_Vehicle_Package "Vehicle Package Content";
CM_ SG_ 898 VC_BU_TrafficSignInfo "Backup for Traffic Sign Information Feature";
CM_ SG_ 898 VC_BU_PAD_Lamp_Ctrl "ECU Controlling PAD Lamp";
CM_ SG_ 898 VC_BU_GlareFree_Prsnt "Glare Free Present";
CM_ SG_ 898 VC_BU_LDW_Audio "LDW without Haptic Feedback feature";
CM_ SG_ 898 VC_BU_LaneCentering "Lane Centering / HAS feature";
CM_ SG_ 904 TCM_HSC "Manual control at test bench";
CM_ SG_ 912 ECM_APPL5 "CCP 10ms DAQ  (from ENGINE to external tool)";
CM_ SG_ 920 TCM_HSD "Manual control at test bench";
CM_ SG_ 928 ECM_APPL6 "CCP 80ms DAQ  (from ENGINE to external tool)";
CM_ SG_ 936 ECM_APPL7 "Application";
CM_ SG_ 937 SOUND_LK "Sound horn on lock; no = [0], yes = [1]";
CM_ SG_ 937 FLASH_LK "Flash lamps with lock; no = [0], yes = [1]";
CM_ SG_ 937 HL_WPR "Headlamp on with wiper; no = [0], yes =[1]";
CM_ SG_ 937 CFG_AUTO_WPR "Auto wiper configuration; no = [0], yes =[1]";
CM_ SG_ 937 ILL_APRCH_TIME "Illuminated approach time";
CM_ SG_ 937 HL_DLY_TIME "Headlamp delay time";
CM_ SG_ 937 ACC_DLY_TIME "Power accessory delay time";
CM_ SG_ 937 DRL_ON "Daytime running lamps on; enabled = [1]";
CM_ SG_ 937 SOUND_RS "Sound horn on Remote Start ; no = [0], yes = [1]";
CM_ SG_ 937 SOUND_LK_1ST_2ND "Sound horn on lock status";
CM_ SG_ 937 AUTO_LK "Auto lock; enabled = [1]";
CM_ SG_ 937 AUTO_UNLK "Auto unlock; enabled = [1]";
CM_ SG_ 937 RKE_ONE_PRESS_ENBL "Unlck all doors on 1st press; yes = [0], no = [1]";
CM_ SG_ 937 R_G_LGT_STS "Rear Guidance Lights status information, Enable= 1";
CM_ SG_ 937 Backup_Alarm "Backup Alarm; enabled = [1]";
CM_ SG_ 944 TCM_APPL2 "CCP to transmission";
CM_ SG_ 945 TCM_APPL1 "CCP from transmission";
CM_ SG_ 946 TCM_APPL3 "CCP from transmission";
CM_ SG_ 947 VC_VehCfgCSO1_Stat "Configuration message CSO1 status";
CM_ SG_ 947 VC_PRK_AST_CSO "Park assist customer settings menu";
CM_ SG_ 947 VC_PRK_AST_BRK_CSO "Park assist brake customer settings menu; Present = [1]";
CM_ SG_ 947 VC_PRK_FT_VOL_CSO "Park assist front volume customer settings menu; Present = [1]";
CM_ SG_ 947 VC_PRK_RR_VOL_CSO "Park assist rear volume customer settings menu; Present = [1]";
CM_ SG_ 947 VC_EPS_CSO "Electric power steering customer settings menu; Present = [1]";
CM_ SG_ 947 VC_FCW_CSO "Forward collision warning customer settings menu";
CM_ SG_ 947 VC_FCW_BRK_CSO "Forward collision mitigation braking customer settings menu; Present = [1]";
CM_ SG_ 947 VC_HRN_RMT_LK_CSO "Sound horn with remote lock customer settings menu";
CM_ SG_ 947 VC_HRN_RMT_ST_CSO "Sound horn with remote start customer settings menu; Present = [1]";
CM_ SG_ 947 VC_HRN_RMT_LWR_CSO "Sound horn with remote lower customer settings menu; Present = [1]";
CM_ SG_ 947 VC_CHMSL_LINE_CSO "CHMSL line menu; Present = [1]";
CM_ SG_ 947 VC_DCS_CSO "Auto on driver comfort customer settings menu";
CM_ SG_ 947 VC_AUX_SWS_CSO "Auxiliary switches customer settings menu";
CM_ SG_ 947 VC_CMRA_GRDLNS_CSO "Rear view camera gridlines customer settings menu";
CM_ SG_ 947 VC_ACC_DLY_CSO "Power accessory delay customer settings menu; Present = [1]";
CM_ SG_ 947 VC_AFLS_CSO "Adaptive front light system customer settings menu; Present = [1]";
CM_ SG_ 947 VC_AMB_DMR_CSO "Ambient dimmer customer settings menu; Present = [1]";
CM_ SG_ 947 VC_ASCM_TJ_CSO "Tire jack mode customer settings menu; Present = [1]";
CM_ SG_ 947 VC_ASCM_WRN_CSO "Air suspension warning customer settings menu; Present = [1]";
CM_ SG_ 947 VC_AUTO_AERO_CSO "Automatic aero mode customer settings menu; Present = [1]";
CM_ SG_ 947 VC_AUTO_HB_CSO "Auto high beam customer settings menu; Present = [1]";
CM_ SG_ 947 VC_AUTO_PRK_CSO "Auto park customer settings menu; Present = [1]";
CM_ SG_ 947 VC_BLIND_SPOT_CSO "Blind spot alert customer settings menu; Present = [1]";
CM_ SG_ 947 VC_CAPACITY_CSO "Capacity unit customer settings menu; Present = [1]";
CM_ SG_ 947 VC_CLK_DSP_CSO "Clock display customer settings menu; Present = [1]";
CM_ SG_ 947 VC_CMP_CAL_CSO "Compass calibration customer settings menu; Present = [1]";
CM_ SG_ 947 VC_CMP_VAR_CSO "Compass variance customer settings menu; Present = [1]";
CM_ SG_ 947 VC_CONS_CSO "Consumption unit customer settings menu; Present = [1]";
CM_ SG_ 947 VC_DISTANCE_CSO "Distance unit customer settings menu; Present = [1]";
CM_ SG_ 947 VC_DR_LK_CSO "Auto door lock customer settings menu; Present = [1]";
CM_ SG_ 947 VC_DR_UNLK_CSO "Auto door unlock customer settings menu; Present = [1]";
CM_ SG_ 947 VC_DRL_CSO "Daytime running lights customer settings menu; Present = [1]";
CM_ SG_ 947 VC_EASY_EXIT_CSO "Easy exit seat customer settings menu; Present = [1]";
CM_ SG_ 947 VC_ENTRY_EXIT_CSO "Auto entry exit mode customer settings menu; Present = [1]";
CM_ SG_ 947 VC_EPB_SERV_CSO "EPB service mode customer settings menu; Present = [1]";
CM_ SG_ 947 VC_FLSH_LMP_LK_CSO "Flash lamps with lock customer settings menu; Present = [1]";
CM_ SG_ 947 VC_HL_DRP_CSO "Headlamp drop customer settings menu; Present = [1]";
CM_ SG_ 947 VC_HL_OFF_DLY_CSO "Headlamp off delay customer settings menu; Present = [1]";
CM_ SG_ 947 VC_HL_WPR_CSO "Headlamps on with wiper customer settings menu; Present = [1]";
CM_ SG_ 947 VC_HSA_CSO "Hill start assist customer settings menu; Present = [1]";
CM_ SG_ 947 VC_ILL_APPRCH_CSO "Illuminated approach customer settings menu; Present = [1]";
CM_ SG_ 947 VC_LDW_TRQ_CSO "Lane departure torque customer settings menu; Present = [1]";
CM_ SG_ 947 VC_LDW_WRN_CSO "Lane departure warning customer settings menu; Present = [1]";
CM_ SG_ 947 VC_LGHT_RMT_LWR_CSO "Flash lights with remote lower customer settings menu; Present = [1]";
CM_ SG_ 947 VC_NAV_TRN_CSO "Nav turn by turn customer settings menu; Present = [1]";
CM_ SG_ 947 VC_PE_CSO "Passive entry customer settings menu; Present = [1]";
CM_ SG_ 947 VC_PER_SHFT_ENBL_CSO "Performance shift enable customer settings menu; Present = [1]";
CM_ SG_ 947 VC_PER_SHFT_RPM_CSO "Performance shift rpm customer settings menu; Present = [1]";
CM_ SG_ 947 VC_PLG_CHM_CSO "Power liftgate chime customer settings menu; Present = [1]";
CM_ SG_ 947 VC_POWER_CSO "Power unit customer settings menu; Present = [1]";
CM_ SG_ 947 VC_PRESSURE_CSO "Pressure unit customer settings menu; Present = [1]";
CM_ SG_ 947 VC_PTO_CSO "Power take off customer settings menu; Present = [1]";
CM_ SG_ 947 VC_RAIN_WPR_CSO "Rain sensitive wipers customer settings menu; Present = [1]";
CM_ SG_ 947 VC_REAR_CMRA_CSO "Rear camera customer settings menu; Present = [1]";
CM_ SG_ 947 VC_POLICE_PE_CSO "Police passive entry settings menu; Present = [1]";
CM_ SG_ 947 VC_UNIT_SET_CSO "Unit set customer settings menu; Present = [1]";
CM_ SG_ 948 VC_VehCfgCSO2_Stat "Configuration message CSO2 status";
CM_ SG_ 948 VC_REAR_CMRA_DLY_CSO "Rear view camera delay customer settings menu; Present = [1]";
CM_ SG_ 948 VC_RKE_MEM_CSO "RKE linked to memory customer settings menu; Present = [1]";
CM_ SG_ 948 VC_RKE_UNLK_CSO "RKE unlock customer settings menu; Present = [1]";
CM_ SG_ 948 VC_SPEED_CSO "Speed unit customer settings menu; Present = [1]";
CM_ SG_ 948 VC_TLT_MRR_CSO "Tilt mirror in reverse customer settings menu; Present = [1]";
CM_ SG_ 948 VC_TORQUE_CSO "Torque unit customer settings menu; Present = [1]";
CM_ SG_ 948 VC_TRLR_CSO "Trailer selected customer settings menu; Present = [1]";
CM_ SG_ 948 VC_TRLR_NAME_CSO "Trailer name customer settings menu; Present = [1]";
CM_ SG_ 948 VC_TRLR_TYPE_CSO "Trailer type customer settings menu; Present = [1]";
CM_ SG_ 948 VC_TRNS_MD_CSO "Transport mode customer settings menu; Present = [1]";
CM_ SG_ 948 VC_US_METRIC_CSO "US metric customer settings menu; Present = [1]";
CM_ SG_ 948 VC_WHL_ALGN_CSO "Wheel alignment customer settings menu; Present = [1]";
CM_ SG_ 948 VC_FUEL_SAV_CSO "Fuel Saver settings menu; Present = [1]";
CM_ SG_ 948 VC_TEMP_CSO "Temperature Unit settings menu; Present = [1]";
CM_ SG_ 948 VC_FCW_SW_CSO "FCW Switch customer setting menu present.  Present = 1";
CM_ SG_ 948 VC_PADDLE_SHIFT_CSO "Paddle shifter customer setting menu present.  Present = [1]";
CM_ SG_ 948 VC_PWR_FLD_MRR_CSO "Power folding mirror customer setting menu: Present = 1";
CM_ SG_ 948 VC_TEEN_FCW_BRK_CSO "Teen key FCW braking customer setting menu: Present = 1";
CM_ SG_ 948 VC_TEEN_FCW_SENS_CSO "Teen key FCW sensitivity customer setting menu: Present = 1";
CM_ SG_ 948 VC_TEEN_MAX_SPEED_CSO "Teen key max speed customer setting menu: Present = 1";
CM_ SG_ 948 VC_HOLD_N_GO_CSO "Hold and go customer setting menu: Present = 1";
CM_ SG_ 948 VC_HANDS_FREE_LFT_CSO "Hands free liftgate customer setting menu: Present = 1";
CM_ SG_ 948 VC_HANDS_FREE_SLDR_CSO "Hands free sliding door customer setting menu: Present = 1";
CM_ SG_ 948 VC_SVC_GRIDLINES_CSO "Surround view camera gridlines customer setting menu: Present = 1";
CM_ SG_ 948 VC_SVC_DELAY_CSO "Surround view camera delay customer setting menu: Present = 1";
CM_ SG_ 948 VC_SLD_DR_ALRT_CSO "Sliding door alert customer setting menu: Present = 1";
CM_ SG_ 948 VC_TEEN_PRK_ASST_CSO "Teen key park assist customer setting menu: Present = 1";
CM_ SG_ 948 VC_TEEN_FT_PRK_VOL_CSO "Teen key front park assist chime volume customer setting menu: Present = 1";
CM_ SG_ 948 VC_TEEN_RR_PRK_VOL_CSO "Teen key rear park assist chime volume customer setting menu: Present = 1";
CM_ SG_ 948 VC_TEEN_FUEL_WRN_CSO "Teen key early fuel warning customer setting menu: Present = 1";
CM_ SG_ 948 VC_TEEN_FUEL_POPUP_CSO "Teen key fuel pop-up customer setting menu: Present = 1";
CM_ SG_ 948 VC_TEEN_BLIND_SPOT_CSO "Teen key blind spot customer setting menu: Present = 1";
CM_ SG_ 948 VC_TEEN_RAIN_WPR_CSO "Teen key rain sensitive wiper customer setting menu: Present = 1";
CM_ SG_ 948 VC_TEEN_AUTO_HB_CSO "Teen key automatic highbeam customer setting menu: Present = 1";
CM_ SG_ 948 VC_TEEN_LGHT_WPR_CSO "Teen key lights on with wipers customer setting menu: Present = 1";
CM_ SG_ 948 VC_TEEN_SLD_DR_ALRT_CSO "Teen key sliding door alert customer setting menu: Present = 1";
CM_ SG_ 948 VC_TEEN_PLG_CHIME_CSO "Teen key power lift gate chime customer setting menu: Present = 1";
CM_ SG_ 948 VC_SLD_DR_CHM_CSO "Sliding door chime customer setting menu present: Present = 1";
CM_ SG_ 948 VC_TEEN_SLD_DR_CHM_CSO "Teen key sliding door chime customer setting menu present: Present = 1";
CM_ SG_ 948 VC_FLSH_LMP_SLDR_CSO "Flash lamps with sliding door customer settings menu; Present = [1]";
CM_ SG_ 948 VC_SPEED_WARNING_CSO "Speed warning  customer setting";
CM_ SG_ 948 VC_LDW_ON_CSO "LDW on/off customer setting menu present.  Present = 1.";
CM_ SG_ 948 VC_PRK_ASST_TYPE_CSO "Park assist type customer setting menu present. Present = 1.";
CM_ SG_ 948 VC_EPB_ON_CSO "EPB on/off customer setting menu present. Present = 1.";
CM_ SG_ 948 VC_AIRBAG_ON_CSO "Passenger airbag on/off customer setting menu present. Present = 1.";
CM_ SG_ 948 VC_RDY_DRV_CSO "Disable ready to drive popup customer settings menu. Present = 1";
CM_ SG_ 948 VC_TEEN_PRK_ASST_BRK_CSO "Teen key park assist brake customer settings menu.  Present = 1";
CM_ SG_ 948 VC_PCS_CSO "Auto on passenger comfort customer settings menu. Present = 1";
CM_ SG_ 948 VC_FCW_WARN_BRK_CSO "FCW single setting (warning and brake) customer setting menu.  Present = 1";
CM_ SG_ 948 VC_DOORS_OFF_ACC_DLY_CSO "Doors & engine off power delay customer settings menu backup. Present = 1";
CM_ SG_ 948 VC_BSM_TRLR_CSO "Blind spot with trailer customer settings menu. Present = 1";
CM_ SG_ 948 VC_AUTO_SS_CSO "Automatic side step customer settings menu. Present = 1";
CM_ SG_ 948 VC_MOTORIZED_SEATBELT_STRN_CSO "Motorized Seatbelt Strength customer settings menu";
CM_ SG_ 948 VC_MOTORIZED_SEATBELT_CSO "Motorized Seatbelt Enable/Disable customer settings menu";
CM_ SG_ 948 VC_LKA_CSO "Lane Keep Assist Enable/Disable customer settings menu";
CM_ SG_ 948 VC_BLIND_SPOT_WARNING_CSO "Blind Spot Warning Mode customer settings menu";
CM_ SG_ 948 VC_ABSD_WARNING_CSO "Active Blind Spot Warning Mode customer settings menu";
CM_ SG_ 948 VC_ABSD_STRN_CSO "Active Blind Spot Strength customer settings menu";
CM_ SG_ 948 VC_ABSD_SENS_CSO "Active Blind Spot Sensitivity customer settings menu";
CM_ SG_ 948 VC_ABSD_HAPTIC_CSO "Active Blind Spot Haptic customer settings menu";
CM_ SG_ 948 VC_ABSD_CSO "Active Blind Spot Enable/Disable customer settings menu";
CM_ SG_ 949 VC_BU_VehCfgCSO1_Stat "Backup for Configuration message CSO1 status";
CM_ SG_ 949 VC_BU_PRK_AST_CSO "Backup for park assist customer settings menu";
CM_ SG_ 949 VC_BU_PRK_AST_BRK_CSO "Backup for park assist brake customer settings menu";
CM_ SG_ 949 VC_BU_PRK_FT_VOL_CSO "Backup for park assist front volume customer settings menu";
CM_ SG_ 949 VC_BU_PRK_RR_VOL_CSO "Backup for park assist rear volume customer settings menu";
CM_ SG_ 949 VC_BU_EPS_CSO "Backup for electric power steering customer settings menu";
CM_ SG_ 949 VC_BU_FCW_CSO "Backup for Forward collision warning customer settings menu";
CM_ SG_ 949 VC_BU_FCW_BRK_CSO "Backup for Forward collision mitigation braking customer settings menu";
CM_ SG_ 949 VC_BU_HRN_RMT_LK_CSO "Backup for Sound horn with remote lock customer settings menu";
CM_ SG_ 949 VC_BU_HRN_RMT_ST_CSO "Backup for Sound horn with remote start customer settings menu";
CM_ SG_ 949 VC_BU_HRN_RMT_LWR_CSO "Backup for Sound horn with remote lower customer settings menu";
CM_ SG_ 949 VC_BU_CHMSL_LINE_CSO "Backup for CHMSL line customer settings menu";
CM_ SG_ 949 VC_BU_DCS_CSO "Backup for Auto on driver comfort customer settings menu";
CM_ SG_ 949 VC_BU_AUX_SWS_CSO "Backup for Auxiliary switches customer settings menu";
CM_ SG_ 949 VC_BU_CMRA_GRDLNS_CSO "Backup for Rear view camera gridlines customer settings menu";
CM_ SG_ 949 VC_BU_ACC_DLY_CSO "Backup for Power accessory delay customer settings menu";
CM_ SG_ 949 VC_BU_AFLS_CSO "Backup for Adaptive front light system customer settings menu";
CM_ SG_ 949 VC_BU_AMB_DMR_CSO "Backup for Ambient dimmer customer settings menu";
CM_ SG_ 949 VC_BU_ASCM_TJ_CSO "Backup for Tire jack mode customer settings menu";
CM_ SG_ 949 VC_BU_ASCM_WRN_CSO "Backup for Air suspension warning customer settings menu";
CM_ SG_ 949 VC_BU_AUTO_AERO_CSO "Backup for Automatic aero mode customer settings menu";
CM_ SG_ 949 VC_BU_AUTO_HB_CSO "Backup for Auto high beam customer settings menu";
CM_ SG_ 949 VC_BU_AUTO_PRK_CSO "Backup for Auto park customer settings menu";
CM_ SG_ 949 VC_BU_BLIND_SPOT_CSO "Backup for Blind spot alert customer settings menu";
CM_ SG_ 949 VC_BU_CAPACITY_CSO "Backup for Capacity unit customer settings menu";
CM_ SG_ 949 VC_BU_CLK_DSP_CSO "Backup for Clock display customer settings menu";
CM_ SG_ 949 VC_BU_CMP_CAL_CSO "Backup for Compass calibration customer settings menu";
CM_ SG_ 949 VC_BU_CMP_VAR_CSO "Backup for Compass variance customer settings menu";
CM_ SG_ 949 VC_BU_CONS_CSO "Backup for Consumption unit customer settings menu";
CM_ SG_ 949 VC_BU_DISTANCE_CSO "Backup for Distance unit customer settings menu";
CM_ SG_ 949 VC_BU_DR_LK_CSO "Backup for Auto door lock customer settings menu";
CM_ SG_ 949 VC_BU_DR_UNLK_CSO "Backup for Auto door unlock customer settings menu";
CM_ SG_ 949 VC_BU_DRL_CSO "Backup for Daytime running lights customer settings menu";
CM_ SG_ 949 VC_BU_EASY_EXIT_CSO "Backup for Easy exit seat customer settings menu";
CM_ SG_ 949 VC_BU_ENTRY_EXIT_CSO "Backup for Auto entry exit mode customer settings menu";
CM_ SG_ 949 VC_BU_EPB_SERV_CSO "Backup for EPB service mode customer settings menu";
CM_ SG_ 949 VC_BU_FLSH_LMP_LK_CSO "Backup for Flash lamps with lock customer settings menu";
CM_ SG_ 949 VC_BU_HL_DRP_CSO "Backup for Headlamp drop customer settings menu";
CM_ SG_ 949 VC_BU_HL_OFF_DLY_CSO "Backup for Headlamp off delay customer settings menu";
CM_ SG_ 949 VC_BU_HL_WPR_CSO "Backup for Headlamps on with wiper customer settings menu";
CM_ SG_ 949 VC_BU_HSA_CSO "Backup for Hill start assist customer settings menu";
CM_ SG_ 949 VC_BU_ILL_APPRCH_CSO "Backup for Illuminated approach customer settings menu";
CM_ SG_ 949 VC_BU_LDW_TRQ_CSO "Backup for Lane departure torque customer settings menu";
CM_ SG_ 949 VC_BU_LDW_WRN_CSO "Backup for Lane departure warning customer settings menu";
CM_ SG_ 949 VC_BU_LGHT_RMT_LWR_CSO "Backup for Flash lights with remote lower customer settings menu";
CM_ SG_ 949 VC_BU_NAV_TRN_CSO "Backup for Nav turn by turn customer settings menu";
CM_ SG_ 949 VC_BU_PE_CSO "Backup for Passive entry customer settings menu";
CM_ SG_ 949 VC_BU_PER_SHFT_ENBL_CSO "Backup for Performance shift enable customer settings menu";
CM_ SG_ 949 VC_BU_PER_SHFT_RPM_CSO "Backup for Performance shift rpm customer settings menu";
CM_ SG_ 949 VC_BU_PLG_CHM_CSO "Backup for Power liftgate chime customer settings menu";
CM_ SG_ 949 VC_BU_POWER_CSO "Backup for Power unit customer settings menu";
CM_ SG_ 949 VC_BU_PRESSURE_CSO "Backup for Pressure unit customer settings menu";
CM_ SG_ 949 VC_BU_PTO_CSO "Backup for Power take off customer settings menu";
CM_ SG_ 949 VC_BU_RAIN_WPR_CSO "Backup for Rain sensitive wipers customer settings menu";
CM_ SG_ 949 VC_BU_REAR_CMRA_CSO "Backup for Rear camera customer settings menu";
CM_ SG_ 949 VC_BU_POLICE_PE_CSO "Backup for police passive entry settings menu; Present = [1]";
CM_ SG_ 949 VC_BU_UNIT_SET_CSO "Backup for unit set customer settings menu; Present = [1]";
CM_ SG_ 950 VC_BU_VehCfgCSO2_Stat "Backup for Configuration message CSO2 status";
CM_ SG_ 950 VC_BU_REAR_CMRA_DLY_CSO "Backup for Rear view camera delay customer settings menu";
CM_ SG_ 950 VC_BU_RKE_MEM_CSO "Backup for RKE linked to memory customer settings menu";
CM_ SG_ 950 VC_BU_RKE_UNLK_CSO "Backup for RKE unlock customer settings menu";
CM_ SG_ 950 VC_BU_SPEED_CSO "Backup for Speed unit customer settings menu";
CM_ SG_ 950 VC_BU_TLT_MRR_CSO "Backup for Tilt mirror in reverse customer settings menu";
CM_ SG_ 950 VC_BU_TORQUE_CSO "Backup for Torque unit customer settings menu";
CM_ SG_ 950 VC_BU_TRLR_CSO "Backup for Trailer selected customer settings menu";
CM_ SG_ 950 VC_BU_TRLR_NAME_CSO "Backup for Trailer name customer settings menu";
CM_ SG_ 950 VC_BU_TRLR_TYPE_CSO "Backup for Trailer type customer settings menu";
CM_ SG_ 950 VC_BU_TRNS_MD_CSO "Backup for Transport mode customer settings menu";
CM_ SG_ 950 VC_BU_US_METRIC_CSO "Backup for US metric customer settings menu";
CM_ SG_ 950 VC_BU_WHL_ALGN_CSO "Backup for Wheel alignment customer settings menu";
CM_ SG_ 950 VC_BU_FUEL_SAV_CSO "Backup for Fuel Saver settings menu; Present = [1]";
CM_ SG_ 950 VC_BU_TEMP_CSO "Backup for Temperature Unit settings menu; Present = [1]";
CM_ SG_ 950 VC_BU_FCW_SW_CSO "Backup for FCW Switch customer setting menu present.  Present = 1";
CM_ SG_ 950 VC_BU_PADDLE_SHIFT_CSO "Backup for paddle shifter customer setting menu present.  Present = [1]";
CM_ SG_ 950 VC_BU_PWR_FLD_MRR_CSO "Backup for Power folding mirror customer setting menu: Present = 1";
CM_ SG_ 950 VC_BU_TEEN_FCW_BRK_CSO "Backup for Teen key FCW braking customer setting menu: Present = 1";
CM_ SG_ 950 VC_BU_TEEN_FCW_SENS_CSO "Backup for Teen key FCW sensitivity customer setting menu: Present = 1";
CM_ SG_ 950 VC_BU_TEEN_MAX_SPEED_CSO "Backup for Teen key max speed customer setting menu: Present = 1";
CM_ SG_ 950 VC_BU_HOLD_N_GO_CSO "Backup for Hold and go customer setting menu: Present = 1";
CM_ SG_ 950 VC_BU_HANDS_FREE_LFT_CSO "Backup for Hands free liftgate customer setting menu: Present = 1";
CM_ SG_ 950 VC_BU_HANDS_FREE_SLDR_CSO "Backup for Hands free sliding door customer setting menu: Present = 1";
CM_ SG_ 950 VC_BU_SVC_GRIDLINES_CSO "Backup for Surround view camera gridlines customer setting menu: Present = 1";
CM_ SG_ 950 VC_BU_SVC_DELAY_CSO "Backup for Surround view camera delay customer setting menu: Present = 1";
CM_ SG_ 950 VC_BU_SLD_DR_ALRT_CSO "Backup for Sliding door alert customer setting menu: Present = 1";
CM_ SG_ 950 VC_BU_TEEN_PRK_ASST_CSO "Backup for Teen key park assist customer setting menu: Present = 1";
CM_ SG_ 950 VC_BU_TEEN_FT_PRK_VOL_CSO "Backup for Teen key front park assist chime volume customer setting menu: Present = 1";
CM_ SG_ 950 VC_BU_TEEN_RR_PRK_VOL_CSO "Backup for Teen key rear park assist chime volume customer setting menu: Present = 1";
CM_ SG_ 950 VC_BU_TEEN_FUEL_WRN_CSO "Backup for Teen key early fuel warning customer setting menu: Present = 1";
CM_ SG_ 950 VC_BU_TEEN_FUEL_POPUP_CSO "Backup for Teen key fuel pop-up customer setting menu: Present = 1";
CM_ SG_ 950 VC_BU_TEEN_BLIND_SPOT_CSO "Backup for Teen key blind spot customer setting menu: Present = 1";
CM_ SG_ 950 VC_BU_TEEN_RAIN_WPR_CSO "Backup for Teen key rain sensitive wiper customer setting menu: Present = 1";
CM_ SG_ 950 VC_BU_TEEN_AUTO_HB_CSO "Backup for Teen key automatic highbeam customer setting menu: Present = 1";
CM_ SG_ 950 VC_BU_TEEN_LGHT_WPR_CSO "Backup for Teen key lights on with wipers customer setting menu: Present = 1";
CM_ SG_ 950 VC_BU_TEEN_SLD_DR_ALRT_CSO "Backup for Teen key sliding door alert customer setting menu: Present = 1";
CM_ SG_ 950 VC_BU_TEEN_PLG_CHIME_CSO "Backup for Teen key power lift gate chime customer setting menu: Present = 1";
CM_ SG_ 950 VC_BU_SLD_DR_CHM_CSO "Backup for Sliding door chime customer setting menu present: Present = 1";
CM_ SG_ 950 VC_BU_TEEN_SLD_DR_CHM_CSO "Backup for Teen key sliding door chime customer setting menu present: Present = 1";
CM_ SG_ 950 VC_BU_FLSH_LMP_SLDR_CSO "Backup for flash lamps with sliding door customer settings menu; Present = [1]";
CM_ SG_ 950 VC_BU_SPEED_WARNING_CSO "Backup for Speed warning  customer setting";
CM_ SG_ 950 VC_BU_LDW_ON_CSO "Backup for LDW on/off customer setting menu present.  Present = 1.";
CM_ SG_ 950 VC_BU_PRK_ASST_TYPE_CSO "Backup for Park assist type customer setting menu present. Present = 1.";
CM_ SG_ 950 VC_BU_EPB_ON_CSO "Backup for EPB on/off customer setting menu present. Present = 1.";
CM_ SG_ 950 VC_BU_AIRBAG_ON_CSO "Backup for Passenger airbag on/off customer setting menu present. Present = 1.";
CM_ SG_ 950 VC_BU_RDY_DRV_CSO "Backup for disable ready to drive popup customer settings menu.  Present = 1";
CM_ SG_ 950 VC_BU_TEEN_PRK_ASST_BRK_CSO "Backup teen key park assist brake customer settings menu.  Present = 1";
CM_ SG_ 950 VC_BU_PCS_CSO "Backup for Auto on passenger comfort customer settings menu. Present = 1";
CM_ SG_ 950 VC_BU_FCW_WARN_BRK_CSO "Backup for FCW single setting (warning and brake) customer setting menu.  Present = 1";
CM_ SG_ 950 VC_BU_DOORS_OFF_ACC_DLY_CSO "Backup for Doors & engine off power delay customer settings menu backup. Present = 1";
CM_ SG_ 950 VC_BU_BSM_TRLR_CSO "Backup for Blind spot with trailer customer settings menu. Present = 1.";
CM_ SG_ 950 VC_BU_AUTO_SS_CSO "Backup for Automatic side step customer settings menu. Present = 1";
CM_ SG_ 950 VC_BU_MOTORIZED_SEATBELT_CSO "Motorized Seatbelt Enable/Disable customer settings menu";
CM_ SG_ 950 VC_BU_LKA_CSO "Lane Keep Assist Enable/Disable customer settings menu";
CM_ SG_ 950 VC_BU_BLIND_SPOT_WARNING_CSO "Blind Spot Warning Mode customer settings menu";
CM_ SG_ 950 VC_BU_ABSD_WARNING_CSO "Active Blind Spot Warning Mode customer settings menu";
CM_ SG_ 950 VC_BU_ABSD_STRN_CSO "Active Blind Spot Strength customer settings menu";
CM_ SG_ 950 VC_BU_ABSD_SENS_CSO "Active Blind Spot Warning Mode customer settings menu";
CM_ SG_ 950 VC_BU_ABSD_HAPTIC_CSO "Active Blind Spot Haptic customer settings menu";
CM_ SG_ 950 VC_BU_ABSD_CSO "Active Blind Spot Enable/Disable customer settings menu";
CM_ SG_ 950 VC_BU_MOTORIZED_SEATBELT_STRN_CS "Motorized Seatbelt Strength customer settings menu";
CM_ SG_ 956 NAV_GrpNum "NAV group number";
CM_ SG_ 956 NAV_GrpTyp "NAV group type";
CM_ SG_ 956 NAV_HiGrpMark "NAV high group mark";
CM_ SG_ 956 NAV_TEXT "NAV data field";
CM_ SG_ 969 AMB_TEMP_AVG_F "Ambient temperature average - in degrees Fahrenheit";
CM_ SG_ 969 AMB_TEMP_AVG_C "Ambient temperature average - in degrees Celsius";
CM_ SG_ 974 FT_HVAC_BLW_FN_SP "Front HVAC blower fan speed status in 'bars'";
CM_ SG_ 974 DRV_TEMP_DR_POS "Driver temperature door postion";
CM_ SG_ 977 TransTyp "Transmission type";
CM_ SG_ 979 EC_ECUCfg14_Stat "ECU Configuration messages status 14";
CM_ SG_ 979 EC_CBC14A "CBC ecu configuration 14A";
CM_ SG_ 979 EC_CBC14B "CBC ecu configuration 14B";
CM_ SG_ 980 EC_ECUCfg13_Stat "ECU Configuration messages status 13";
CM_ SG_ 980 EC_CBC13A "CBC ecu configuration 13A";
CM_ SG_ 980 EC_CBC13B "CBC ecu configuration 13B";
CM_ SG_ 981 EC_ECUCfg12_Stat "ECU Configuration messages status 12";
CM_ SG_ 981 EC_Cluster5A "Instrument cluster ecu configuration 5A";
CM_ SG_ 981 EC_Cluster5B "Instrument cluster ecu configuration 5B";
CM_ SG_ 981 EC_Cluster5C "Instrument cluster ecu configuration 5C";
CM_ SG_ 982 EC_ECUCfg11_Stat "ECU Configuration messages status 11";
CM_ SG_ 982 EC_CBC10A "CBC ecu configuration 10A";
CM_ SG_ 982 EC_CBC10B "CBC ecu configuration 10B";
CM_ SG_ 982 EC_CBC11 "CBC ecu configuration 11";
CM_ SG_ 983 EC_ECUCfg10_Stat "ECU Configuration messages status 10";
CM_ SG_ 983 EC_Cluster3A "Instrument cluster ecu configuration 3A";
CM_ SG_ 983 EC_Cluster3B "Instrument cluster ecu configuration 3B";
CM_ SG_ 983 EC_Cluster4 "Instrument cluster ecu configuration 4";
CM_ SG_ 984 EC_ECUCfg9_Stat "ECU Configuration messages status 9";
CM_ SG_ 984 EC_CBC9A1 "CBC configuration 9A1";
CM_ SG_ 984 EC_CBC9A2 "CBC configuration 9A2";
CM_ SG_ 984 EC_CBC9B "CBC configuration 9B";
CM_ SG_ 984 EC_ITM "ITM ecu configuration";
CM_ SG_ 985 EC_BU_ECUCfg14_Stat "Backup for ECU Configuration messages status 14";
CM_ SG_ 985 EC_BU_CBC14A "Backup for CBC ecu configuration 14A";
CM_ SG_ 985 EC_BU_CBC14B "Backup for CBC ecu configuration 14B";
CM_ SG_ 986 EC_BU_ECUCfg13_Stat "Backup for ECU Configuration messages status 13";
CM_ SG_ 986 EC_BU_CBC13A "Backup for CBC ecu configuration 13A";
CM_ SG_ 986 EC_BU_CBC13B "Backup for CBC ecu configuration 13B";
CM_ SG_ 987 EC_BU_ECUCfg12_Stat "Backup for ECU Configuration messages status 12";
CM_ SG_ 987 EC_BU_Cluster5A "Backup for Instrument cluster ecu configuration 5A";
CM_ SG_ 987 EC_BU_Cluster5B "Backup for Instrument cluster ecu configuration 5B";
CM_ SG_ 987 EC_BU_Cluster5C "Backup for Instrument cluster ecu configuration 5C";
CM_ SG_ 988 EC_BU_ECUCfg11_Stat "Backup for ECU Configuration messages status 11";
CM_ SG_ 988 EC_BU_CBC10A "Backup for CBC ecu configuration 10A";
CM_ SG_ 988 EC_BU_CBC10B "Backup for CBC ecu configuration 10B";
CM_ SG_ 988 EC_BU_CBC11 "Backup for CBC ecu configuration 11";
CM_ SG_ 989 EC_BU_ECUCfg10_Stat "Backup for ECU Configuration messages status 10";
CM_ SG_ 989 EC_BU_Cluster3A "Backup for Instrument cluster ecu configuration 3A";
CM_ SG_ 989 EC_BU_Cluster3B "Backup for Instrument cluster ecu configuration 3B";
CM_ SG_ 989 EC_BU_Cluster4 "Backup for Instrument cluster ecu configuration 4";
CM_ SG_ 991 EC_BU_ECUCfg9_Stat "Backup for ECU Configuration messages status 9";
CM_ SG_ 991 EC_BU_CBC9A1 "Backup for CBC configuration 9A1";
CM_ SG_ 991 EC_BU_CBC9A2 "Backup for CBC configuration 9A2";
CM_ SG_ 991 EC_BU_CBC9B "Backup for CBC configuration 9B";
CM_ SG_ 991 EC_BU_ITM "Backup for ITM ecu configuration";
CM_ SG_ 993 DISPLACEMENT "Engine displacement";
CM_ SG_ 993 NUM_CYL "Number of engine cylinders";
CM_ SG_ 993 SpStPrsnt "Stop start feature present";
CM_ SG_ 993 ENG_ASP "Engine aspiration method";
CM_ SG_ 993 FUEL_TYPE "Fuel type";
CM_ SG_ 993 ECM_Vehi_Type "Engine vehicle type";
CM_ SG_ 993 Manufacture "Engine manufacture";
CM_ SG_ 993 NUM_VALVE "Number of valves per cylinder";
CM_ SG_ 993 ETC_PRSNT "Electronic throttle control";
CM_ SG_ 993 TRANS_TYPE "Transmission type; [0] = manual, [1] = automatic";
CM_ SG_ 993 EngStyle "Engine output version";
CM_ SG_ 995 NET_CFG_STAT_INT "Network configuration status";
CM_ SG_ 995 NetCfg_RBSS "Right Blind-Spot Module (1=present)";
CM_ SG_ 995 NetCfg_BSM "Blind-Spot Module (1=present)";
CM_ SG_ 995 NetCfg_CBC_IN "Common Body Controller Int Bus (1=present)";
CM_ SG_ 995 NetCfg_CSWM "Comfot Seats and Wheel Module (1=present)";
CM_ SG_ 995 NetCfg_DCM_DR "Door Control Module Driver (1=present)";
CM_ SG_ 995 NetCfg_DCM_PASS "Door Control Module Passenger (1=present)";
CM_ SG_ 995 NetCfg_DCM_RL "Door Control Module Rear Left (1=present)";
CM_ SG_ 995 NetCfg_DCM_RR "Door Control Module Rear Right (1=present)";
CM_ SG_ 995 NetCfg_HVAC "Heating Ventilation Air Conditioning (1=present)";
CM_ SG_ 995 NetCfg_MSM "Memory Seat Module (1=present)";
CM_ SG_ 995 NetCfg_PLG "Power Liftgate Module (1=present)";
CM_ SG_ 995 NetCfg_VTM "Vehicle theft / tax module (1=present)";
CM_ SG_ 995 NetCfg_PSD_LT "Power Sliding Door Left Module (1=present)";
CM_ SG_ 995 NetCfg_PSD_RT "Power Sliding Door Right Module (1=present)";
CM_ SG_ 995 NetCfg_FSM "Folding Seat Module (1=present)";
CM_ SG_ 995 NetCfg_PTCM "Power Top Control Module (1=present)";
CM_ SG_ 995 NetCfg_RBC "Rear Body Controller Module (1=present)";
CM_ SG_ 995 NetCfg_DTV "Digital TV Module (1=present)";
CM_ SG_ 995 NetCfg_TGW "Telematics gateway (1=present)";
CM_ SG_ 995 NetCfg_CLOCK "CAN I Clock Module (1=present)";
CM_ SG_ 995 NetCfg_VSIM "Vehicle System Interface Module (1=present)";
CM_ SG_ 995 NetCfg_ITM "Intrusion module (1=present)";
CM_ SG_ 995 NetCfg_AMP_I "CAN I Amplifier Module (1=present)";
CM_ SG_ 995 NetCfg_DVD_CDM "CAN I in-dash disc player module (1=present)";
CM_ SG_ 995 NetCfg_HFM_CTM "Convergence Telematics Module (1=present)";
CM_ SG_ 995 NetCfg_ICS_I "CAN I Integrated Center Stack Module (1=present)";
CM_ SG_ 995 NetCfg_VES2_I "CAN I Video Ent. System screen 2 Module (1=present)";
CM_ SG_ 995 NetCfg_VES3_I "CAN I Video Ent. System screen 1 Module (1=present)";
CM_ SG_ 995 NetCfg_CRSM "CAN I Comfort Rear Seat Module (1=present)";
CM_ SG_ 995 NetCfg_HVAC_R "CAN I Rear Heating Ventilation Air Conditioning (1=present)";
CM_ SG_ 995 NetCfg_DCSD "Disassociated Center Stack Display Module (1=present)";
CM_ SG_ 995 NetCfg_TBM "Telematics Box Module (1=present)";
CM_ SG_ 995 NetCfg_CVPM "CAN I Central Vision Processing Module (1=present)";
CM_ SG_ 995 NetCfg_TMM "CAN I Track Mapping Module (1=present)";
CM_ SG_ 995 NetCfg_ICS_R "CAN I Integrated rear Center Stack Module (1=present)";
CM_ SG_ 995 NetCfg_MSM_PASS "CAN I Memory Seat Module Passenger (1=present)";
CM_ SG_ 995 NetCfg_VRM "Video Routing Module (1=present)";
CM_ SG_ 995 NetCfg_ANC_I "Active Noise Cancellation interior (1=present)";
CM_ SG_ 995 NetCfg_TTM "0= Not Present;  1= Present";
CM_ SG_ 995 NetCfg_UPFM "CAN I Upfitter Module (1=present)";
CM_ SG_ 995 NetCfg_PSSM "NetCfg PSSM";
CM_ SG_ 996 NET_CFG_STAT_PT "Network configuration status";
CM_ SG_ 996 NetCfg_ACC "Active Cruise Control (1=present)";
CM_ SG_ 996 NetCfg_ADCM "Active Damping Control Module (1=present)";
CM_ SG_ 996 NetCfg_AHLM "Automatic Headlamp Leveling Module (1=present)";
CM_ SG_ 996 NetCfg_VSIM_C "Vehicle System Interface Module (1=present)";
CM_ SG_ 996 NetCfg_ASCM "Air Suspension Control Module (1=present)";
CM_ SG_ 996 NetCfg_CBC_PT "Common Body Controller PT Bus (1=present)";
CM_ SG_ 996 NetCfg_DTCM "Drivetrain Control Module (1=present)";
CM_ SG_ 996 NetCfg_ECM "Engine Control Module (1=present)";
CM_ SG_ 996 NetCfg_EPS "Electric Power Steering (1=present)";
CM_ SG_ 996 NetCfg_ESM "Electronic Shift Module (1=present)";
CM_ SG_ 996 NetCfg_ESC "Electronic Stability Module / Anti-Lock Brake (1=present)";
CM_ SG_ 996 NetCfg_EPB "Electric Park Brake Module (1=present)";
CM_ SG_ 996 NetCfg_RF_HUB "RF Hub Node (1=present)";
CM_ SG_ 996 NetCfg_IC "Instrument Cluster (1=present)";
CM_ SG_ 996 NetCfg_DASM "Driver Assistance System Module (1=present)";
CM_ SG_ 996 NetCfg_FDCM "Final Drive Control Module (1=present)";
CM_ SG_ 996 NetCfg_EPPM "Elect. Pedestrian protection module (1=present)";
CM_ SG_ 996 NetCfg_ORC "Occupant Restraint Controller (1=present)";
CM_ SG_ 996 NetCfg_PTS "Parktronics System (1=present)";
CM_ SG_ 996 NetCfg_SCCM "Steering Column Control Module (1=present)";
CM_ SG_ 996 NetCfg_ELSD "Electric Limited Slip Differential (1=present)";
CM_ SG_ 996 NetCfg_TCM "Automatic Transmission Controller (1=present)";
CM_ SG_ 996 NetCfg_TPM "Tire Pressure Monitor (1=present)";
CM_ SG_ 996 NetCfg_PASS_PT "Personal Assistant Safety System Module PT Bus (1=present)";
CM_ SG_ 996 NetCfg_AFLS "Advanced Front Lighting System (1=present)";
CM_ SG_ 996 NetCfg_ITBM "Integrated Trailer Brake Module (1=present)";
CM_ SG_ 996 NetCfg_OCM "Occupant Classification Module (1=present)";
CM_ SG_ 996 NetCfg_HaLF "Haptic Lane Feedback module (1=present)";
CM_ SG_ 996 NetCfg_ANC "Active Noise Cancellation (1=present)";
CM_ SG_ 996 NetCfg_HCP "Hybrid Control Processor (1=present)";
CM_ SG_ 996 NetCfg_ESL "Electric Steering Lock (1=present)";
CM_ SG_ 996 NetCfg_BSMO "Brake System Module - OBD (1=present)";
CM_ SG_ 996 NetCfg_SGW "Security GateWay (1=present)";
CM_ SG_ 996 NetCfg_DPDM "Driver Presence Detection Module (1=present)";
CM_ SG_ 996 NetCfg_ASBS "Automatic Sway Bar System Module (Present = 1, Not Present = 0)";
CM_ SG_ 996 NetCfg_ATMM "Active Tuned Mass Module (Present = 1, Not Present = 0)";
CM_ SG_ 996 NetCfg_SWSM "Steering wheel sensor module (HOD)";
CM_ SG_ 996 NetCfg_MSBD "Motorized Seatbelt Module (1=present)";
CM_ SG_ 998 BU_NET_CFG_STAT_INT "Backup for network configuration status";
CM_ SG_ 998 BU_NetCfg_RBSS "Backup for Right Blind-Spot Module (1=present)";
CM_ SG_ 998 BU_NetCfg_BSM "Backup for Blind-Spot Module (1=present)";
CM_ SG_ 998 BU_NetCfg_CBC_IN "Backup for Common Body Controller Int Bus (1=present)";
CM_ SG_ 998 BU_NetCfg_CSWM "Backup for Comfot Seats and Wheel Module (1=present)";
CM_ SG_ 998 BU_NetCfg_DCM_DR "Backup for Door Control Module Driver (1=present)";
CM_ SG_ 998 BU_NetCfg_DCM_PASS "Backup for Door Control Module Passenger (1=present)";
CM_ SG_ 998 BU_NetCfg_DCM_RL "Backup for Door Control Module Rear Left (1=present)";
CM_ SG_ 998 BU_NetCfg_DCM_RR "Backup for Door Control Module Rear Right (1=present)";
CM_ SG_ 998 BU_NetCfg_HVAC "Backup for Heating Ventilation Air Conditioning (1=present)";
CM_ SG_ 998 BU_NetCfg_MSM "Backup for Memory Seat Module (1=present)";
CM_ SG_ 998 BU_NetCfg_PLG "Backup for Power Liftgate Module (1=present)";
CM_ SG_ 998 BU_NetCfg_VTM "Backup for vehicle theft / tax module (1=present)";
CM_ SG_ 998 BU_NetCfg_PSD_LT "Backup for Power Sliding Door Left Module (1=present)";
CM_ SG_ 998 BU_NetCfg_PSD_RT "Backup for Power Sliding Door Right Module (1=present)";
CM_ SG_ 998 BU_NetCfg_FSM "Backup for Folding Seat Module (1=present)";
CM_ SG_ 998 BU_NetCfg_PTCM "Backup for Power Top Control Module (1=present)";
CM_ SG_ 998 BU_NetCfg_RBC "Backup for Rear Body Controller Module (1=present)";
CM_ SG_ 998 BU_NetCfg_DTV "Backup for Digital TV Module (1=present)";
CM_ SG_ 998 BU_NetCfg_TGW "Backup for Telematics gateway (1=present)";
CM_ SG_ 998 BU_NetCfg_CLOCK "Backup for CAN I Clock Module (1=present)";
CM_ SG_ 998 BU_NetCfg_VSIM "Backup for Vehicle System Interface Module (1=present)";
CM_ SG_ 998 BU_NetCfg_ITM "Backup for Intrusion module (1=present)";
CM_ SG_ 998 BU_NetCfg_AMP_I "Backup for CAN I Amplifier Module (1=present)";
CM_ SG_ 998 BU_NetCfg_DVD_CDM "Backup for CAN I in-dash disc player module (1=present)";
CM_ SG_ 998 BU_NetCfg_HFM_CTM "Backup for Convergence Telematics Module (1=present)";
CM_ SG_ 998 BU_NetCfg_ICS_I "Backup for CAN I Integrated Center Stack Module (1=present)";
CM_ SG_ 998 BU_NetCfg_VES2_I "Backup for CAN I Video Ent. System screen 2 Module (1=present)";
CM_ SG_ 998 BU_NetCfg_VES3_I "Backup for CAN I Video Ent. System screen 1 Module (1=present)";
CM_ SG_ 998 BU_NetCfg_CRSM "Backup for CAN I Comfort Rear Seat Module (1=present)";
CM_ SG_ 998 BU_NetCfg_HVAC_R "Backup for CAN I Rear Heating Ventilation Air Conditioning (1=present)";
CM_ SG_ 998 BU_NetCfg_DCSD "Backup for Disassociated Center Stack Display Module (1=present)";
CM_ SG_ 998 BU_NetCfg_TBM "Backup for Telematics Box Module (1=present)";
CM_ SG_ 998 BU_NetCfg_CVPM "Backup for CAN I Central Vision Processing Module (1=present)";
CM_ SG_ 998 BU_NetCfg_TMM "Backup for CAN I Track Mapping Module (1=present)";
CM_ SG_ 998 BU_NetCfg_ICS_R "Backup for CAN I Integrated rear Center Stack Module (1=present)";
CM_ SG_ 998 BU_NetCfg_MSM_PASS "Backup for CAN I Memory Seat Module Passenger (1=present)";
CM_ SG_ 998 BU_NetCfg_VRM "Backup for Video Routing Module (1=present)";
CM_ SG_ 998 BU_NetCfg_ANC_I "Backup for Active Noise Cancellation interior (1=present)";
CM_ SG_ 998 BU_NetCfg_TTM "0= Not Present;  1= Present";
CM_ SG_ 998 BU_NetCfg_UPFM "Backup for Upfitter Module (1=present)";
CM_ SG_ 998 BU_NetCfg_PSSM "NetCfg PSSM";
VAL_ 992 VIN_MSG 0 "VIN_LO" 1 "VIN_MID" 2 "VIN_HI" 3 "SNA" ;
VAL_ 257 ECM_SKIM_STAT 0 "OK" 1 "KILL" 2 "RUN" 3 "SNA" ;
VAL_ 257 RAD_FAN1_STAT 255 "SNA" ;
VAL_ 258 LRW 16383 "SNA" ;
VAL_ 258 VLRW 16383 "SNA" ;
VAL_ 258 LRWS_ST 0 "OK" 1 "INI" 2 "ERR" 3 "ERR_INI" ;
VAL_ 258 Pad_Shft 0 "PS_OFF" 1 "PS_RIGHT" 2 "PS_LEFT" 3 "PS_BOTH" 7 "SNA" ;
VAL_ 264 EngRPM 65535 "SNA" ;
VAL_ 264 EngTrqStatic 8191 "SNA" ;
VAL_ 264 ExpEngTrq 8191 "SNA" ;
VAL_ 264 ECM_LHOM_Trans 0 "LH_NOT_ACTIVE" 1 "NO_RDN_TRQ" 2 "PRECISE_TRQ" 3 "IMPRECISE_TRQ" ;
VAL_ 268 EngTrq_Rq_ESC 8191 "SNA" ;
VAL_ 268 EngTrq_Rq_As 8191 "SNA" ;
VAL_ 268 BrkBstrVac 255 "SNA" ;
VAL_ 268 TrlrBrkRq 63 "SNA" ;
VAL_ 268 DAS_RqActv 0 "IDLE" 1 "ACC" 2 "CMS" 3 "ABA" 4 "LSCM" 5 "CMS_XTD" 6 "PEB" 7 "SNA" ;
VAL_ 280 EngTrqMax 8191 "SNA" ;
VAL_ 280 EngTrqMin 8191 "SNA" ;
VAL_ 280 StartRelayBCMCmd 0 "SNA" ;
VAL_ 280 ECM_WTS_Inhbt 0 "INHIBIT" 1 "GRID_HEATER_OFF" 2 "GRID_HEATER_ON" 3 "SNA" ;
VAL_ 284 VEH_SPEED 65535 "SNA" ;
VAL_ 284 BrkTrq_D 16383 "SNA" ;
VAL_ 284 BrkTrq 16383 "SNA" ;
VAL_ 288 EngTrqSel_D_TTC 8191 "SNA" ;
VAL_ 288 AccelPdlPosn 255 "SNA" ;
VAL_ 288 EngTrq_DrvReqMod 8191 "SNA" ;
VAL_ 290 EngTrqMaxCorrFctr 255 "SNA" ;
VAL_ 290 GrMin_Rq_ECM 0 "PASSIVE" 1 "G1" 2 "G2" 3 "G3" 4 "G4" 5 "G5" 6 "G6" 7 "G7" ;
VAL_ 290 GrMax_Rq_ECM 0 "PASSIVE" 1 "G1" 2 "G2" 3 "G3" 4 "G4" 5 "G5" 6 "G6" 7 "G7" ;
VAL_ 290 NMOTS 65535 "SNA" ;
VAL_ 292 WhlPlsCnt_FL 255 "SNA" ;
VAL_ 292 WhlPlsCnt_FR 255 "SNA" ;
VAL_ 292 WhlPlsCnt_RL 255 "SNA" ;
VAL_ 292 WhlPlsCnt_RR 255 "SNA" ;
VAL_ 292 CENT_DIFF_ESP_RQ 0 "FREE" 1 "HOLD" 2 "OPEN" 3 "SNA" ;
VAL_ 292 R_DIFF_ESP_RQ 0 "FREE" 1 "HOLD" 2 "OPEN" 3 "SNA" ;
VAL_ 292 CENT_DIFF_TRQ_RQ 255 "SNA" ;
VAL_ 308 CRUISE_EGD 0 "SNA" ;
VAL_ 308 CRUISE_ON 0 "SNA" ;
VAL_ 308 V_MAX_TM 255 "SNA" ;
VAL_ 308 MAP_ENG 255 "SNA" ;
VAL_ 308 BARO_ENG 255 "SNA" ;
VAL_ 308 Rel_Thrt_ENG 255 "SNA" ;
VAL_ 308 Rel_Pdl_ENG 255 "SNA" ;
VAL_ 320 Brk_Stat 0 "IDLE" 1 "BRAKING" 2 "NDEF2" 3 "SNA" ;
VAL_ 320 BrkPdl_Stat 0 "UPSTOP" 1 "PSD" 2 "NDEF2" 3 "SNA" ;
VAL_ 320 ESP_Sys_Stat 0 "ABSERR" 1 "NORM" 2 "HALF" 3 "ABGAS" ;
VAL_ 320 DTR_CC_Engaged 0 "SNA" ;
VAL_ 320 GrMin_Rq_ESC 0 "PASSIVE" 1 "G1" 2 "G2" 3 "G3" 4 "G4" 5 "G5" 6 "G6" 7 "G7" ;
VAL_ 320 GrMax_Rq_ESC 0 "PASSIVE" 1 "G1" 2 "G2" 3 "G3" 4 "G4" 5 "G5" 6 "G6" 7 "G7" ;
VAL_ 320 DTR_CC_Enabled 0 "SNA" ;
VAL_ 320 ShftChrDsp_Rq_ESC 0 "SKL0" 1 "SKL1" 2 "SKL2" 3 "SKL3" 4 "SKL4" 5 "SKL5" 6 "SKL6" 7 "SKL7" 8 "SKL8" 9 "SKL9" 10 "SKL10" 11 "SKL11" 12 "SKL12" 15 "SNA" ;
VAL_ 320 RollTestMd_Actv 0 "OFF" 1 "ON" 2 "NDEF2" 3 "SNA" ;
VAL_ 320 REF_VEH_SPEED 1023 "SNA" ;
VAL_ 320 SPCR_AS_Off_Rq 0 "IDLE" 1 "AS_TMP_OFF" 2 "AS_CNTS_OFF" 3 "SPCR_NA" ;
VAL_ 324 Gr 0 "N" 1 "D1" 2 "D2" 3 "D3" 4 "D4" 5 "D5" 6 "D6" 7 "D7" 8 "D8" 9 "D2P" 10 "D9" 11 "R" 12 "R2" 13 "P" 14 "KRAFTFREI" 15 "SNA" ;
VAL_ 324 Gr_Target 0 "N" 1 "D1" 2 "D2" 3 "D3" 4 "D4" 5 "D5" 6 "D6" 7 "D7" 8 "D8" 9 "D2P" 10 "D9" 11 "R" 12 "R2" 13 "P" 14 "ABBRUCH" 15 "SNA" ;
VAL_ 324 OUTPUT_SPEED 65535 "SNA" ;
VAL_ 324 N_Turb 65535 "SNA" ;
VAL_ 324 OutputSpdPolarity 0 "DND" 1 "DF" 2 "DB" 3 "SNA" ;
VAL_ 324 Ups_Inh_Act 0 "SNA" ;
VAL_ 324 PTO_Enbl 0 "SNA" ;
VAL_ 331 BrkPrss_TMC 2047 "SNA" ;
VAL_ 331 HSA_BrkPrss 63 "SNA" ;
VAL_ 332 VehYawRate_Raw 65535 "SNA" ;
VAL_ 332 VehYawRate_Offset 255 "SNA" ;
VAL_ 332 VehAccel_X_Offset 255 "SNA" ;
VAL_ 332 VehAccel_X 255 "SNA" ;
VAL_ 332 VehAccel_Y 255 "SNA" ;
VAL_ 332 VehAccel_Y_Offset 255 "SNA" ;
VAL_ 344 WhlRPM_FL 16383 "SNA" ;
VAL_ 344 WhlDir_FL_Stat 0 "VOID" 1 "FORWARD" 2 "BACKWARD" 3 "SNA" ;
VAL_ 344 WhlRPM_FR 16383 "SNA" ;
VAL_ 344 WhlDir_FR_Stat 0 "VOID" 1 "FORWARD" 2 "BACKWARD" 3 "SNA" ;
VAL_ 344 WhlRPM_RL 16383 "SNA" ;
VAL_ 344 WhlDir_RL_Stat 0 "VOID" 1 "FORWARD" 2 "BACKWARD" 3 "SNA" ;
VAL_ 344 WhlRPM_RR 16383 "SNA" ;
VAL_ 344 WhlDir_RR_Stat 0 "VOID" 1 "FORWARD" 2 "BACKWARD" 3 "SNA" ;
VAL_ 352 TCASE_STAT 0 "SH_IPG" 1 "4LO" 2 "4HI" 3 "2WD" 4 "N" 5 "AUTO" 6 "PT" 7 "SNA" ;
VAL_ 352 ACT_CNT_DIF_TRQ 255 "SNA" ;
VAL_ 352 DES_CNT_DIF_TRQ 255 "SNA" ;
VAL_ 352 SHFT_ABRT 1 "SNA" ;
VAL_ 368 PRND_STAT 0 "LVR_P" 1 "LVR_R" 2 "LVR_N" 4 "LVR_D" 5 "NOT_R" 7 "SNA" ;
VAL_ 368 SHFT_PROG 1 "LOW" 2 "SSC" 3 "HDC" 4 "TRACK" 5 "VALET" 7 "SNOW" 11 "MUD" 12 "SAND" 16 "SKIP_SHFT" 24 "UPSHIFT_IND_RQ" 32 "BLANK" 64 "E_MODE" 65 "A" 77 "M" 83 "S" 87 "W" 249 "TX_RACE" 250 "Sport_Plus" 251 "TX_SPORT" 252 "TX_NORM" 253 "OD_OFF" 254 "TX_TOW" 255 "SNA" ;
VAL_ 368 PRNDL_DISP 32 "BLANK" 49 "ONE" 50 "TWO" 51 "THREE" 52 "FOUR" 53 "FIVE" 54 "SIX" 55 "SEVEN" 56 "EIGHT" 57 "NINE" 65 "A" 68 "D" 70 "F" 76 "L" 77 "M" 78 "N" 80 "P" 82 "R" 83 "S" 128 "DS" 130 "D2" 131 "D3" 132 "D4" 133 "D5" 135 "SNOW" 254 "NOT_N" 255 "SNA" ;
VAL_ 368 PRNDL_Blink 0 "NONE" 1 "P" 2 "R" 3 "N" 4 "D" 5 "L" 6 "S" 7 "M_TIP" ;
VAL_ 368 APCM_Rq 0 "OFF" 1 "ON" 2 "PENDING" 3 "SNA" ;
VAL_ 376 FAN_RQ 15 "SNA" ;
VAL_ 376 TX_TEMP 255 "SNA" ;
VAL_ 376 TX_WARN 0 "None" 1 "WARN_1" 2 "WARN_2" 3 "WARN_3" 4 "WARN_4" 5 "WARN_5" 6 "WARN_6" 7 "WARN_7" 8 "WARN_8" 9 "WARN_9" 10 "WARN_10" 11 "WARN_11" 12 "WARN_12" 13 "WARN_13" 14 "WARN_14" 15 "SNA" ;
VAL_ 376 TX_FAULT 0 "OK" 1 "TPF" 3 "SNA" ;
VAL_ 384 IntkAirTemp 255 "SNA" ;
VAL_ 384 EngCoolTemp 255 "SNA" ;
VAL_ 384 AirPress_Outsd 255 "SNA" ;
VAL_ 384 SysVolt 255 "SNA" ;
VAL_ 384 R134a_Press_Stat 511 "SNA" ;
VAL_ 384 CHRG_FAIL 1 "SNA" ;
VAL_ 384 AM_ECM_Prsnt 0 "DEFAULT" 2 "AM_ECM_PRSNT" 3 "SNA" ;
VAL_ 416 Trans_Trq_Ratio 2047 "SNA" ;
VAL_ 416 TxIdleRq 255 "SNA" ;
VAL_ 416 EngTrq_Rq_TCM 8191 "SNA" ;
VAL_ 448 RFFuncReq 0 "NO_BASIC_REQUEST" 1 "LOCK_REQUEST" 2 "RELOCK_REQUEST" 3 "DRIVER_UNLOCK_REQUEST" 4 "ALL_UNLOCK_REQUEST" 5 "TRUNK_PLG_TOGGLE_REQUEST" 6 "LEFT_SLIDER_TOGGLE_REQUEST" 7 "RIGHT_SLIDER_TOGGLE_REQUEST" 8 "FLIPPER_GLASS_REQUEST" 9 "REMOTE_START_ON" 10 "REMOTE_START_OFF" 11 "GLOBAL_WINDOW_DOWN_REQUEST" 12 "OPEN_CONVERTIBLE_TOP" 13 "CLOSE_CONVERTIBLE_TOP" 14 "PANIC_TOGGLE_REQUEST" 15 "DRIVER_TOGGLE_REQUEST" 16 "PASSENGER_TOGGLE_REQUEST" 17 "ExtLightReq" 18 "AirSuspReq" 19 "AirSuspCancel" 20 "GLBL_WIN_UP_RQ" 21 "CAR_FINDER_REQUEST" 22 "TRUNK_PLG_BTN_PRESSED" 23 "TRUNK_PLG_STOP_REQUEST" 24 "TRUNK_PLG_OPEN_REQUEST" 25 "TRUNK_PLG_CLOSE_REQUEST" 26 "VTA_RQ" 27 "RAP_UNLOCK_REQUEST" 31 "SNA" ;
VAL_ 448 RFReq 0 "REQUESTOR_DEFAULT" 1 "REQUESTOR_RKE" 2 "REQUESTOR_PE" 3 "REQUESTOR_REMOTESTART" 4 "REQUESTOR_UCONNECT" 5 "REQUESTOR_PE_HANDSFREE" 7 "SNA" ;
VAL_ 448 RFCfgReq 0 "DEFAULT" 1 "HORN_CHIRP_TOGGLE" 2 "OPTICAL_CHIRP_TOGGLE" 3 "DRIVER_UNLOCK_FIRST_TOGGLE" 7 "SNA" ;
VAL_ 448 RFFobNum 0 "FOB_DEFAULT" 1 "FOB_1" 2 "FOB_2" 3 "FOB_3" 4 "FOB_4" 5 "FOB_5" 6 "FOB_6" 7 "FOB_7" 8 "FOB_8" 15 "SNA" ;
VAL_ 456 VTA_STAT 0 "VTA_DISARM" 1 "VTA_PREARM" 2 "VTA_ARM" 3 "VTA_LGT" 4 "VTA_LGT_HORN" 5 "VTA_TAMP" 6 "VTA_ITM_Alarm" 7 "SNA" ;
VAL_ 464 SRS_IndLmp_Rq 0 "OFF" 1 "CONT" 2 "BLINK" 3 "SNA" ;
VAL_ 464 DRV_SEATBELT 0 "DRV_SEATBELT_OK" 1 "DRV_SEATBELT_NOK" 2 "SEATBELT_FAIL" 3 "SNA" ;
VAL_ 464 PSG_SEATBELT 0 "PSG_SEATBELT_OK" 1 "PSG_SEATBELT_NOK" 2 "SEATBELT_FAIL" 3 "SNA" ;
VAL_ 464 PSG_ODS_STAT 0 "ODS_STAT_NOCC" 1 "ODS_STAT_OCC" 2 "ODS_FAULT" 3 "SNA" ;
VAL_ 464 DrvSbltUnFltr 0 "BUCKLED" 1 "UNBUCKLED" 2 "LOW" 3 "HIGH" 7 "SNA" ;
VAL_ 500 EngTrqRq_DAS 8191 "SNA" ;
VAL_ 500 DAS_ACCEL_Rq 4095 "SNA" ;
VAL_ 500 GrMax_RqDAS 0 "PASSIVE" 1 "G1" 2 "G2" 3 "G3" 4 "G4" 5 "G5" 6 "G6" 7 "G7" 8 "G8" 9 "G9" 10 "G10" 11 "G11" 12 "G12" ;
VAL_ 500 DAS_Rq_ID 0 "IDLE" 1 "ACC" 2 "CMS" 3 "ABA" 4 "LSCM" 5 "CMS_XTD" 6 "PEB" 7 "SNA" ;
VAL_ 500 DAS_Sts 0 "OK" 1 "INTERNAL" 2 "EXTERNAL" 3 "SNA" ;
VAL_ 500 As_DispRq 0 "No_RQ" 1 "ACC" 2 "FCW" 3 "SNA" ;
VAL_ 501 HMI_Screens 255 "SNA" ;
VAL_ 501 SetSpeed_KPH 255 "SNA" ;
VAL_ 501 SetSpeed_MPH 255 "SNA" ;
VAL_ 501 FCW_Error 0 "No_Error" 1 "FCW_Error" 2 "Limited_FCW" 3 "SNA" ;
VAL_ 501 ACCOnOff 0 "OFF" 1 "NCC" 2 "NCC_SET" 3 "ACC_ON" 4 "ACC_SET" 7 "SNA" ;
VAL_ 501 Sm_ICON_Dspl 0 "NONE" 1 "OFF" 2 "READY_TG1" 3 "READY_TG2" 4 "READY_TG3" 5 "READY_TG4" 8 "ACC_E_NT_TG1" 9 "ACC_E_NT_TG2" 10 "ACC_E_NT_TG3" 11 "ACC_E_NT_TG4" 12 "ACC_E_WT_TG1" 13 "ACC_E_WT_TG2" 14 "ACC_E_WT_TG3" 15 "ACC_E_WT_TG4" 33 "NCC_OFF" 34 "NCC_READY" 40 "NCC_ENGAGED" 63 "SNA" ;
VAL_ 501 ObjIntrstDist 255 "SNA" ;
VAL_ 512 AirTemp_Outsd 255 "SNA" ;
VAL_ 512 AMB_TEMP_AVG 65535 "SNA" ;
VAL_ 512 AMB_TEMP_VOLT 255 "SNA" ;
VAL_ 512 FUEL_VOLT 255 "SNA" ;
VAL_ 512 FUEL_VOLT2 255 "SNA" ;
VAL_ 512 BATT_VOLT 255 "SNA" ;
VAL_ 520 AC_OutptCurrStat 255 "SNA" ;
VAL_ 520 BrkPdlStat_CBC 0 "UPSTOP" 1 "PSD" 2 "NDEF2" 3 "SNA" ;
VAL_ 520 CBCEngineOffRequest 0 "Not Active" 1 "Active" ;
VAL_ 559 ActlAccelPdlPosn 255 "SNA" ;
VAL_ 608 PTS_PopUpRqst 0 "TM0" 1 "TM1" 2 "TM2" 3 "TM3" 4 "TM4" 5 "TM5" 6 "TM6" 7 "TM7" 8 "TM8" 9 "TM9" 10 "TM10" 11 "TM11" 12 "TM12" 13 "TM13" 14 "TM14" 15 "TM15" 16 "TM16" 17 "TM17" 18 "TM18" 19 "TM19" 20 "TM20" 21 "TM21" 22 "TM22" 23 "TM23" 24 "TM24" 25 "TM25" 26 "TM26" 27 "TM27" 28 "TM28" 29 "TM29" 30 "TM30" 31 "TM31" 32 "TM32" 33 "TM33" 34 "TM34" 35 "TM35" 36 "TM36" 37 "TM37" 38 "TM38" 39 "TM39" 40 "TM40" 41 "TM41" 42 "TM42" 43 "TM43" 44 "TM44" 45 "TM45" 46 "TM46" 47 "TM47" 48 "TM48" 49 "TM49" 50 "TM50" 51 "TM51" 52 "TM52" 53 "TM53" 54 "TM54" 55 "TM55" 56 "TM56" 57 "TM57" 58 "TM58" 59 "TM59" 60 "TM60" 61 "TM61" 62 "TM62" 63 "TM63" 64 "TM64" 65 "TM65" 66 "TM66" 67 "TM67" 68 "TM68" 69 "TM69" 70 "TM70" 71 "TM71" 72 "TM72" 73 "TM73" 74 "TM74" 75 "TM75" 76 "TM76" 77 "TM77" 78 "TM78" 79 "TM79" 80 "TM80" 81 "TM81" 82 "TM82" 83 "TM83" 84 "TM84" 85 "TM85" 86 "TM86" 87 "TM87" 88 "TM88" 89 "TM89" 90 "TM90" 91 "TM91" 92 "TM92" 93 "TM93" 94 "TM94" 95 "TM95" 96 "TM96" 97 "TM97" 98 "TM98" 99 "TM99" 100 "TM100" 255 "SNA" ;
VAL_ 608 PTS_STAT_Front 0 "OFF" 1 "CONT" 2 "BLINK" 3 "SNA" ;
VAL_ 624 EngineOffTimer 4095 "SNA" ;
VAL_ 624 Gate_Req_PE 0 "NO_REQ" 1 "HNDL_PE_REQ" 2 "BTN_PE_REQ" 3 "HF_PE_REQ" ;
VAL_ 624 FuelTxfrSts 0 "OFF" 1 "ON" 2 "FAULT" 3 "SNA" ;
VAL_ 632 CC_SetSpdDspl 255 "SNA" ;
VAL_ 632 EVPmpStat 0 "OFF" 1 "ON" 2 "FAULT" 3 "SNA" ;
VAL_ 632 CC_SetSpdDsplMPH 255 "SNA" ;
VAL_ 639 IBS_Q_received 65535 "SNA" ;
VAL_ 639 IBS_Q_released 65535 "SNA" ;
VAL_ 639 IBS_Tm_Lst_Reset_Sec 65535 "SNA" ;
VAL_ 639 IBS_Tm_Lst_Reset_Days 4095 "SNA" ;
VAL_ 660 SyncPos 0 "LOW" 1 "HIGH" 2 "PRESS" 3 "TEMP" 4 "NS" 7 "SNA" ;
VAL_ 672 ETC_IND_LMP 0 "OFF" 1 "ON" 2 "ON_Flashing" 3 "SNA" ;
VAL_ 672 EngOilIndLmp_On_Rq 1 "SNA" ;
VAL_ 672 OIL_TEMP_IND_RQ 0 "IND_LMP_OFF" 1 "IND_LMP_ON" 2 "IND_LMP_FLASH" 3 "SNA" ;
VAL_ 672 OIL_PRESS 255 "SNA" ;
VAL_ 672 EngOilTemp 255 "SNA" ;
VAL_ 672 FuelCons 65535 "SNA" ;
VAL_ 672 DefFuelEcon 255 "SNA" ;
VAL_ 672 EngRun_Stat 0 "STOP" 1 "START" 2 "IDLE_UNSTBL" 3 "IDLE_STBL" 4 "UNLIMITED" 5 "LIMITED" 6 "NDEF6" 7 "SNA" ;
VAL_ 672 CoolLo 0 "SNA" ;
VAL_ 680 EngTrgtSpdCtrl 4095 "SNA" ;
VAL_ 680 CurrentGear 0 "N" 1 "D1" 2 "D2" 3 "D3" 4 "D4" 5 "D5" 6 "D6" 7 "D7" 8 "D8" 9 "D2P" 10 "D9" 11 "R" 12 "R2" 13 "P" 14 "KRAFTFREI" 15 "SNA" ;
VAL_ 680 CurrentGearForDisplay 0 "Initialize" 1 "D1" 2 "D2" 3 "D3" 4 "D4" 5 "D5" 6 "D6" 7 "D7" 8 "D8" 9 "D9" 12 "P" 13 "N" 14 "R" 15 "SNA" ;
VAL_ 680 TargetGear 0 "N" 1 "D1" 2 "D2" 3 "D3" 4 "D4" 5 "D5" 6 "D6" 7 "D7" 8 "D8" 9 "D2P" 10 "D9" 11 "R" 12 "R2" 13 "P" 14 "ABBRUCH" 15 "SNA" ;
VAL_ 680 TX_WARN2 0 "None" 1 "WARN_1" 2 "WARN_2" 3 "WARN_3" 4 "WARN_4" 5 "WARN_5" 6 "WARN_6" 7 "WARN_7" 8 "WARN_8" 9 "WARN_9" 10 "WARN_10" 11 "WARN_11" 12 "WARN_12" 13 "WARN_13" 14 "WARN_14" 15 "WARN_15" 17 "WARN_17" 18 "WARN_18" 19 "WARN_19" 20 "WARN_20" 21 "WARN_21" 22 "WARN_22" 23 "WARN_23" 24 "WARN_24" 25 "WARN_25" 31 "WARN_31" 32 "WARN_32" 33 "WARN_33" 34 "WARN_34" 35 "WARN_35" 36 "WARN_36" 37 "WARN_37" 38 "WARN_38" 39 "WARN_39" 40 "WARN_40" 41 "WARN_41" 42 "WARN_42" 43 "WARN_43" 44 "WARN_44" 45 "WARN_45" 46 "WARN_46" 47 "WARN_47" 48 "WARN_48" 49 "WARN_49" 50 "WARN_50" 51 "WARN_51" 52 "WARN_52" 53 "WARN_53" 54 "WARN_54" 55 "WARN_55" 56 "WARN_56" 57 "WARN_57" 58 "WARN_58" 59 "WARN_59" 60 "WARN_60" 61 "WARN_61" 62 "WARN_62" 63 "WARN_63" 64 "WARN_64" 65 "WARN_65" 66 "WARN_66" 67 "WARN_67" 68 "WARN_68" 69 "WARN_69" 70 "WARN_70" 71 "WARN_71" 72 "WARN_72" 255 "SNA" ;
VAL_ 698 UConnReq 0 "NO_BASIC_REQUEST" 1 "LOCK_REQUEST" 2 "RELOCK_REQUEST" 3 "DRIVER_UNLOCK_REQUEST" 4 "ALL_UNLOCK_REQUEST" 5 "TRUNK_PLG_TOGGLE_REQUEST" 6 "LEFT_SLIDER_TOGGLE_REQUEST" 7 "RIGHT_SLIDER_TOGGLE_REQUEST" 8 "FLIPPER_GLASS_REQUEST" 9 "REMOTE_START_ON" 10 "REMOTE_START_OFF" 11 "GLOBAL_WINDOW_DOWN_REQUEST" 12 "OPEN_CONVERTIBLE_TOP" 13 "CLOSE_CONVERTIBLE_TOP" 14 "PANIC_TOGGLE_REQUEST" 15 "DRIVER_TOGGLE_REQUEST" 16 "PASSENGER_TOGGLE_REQUEST" 17 "ExtLightReq" 18 "AirSuspReq" 19 "AirSuspCancel" 20 "GLBL_WIN_UP_RQ" 21 "CAR_FINDER_REQUEST" 22 "TRUNK_PLG_BTN_PRESSED" 23 "TRUNK_PLG_STOP_REQUEST" 24 "TRUNK_PLG_OPEN_REQUEST" 25 "TRUNK_PLG_CLOSE_REQUEST" 26 "VTA_RQ" 31 "SNA" ;
VAL_ 698 UConnReqAuthCode 65535 "SNA" ;
VAL_ 698 UConnReqFOBNum 0 "FOB_DEFAULT" 1 "FOB_1" 2 "FOB_2" 3 "FOB_3" 4 "FOB_4" 5 "FOB_5" 6 "FOB_6" 7 "FOB_7" 8 "FOB_8" 15 "SNA" ;
VAL_ 706 EC_ECUCfg15_Stat 0 "NA" 1 "PROGAMMED" 2 "REQUEST_DATA" 3 "SNA" ;
VAL_ 707 EC_BU_ECUCfg15_Stat 0 "NA" 1 "PROGAMMED" 2 "NA1" 3 "SNA" ;
VAL_ 720 BSM_CFG_STAT 0 "NT_ENB" 1 "ENB_LED" 2 "ENB_LED_CHM" 3 "SNA" ;
VAL_ 720 BSM_LT_WRN 0 "NW" 2 "RM_LED" 3 "RBM_LED" 4 "FM_LED" 5 "FBM_LED" 7 "SNA" ;
VAL_ 720 BSM_RT_WRN 0 "NW" 2 "RM_LED" 3 "RBM_LED" 4 "FM_LED" 5 "FBM_LED" 7 "SNA" ;
VAL_ 736 LT_DIST 65535 "SNA" ;
VAL_ 736 RT_DIST 65535 "SNA" ;
VAL_ 736 HILL_DES_STAT 0 "HDC_UNAVL" 1 "HDC_ACT" 2 "HDC_AVL" 3 "HDC_THRML_DEACT" ;
VAL_ 736 ESP_Off_IndLmp_On_Rq 0 "SNA" ;
VAL_ 736 ESC_CtrlLmp_Info 0 "OFF" 1 "CONT" 2 "BLINK" 3 "SNA" ;
VAL_ 736 ABS_IndLmp_On_Rq 0 "OFF" 1 "CONT" 2 "BLINK" 3 "SNA" ;
VAL_ 736 BrkIndLmp_On_Rq_ESC 0 "OFF" 1 "CONT" 2 "BLINK" 3 "SNA" ;
VAL_ 736 SelSpdLmp 0 "OFF" 1 "CONT" 2 "BLINK" 3 "SNA" ;
VAL_ 746 DrvRqShftROT 0 "INIT" 1 "PARK" 2 "REV" 3 "NEUT" 4 "DRIVE" 5 "FIFTH" 7 "SNA" ;
VAL_ 746 APCM_Stat 0 "OFF" 1 "ON" 2 "PENDING" 3 "SNA" ;
VAL_ 760 EngTrqTgt_SEM 8191 "SNA" ;
VAL_ 760 EngTrqStatic_SEM 8191 "SNA" ;
VAL_ 760 TRANS_CLU_SLIP_MODE 0 "NORMAL" 1 "MDS_RQ" 2 "IDFSO_RQ" 3 "AC_EN_DIS_RQ" 4 "IDFSO_ACTIVE" 5 "MDS_IDFSO_ACT" 7 "SNA" ;
VAL_ 760 EngMaxRPM 255 "SNA" ;
VAL_ 764 RawPVS1 255 "SNA" ;
VAL_ 764 RawPVS2 255 "SNA" ;
VAL_ 764 RawTPS1 255 "SNA" ;
VAL_ 764 RawTPS2 255 "SNA" ;
VAL_ 764 RelativePdl 255 "SNA" ;
VAL_ 764 RelativeThrt 255 "SNA" ;
VAL_ 764 MAP 255 "SNA" ;
VAL_ 766 VVT_ExhCam1Pos 0 "SNA" ;
VAL_ 766 VVT_ExhCam2Pos 0 "SNA" ;
VAL_ 766 VVT_IntCam1Pos 0 "SNA" ;
VAL_ 766 VVT_IntCam2Pos 0 "SNA" ;
VAL_ 766 GF_Charge 65535 "SNA" ;
VAL_ 766 RelativeThrtPct 255 "SNA" ;
VAL_ 776 CNT_DIFF_MOD 0 "FREE" 1 "LM" 2 "ESP" 3 "SNA" ;
VAL_ 776 DTCM_HMI_Rq 0 "NONE" 1 "SCREEN_1" 2 "SCREEN_2" 3 "SCREEN_3" 4 "SCREEN_4" 5 "SCREEN_5" 6 "SCREEN_6" 7 "SCREEN_7" 8 "SCREEN_8" 9 "SCREEN_9" 10 "SCREEN_10" 11 "SCREEN_11" 12 "SCREEN_12" 13 "SCREEN_13" 14 "SCREEN_14" 15 "SCREEN_15" 16 "SCREEN_16" 17 "SCREEN_17" 18 "SCREEN_18" 19 "SCREEN_19" 20 "SCREEN_20" 21 "SCREEN_21" 22 "SCREEN_22" 23 "SCREEN_23" 24 "SCREEN_24" 25 "SCREEN_25" 26 "SCREEN_26" 27 "SCREEN_27" 28 "SCREEN_28" 29 "SCREEN_29" 30 "SCREEN_30" 31 "SNA" ;
VAL_ 776 TCASE_SRV_RQ 0 "OFF" 1 "ON" 2 "BLINK" 3 "SNA" ;
VAL_ 776 TcaseAWD 0 "OFF" 1 "ON" 2 "BLINK" 3 "SNA" ;
VAL_ 776 Tcase4Low 0 "OFF" 1 "ON" 2 "BLINK" 3 "SNA" ;
VAL_ 776 TcaseNtrlStat 0 "OFF" 1 "ON" 2 "BLINK" 3 "SNA" ;
VAL_ 776 Tcase4Lock 0 "OFF" 1 "ON" 2 "BLINK" 3 "SNA" ;
VAL_ 776 Tcase2WD_Stat 0 "OFF" 1 "ON" 2 "BLINK" 3 "SNA" ;
VAL_ 779 DisOilLifeRst 65535 "SNA" ;
VAL_ 779 OilLifeLeft 255 "SNA" ;
VAL_ 779 MntncSts 0 "NONE" 1 "SOON" 2 "NOW" 3 "SNA" ;
VAL_ 779 HoursOilLifeRst 4095 "SNA" ;
VAL_ 779 FuelFltrLeft 255 "SNA" ;
VAL_ 784 AvgFuelLvl 511 "SNA" ;
VAL_ 784 SRS_LMP_STAT 0 "SRS_LMP_OFF" 1 "SRS_LMP_ON" 2 "SRS_LMP_ON_IC" 3 "SNA" ;
VAL_ 784 ODO 16777215 "SNA" ;
VAL_ 788 CFG_FEATURE 0 "CFG_NONE" 1 "CFG_AUTO_LK" 2 "CFG_AUTO_UNLK" 3 "CFG_DLY_LK" 4 "CFG_DRV_FST" 5 "CFG_SOUND_LK" 6 "CFG_HORN_DUR" 7 "CFG_FLASH_LK" 8 "CFG_DrAlrPrsnt" 9 "CFG_PARK_ASSIST" 10 "CFG_LANG" 11 "CFG_US_METRIC" 12 "CFG_SRV_INTV" 13 "CFG_AUTO_WPR" 14 "CFG_HL_DLY" 15 "CFG_HL_WPR" 16 "CFG_ACC_DLY" 18 "CFG_REM_MEM" 19 "CFG_EASY_EXIT" 20 "CFG_LO_VEH" 21 "CFG_TILT_IN_REV" 22 "CFG_ILL_APRCH" 23 "CFG_ILL_ENTRY" 24 "CFG_GLBL_UP_WIN" 25 "CFG_GLBL_DN_WIN" 26 "CFG_DRL_ON" 27 "CFG_AHB" 28 "REST_FACT_DEF" 29 "CFG_CMP_CAL" 30 "CFG_CMP_VAR" 31 "CFG_VOICE_COMF" 32 "CFG_NAV_TBYT" 33 "CFG_HILL_ST" 34 "CFG_AFS" 35 "CFG_BSD" 36 "CFG_PE" 37 "CFG_WAL" 38 "CFG_DSS" 39 "CFG_SOUND_RS" 40 "CFG_DCS" 41 "CFG_AUTO_RELK" 42 "CFG_CMS" 43 "CFG_FCW" 44 "CFG_PRE_SAFE" 45 "CFG_BELT_SLAK" 46 "CFG_FUEL_SAV" 47 "CFG_FCW_SENS" 48 "CFG_HDLP_DROP" 49 "CFG_ECMM" 50 "PASS_WIN_LKOUT" 51 "AERO" 52 "JACK" 53 "CFG_TRLR" 54 "CFG_ALIGNMENT" 55 "CFG_ASCM_WMO" 57 "CFG_LDW" 58 "OIL" 59 "CFG_NORMAL_DCS" 61 "CFG_TRANSPORT" 62 "CFG_PTO_MODE" 63 "CFG_PTO_SINGLE_RPM" 64 "CFG_PTO_RPM1" 65 "CFG_PTO_RPM2" 66 "CFG_PTO_RPM3" 67 "CFG_PTO_Type" 68 "CFG_PTO_Auto_Resume" 69 "CFG_MAX_PTO_VEH_SPEED" 70 "RVC_GRID" 71 "DIMMER" 72 "RLE_LIGHT" 73 "RLE_HORN" 76 "CFG_TRLR_TYP" 77 "CFG_TRLR_NAME" 81 "CFG_PTS_FT" 82 "CFG_PTS_RR" 83 "CFG_PTS_FT_VOL" 84 "CFG_PTS_RR_VOL" 86 "CFG_PLG" 87 "CFG_AUX1" 88 "CFG_AUX2" 89 "CFG_AUX3" 90 "CFG_AUX4" 91 "CFG_AUX5" 93 "CFG_LDWTRQ" 94 "CFG_PTO_REM_Throttle" 95 "CFG_UNIT_DEFAULT" 96 "CFG_PressureUnit" 97 "CFG_SpeedUnit" 98 "CFG_DistanceUnit" 99 "CFG_ConsumptionUnit" 100 "CFG_CapacityUnit" 101 "CFG_TemperatureUnit" 102 "CFG_PowerUnit" 103 "CFG_TorqueUnit" 104 "CFG_EPS" 105 "CFG_CHMSL_LINES" 106 "CFG_POLICE_PE" 107 "EPB_AUTO_PRK" 108 "EPB_SERVICE" 109 "HOLD_N_GO" 110 "PWR_FLD_MRR" 111 "HANDS_FREE_LFT" 112 "HANDS_FREE_SLDR" 113 "SVC_GRIDLINES" 114 "SVC_DELAY" 115 "SLD_DR_ALRT" 116 "TEEN_FCW_SENS" 117 "TEEN_FCW_BRK" 118 "TEEN_PRK_ASST" 119 "TEEN_PRK_ASST_BRK" 120 "TEEN_FT_PRK_VOL" 121 "TEEN_RR_PRK_VOL" 122 "TEEN_MAX_SPEED" 123 "TEEN_FUEL_WRN" 124 "TEEN_FUEL_POPUP" 125 "TEEN_BLIND_SPOT" 126 "TEEN_RAIN_WPR" 127 "TEEN_AUTO_HB" 128 "TEEN_LGHT_WPR" 129 "TEEN_SLD_DR_ALRT" 130 "TEEN_PLG_CHIME" 131 "SLD_DR_CHM" 132 "TEEN_SLD_DR_CHM" 133 "CFG_ABSM" 134 "CFG_PADDLE_SHIFT" 137 "CFG_PRK_ASST_BRK" 138 "CFG_LDW_ON" 139 "CFG_PRK_ASST_TYPE" 140 "CFG_DR_ALR" 141 "CFG_RDY_DRV" 142 "CFG_PANEL_INTS" 143 "CFG_MOOD_LGT_INTS" 144 "CFG_ML_HDLP_LVL" 145 "CFG_BSM_TRLR" 146 "CFG_AUTO_SS" 147 "CFG_PCS" 148 "CFG_UNIT_SET" 149 "CFG_DOORS_OFF_ACC_DLY" 150 "CFG_MOTORIZED_SEATBELT" 151 "CFG_MOTORIZED_SEATBELT_STRN" 152 "CFG_TSI" 153 "CFG_LKA" 154 "CFG_LKA_SENS" 155 "CFG_LKA_STRN" 156 "CFG_ABSD" 157 "CFG_ABSD_SENS" 158 "CFG_ABSD_STRN" 162 "CFG_TIRE_FILL_ALERT" 163 "CFG_POWER_SIDE_STEP" 164 "CFG_AUTO_STOP_START" 165 "CFG_PEB" 166 "CFG_FFC_GRIDLINES" 167 "CFG_RVC_CVPM_DGRID" 168 "CFG_RVC_CVPM_SGRID" 169 "CFG_SPEED_THRESHOLD_VALUE" 170 "CFG_SPEED_THRESHOLD_CHECK_BOX" 171 "CFG_EXTERNAL_LIGHT_SENSOR" 172 "CFG_BUZZER_VOLUME_LEVEL" 173 "CFG_TRUNK_UNLOCK_ENABLE" 174 "CFG_BACKUP_ALARM" 175 "CFG_RR_CARGO_GUIDE_LGT" 176 "CFG_PTO_HI_IDLE" 177 "CFG_PTO_HI_IDLE_RPM" 178 "CFG_PTO_RMT_RPM_CTRL" 179 "CFG_PTO_SS_GEAR_RATIO" 180 "CFG_PTO_ACC_INT" 181 "CFG_PTO_RAMP_RATE" 182 "CFG_PTO_PB" 183 "CFG_HWRSS" 184 "CFG_SEIU_INPUT_WIRE" 185 "CFG_SEIU_RPM" 186 "CFG_BED_LOWER" 187 "CFG_TSR_WARNING_MODE" 188 "CFG_TSR_WARNING_MODE_OFFSET" 189 "CFG_FT_PK_LOOSE_SHIP" 190 "CFG_RR_PK_LOOSE_SHIP" 191 "CFG_AUX6" 192 "CFG_CHMSL_DYN_CNTR" ;
VAL_ 788 CFG_STAT_RQ 0 "CFG_DEF" 1 "CFG_DSBL" 2 "CFG_ENBL" 3 "CFG_SPEC" ;
VAL_ 790 CFG_FEATURE_C 0 "CFG_NONE" 1 "CFG_AUTO_LK" 2 "CFG_AUTO_UNLK" 3 "CFG_DLY_LK" 4 "CFG_DRV_FST" 5 "CFG_SOUND_LK" 6 "CFG_HORN_DUR" 7 "CFG_FLASH_LK" 8 "CFG_DrAlrPrsnt" 9 "CFG_PARK_ASSIST" 10 "CFG_LANG" 11 "CFG_US_METRIC" 12 "CFG_SRV_INTV" 13 "CFG_AUTO_WPR" 14 "CFG_HL_DLY" 15 "CFG_HL_WPR" 16 "CFG_ACC_DLY" 18 "CFG_REM_MEM" 19 "CFG_EASY_EXIT" 20 "CFG_LO_VEH" 21 "CFG_TILT_IN_REV" 22 "CFG_ILL_APRCH" 23 "CFG_ILL_ENTRY" 24 "CFG_GLBL_UP_WIN" 25 "CFG_GLBL_DN_WIN" 26 "CFG_DRL_ON" 27 "CFG_AHB" 28 "REST_FACT_DEF" 29 "CFG_CMP_CAL" 30 "CFG_CMP_VAR" 31 "CFG_VOICE_COMF" 32 "CFG_NAV_TBYT" 33 "CFG_HILL_ST" 34 "CFG_AFS" 35 "CFG_BSD" 36 "CFG_PE" 37 "CFG_WAL" 38 "CFG_DSS" 39 "CFG_SOUND_RS" 40 "CFG_DCS" 41 "CFG_AUTO_RELK" 42 "CFG_CMS" 43 "CFG_FCW" 44 "CFG_PRE_SAFE" 45 "CFG_BELT_SLAK" 46 "CFG_FUEL_SAV" 47 "CFG_FCW_SENS" 48 "CFG_HDLP_DROP" 49 "CFG_ECMM" 50 "PASS_WIN_LKOUT" 51 "AERO" 52 "JACK" 53 "CFG_TRLR" 54 "CFG_ALIGNMENT" 55 "CFG_ASCM_WMO" 57 "CFG_LDW" 58 "OIL" 59 "CFG_NORMAL_DCS" 61 "CFG_TRANSPORT" 62 "CFG_PTO_MODE" 63 "CFG_PTO_SINGLE_RPM" 64 "CFG_PTO_RPM1" 65 "CFG_PTO_RPM2" 66 "CFG_PTO_RPM3" 67 "CFG_PTO_Type" 68 "CFG_PTO_Auto_Resume" 69 "CFG_MAX_PTO_VEH_SPEED" 70 "RVC_GRID" 71 "DIMMER" 72 "RLE_LIGHT" 73 "RLE_HORN" 76 "CFG_TRLR_TYP" 77 "CFG_TRLR_NAME" 81 "CFG_PTS_FT" 82 "CFG_PTS_RR" 83 "CFG_PTS_FT_VOL" 84 "CFG_PTS_RR_VOL" 86 "CFG_PLG" 87 "CFG_AUX1" 88 "CFG_AUX2" 89 "CFG_AUX3" 90 "CFG_AUX4" 91 "CFG_AUX5" 93 "CFG_LDWTRQ" 94 "CFG_PTO_REM_Throttle" 95 "CFG_UNIT_DEFAULT" 96 "CFG_PressureUnit" 97 "CFG_SpeedUnit" 98 "CFG_DistanceUnit" 99 "CFG_ConsumptionUnit" 100 "CFG_CapacityUnit" 101 "CFG_TemperatureUnit" 102 "CFG_PowerUnit" 103 "CFG_TorqueUnit" 104 "CFG_EPS" 105 "CFG_CHMSL_LINES" 106 "CFG_POLICE_PE" 107 "EPB_AUTO_PRK" 108 "EPB_SERVICE" 109 "HOLD_N_GO" 110 "PWR_FLD_MRR" 111 "HANDS_FREE_LFT" 112 "HANDS_FREE_SLDR" 113 "SVC_GRIDLINES" 114 "SVC_DELAY" 115 "SLD_DR_ALRT" 116 "TEEN_FCW_SENS" 117 "TEEN_FCW_BRK" 118 "TEEN_PRK_ASST" 119 "TEEN_PRK_ASST_BRK" 120 "TEEN_FT_PRK_VOL" 121 "TEEN_RR_PRK_VOL" 122 "TEEN_MAX_SPEED" 123 "TEEN_FUEL_WRN" 124 "TEEN_FUEL_POPUP" 125 "TEEN_BLIND_SPOT" 126 "TEEN_RAIN_WPR" 127 "TEEN_AUTO_HB" 128 "TEEN_LGHT_WPR" 129 "TEEN_SLD_DR_ALRT" 130 "TEEN_PLG_CHIME" 131 "SLD_DR_CHM" 132 "TEEN_SLD_DR_CHM" 133 "CFG_ABSM" 134 "CFG_PADDLE_SHIFT" 137 "CFG_PRK_ASST_BRK" 138 "CFG_LDW_ON" 139 "CFG_PRK_ASST_TYPE" 140 "CFG_DR_ALR" 141 "CFG_RDY_DRV" 142 "CFG_PANEL_INTS" 143 "CFG_MOOD_LGT_INTS" 144 "CFG_ML_HDLP_LVL" 145 "CFG_BSM_TRLR" 146 "CFG_AUTO_SS" 147 "CFG_PCS" 148 "CFG_UNIT_SET" 149 "CFG_DOORS_OFF_ACC_DLY" 150 "CFG_MOTORIZED_SEATBELT" 151 "CFG_MOTORIZED_SEATBELT_STRN" 152 "CFG_TSI" 153 "CFG_LKA" 154 "CFG_LKA_SENS" 155 "CFG_LKA_STRN" 156 "CFG_ABSD" 157 "CFG_ABSD_SENS" 158 "CFG_ABSD_STRN" 162 "CFG_TIRE_FILL_ALERT" 163 "CFG_POWER_SIDE_STEP" 164 "CFG_AUTO_STOP_START" 165 "CFG_PEB" 166 "CFG_FFC_GRIDLINES" 167 "CFG_RVC_CVPM_DGRID" 168 "CFG_RVC_CVPM_SGRID" 169 "CFG_SPEED_THRESHOLD_VALUE" 170 "CFG_SPEED_THRESHOLD_CHECK_BOX" 171 "CFG_EXTERNAL_LIGHT_SENSOR" 172 "CFG_BUZZER_VOLUME_LEVEL" 173 "CFG_TRUNK_UNLOCK_ENABLE" 174 "CFG_BACKUP_ALARM" 175 "CFG_RR_CARGO_GUIDE_LGT" 176 "CFG_PTO_HI_IDLE" 177 "CFG_PTO_HI_IDLE_RPM" 178 "CFG_PTO_RMT_RPM_CTRL" 179 "CFG_PTO_SS_GEAR_RATIO" 180 "CFG_PTO_ACC_INT" 181 "CFG_PTO_RAMP_RATE" 182 "CFG_PTO_PB" 183 "CFG_HWRSS" 184 "CFG_SEIU_INPUT_WIRE" 185 "CFG_SEIU_RPM" 186 "CFG_BED_LOWER" 187 "CFG_TSR_WARNING_MODE" 188 "CFG_TSR_WARNING_MODE_OFFSET" 189 "CFG_FT_PK_LOOSE_SHIP" 190 "CFG_RR_PK_LOOSE_SHIP" 191 "CFG_AUX6" 192 "CFG_CHMSL_DYN_CNTR" ;
VAL_ 790 CFG_STAT_RQ_C 0 "CFG_DEF" 1 "CFG_DSBL" 2 "CFG_ENBL" 3 "CFG_SPEC" ;
VAL_ 792 TurnIndLvr_Stat 0 "IDLE" 1 "LEFT" 2 "RIGHT" ;
VAL_ 792 HiBmLvr_Stat 0 "IDLE" 1 "HIBM_ON_PSD" 2 "HIBM_FLSH_ON_PSD" ;
VAL_ 792 WprWashSw_Psd 0 "NPSD" 1 "MIST" 2 "WASH" ;
VAL_ 792 WprSw6Posn 0 "OFF" 1 "INTERVAL1" 2 "INTERVAL2" 3 "INTERVAL3" 4 "INTERVAL4" 5 "INTERVAL5" 6 "INTERVAL6" 13 "WPR_LOW" 14 "WPR_HI" 15 "SNA" ;
VAL_ 792 VOL 0 "VOL_NONE" 1 "VOL_UP" 2 "VOL_DN" 3 "SNA" ;
VAL_ 792 Up_Arw_Rq 0 "NOT_PSD" 1 "PSD" 3 "SNA" ;
VAL_ 792 StW_TempSens_Flt 0 "OK" 1 "SHRT" 2 "OPN" 3 "SNA" ;
VAL_ 792 StW_Temp 255 "SNA" ;
VAL_ 792 SEEK 0 "SEEK_NONE" 1 "SEEK_UP" 2 "SEEK_DN" 3 "SNA" ;
VAL_ 792 RT_ARW_RST_RQ 0 "NOT_PSD" 1 "PSD" 3 "SNA" ;
VAL_ 792 PRESET_CFG 0 "PRESET_NONE" 1 "PRESET_UP" 2 "PRESET_DOWN" 3 "SNA" ;
VAL_ 792 MENU_RQ 0 "NOT_PSD" 1 "PSD" 3 "SNA" ;
VAL_ 792 DN_ARW_STEP_RQ 0 "NOT_PSD" 1 "PSD" 3 "SNA" ;
VAL_ 792 CELL_VR 0 "CELL_VR_NONE" 1 "CELL_PRESSED" 2 "VR_PRESSED" 3 "SNA" ;
VAL_ 799 IBS_R_Batt 2047 "SNA" ;
VAL_ 799 IBS_R_Batt_25 2047 "SNA" ;
VAL_ 799 TGW_AUD_MD_CAB_DR 0 "AM_SEL" 1 "FM_SEL" 2 "MW_SEL" 3 "LW_SEL" 4 "INT_Disk_SEL" 5 "INT_HDD_SEL" 6 "INT_AUX_SEL" 7 "INT_SLOT_SEL" 8 "USB3_SEL" 9 "SDAR1_SEL" 10 "SW_SEL" 11 "VES_DVD1_SEL" 12 "TMM_SEL" 13 "VES_AUX1_SEL" 14 "VES_AUX2_SEL" 15 "SDARV_SEL" 16 "PPR_SEL" 18 "DAB_SEL" 19 "TGW_USB1_SEL" 20 "ES_SEL" 21 "VES_AUX3_SEL" 22 "VES_AUX4_SEL" 23 "PASS_BT1_SEL" 24 "TV_SEL" 25 "USB2_SEL" 26 "APPS_SEL" 27 "AUD_MUTED" 28 "IR_OFF" 29 "RAD_OFF" 30 "RAD_LOCK" 31 "SNA" ;
VAL_ 799 PSS_Display 0 "OK" 1 "L_OBS_DET" 2 "R_OBS_DET" 3 "L_STEP_DSBL" 4 "R_STEP_DSBL" 5 "PK" 6 "Reserved" 9 "BOTH_DEPLOYED" 10 "BOTH_RETRACTED" 15 "SNA" ;
VAL_ 804 RemSt_Inhibit 0 "INHIBIT_DEFAUILT" 1 "TIME_OUT_RUN" 2 "TIME_OUT_CUST_MODE" 3 "KEY_IN_RUN" 4 "DRV_DOOR_AJAR" 5 "PASS_DOOR_AJAR" 6 "LR_DOOR_AJAR" 7 "RR_DOOR_AJAR" 8 "START_COUNTER" 9 "FAIL_COUNTER" 10 "LOW_RPM_SHUTDOWN" 11 "KEY_IN_IGN" 12 "BRAKE_PRESSED" 13 "HAZARD_LAMP_ON" 14 "NOT_IN_PARK" 15 "VEH_SPEED_HIGH" 16 "HOOD_AJAR" 17 "TRUNK_LIFTGATE" 18 "VTA_ALARM" 19 "PANIC_MODE" 20 "BATT_VOLT_HIGH" 21 "BATT_VOLT_LOW" 22 "POWER_LOSS" 23 "MIL_ON" 24 "OIL_PRESSURE_LOW" 25 "COOLANT_TEMP_HIGH" 26 "RPM_HIGH" 27 "CRANK_NO_START" 28 "REMOTE_OFF_RQ" 29 "RS_DISABLED_PREV" 30 "NOT_CONFIGURED" 31 "NO_HOOD_SWITCH" 32 "NO_AUTO_TRANS" 33 "NOT_ENABLED" 34 "INVALID_SKIM_KEY" 35 "IGN_SNA" 36 "IGN_NOT_LOCK" 37 "GLOW_PLUG_TIMEOUT" 38 "LOW_FUEL" 39 "ETC_LAMP_ON" 40 "LOGISTIC_MODE" 41 "COLD_START_LAMP" 42 "ESL_NOT_UNLOCK" 43 "RFHUB_HS_FAIL" 44 "PSA_Not_Active" 255 "SNA" ;
VAL_ 804 WPR_SYS_OFF 1 "SNA" ;
VAL_ 804 WPR_SYS_LOW 0 "SNA" ;
VAL_ 804 WPR_SYS_HIGH 0 "SNA" ;
VAL_ 804 WPR_SYS_INT 0 "SNA" ;
VAL_ 804 WPR_SYS_AUTO 0 "SNA" ;
VAL_ 804 WPR_SYS_MIST 0 "SNA" ;
VAL_ 804 WPR_SYS_WASH 0 "SNA" ;
VAL_ 804 WPR_SYS_FLT 0 "SNA" ;
VAL_ 804 AirSusp_DnSw 0 "NOT_PSD" 1 "PSD" 3 "SNA" ;
VAL_ 808 TGW_GrpTyp_IC 0 "NO_TEXT" 63 "SNA" ;
VAL_ 810 PTO_Md 0 "STANDARD" 2 "MOBILE" 3 "REMOTE" 7 "SNA" ;
VAL_ 810 PTO_MaxVehSpd 0 "ZERO" 1 "FIVE" 2 "SIX" 3 "SEVEN" 4 "EIGHT" 5 "NINE" 6 "TEN" 7 "ELEVEN" 8 "TWELVE" 9 "THIRTEEN" 10 "FOURTEEN" 11 "FIFTEEN" 12 "SIXTEEN" 13 "SEVENTEEN" 14 "EIGHTEEN" 15 "NINETEEN" 16 "TWENTY" 17 "TWENTY_FIVE" 18 "THIRTY" 19 "THIRTY_FIVE" 20 "FOURTY" 21 "FOURTY_FIVE" 22 "FIFTY" 23 "FIFTY_FIVE" 24 "SIXTY" 25 "SIXTY_FIVE" 26 "SEVENTY" 27 "SEVENTY_FIVE" 28 "EIGHTY" 29 "EIGHTY_FIVE" 30 "NINTY" 31 "SNA" ;
VAL_ 810 PTO_AutoRsm 0 "DISABLE" 1 "ENABLE" ;
VAL_ 810 PTO_TYPES 0 "AUX" 1 "SPLIT" 3 "SNA" ;
VAL_ 810 PTO_SingleRPM 255 "SNA" ;
VAL_ 810 PTO_RPM1 255 "SNA" ;
VAL_ 810 PTO_RPM2 255 "SNA" ;
VAL_ 810 PTO_RPM3 255 "SNA" ;
VAL_ 810 PTO_Sts 0 "PTO_OFF" 1 "PTO_ON" 2 "SET_BRAKE" 3 "REL_BRAKE" 4 "REL_ACC" 5 "REL_CLUTCH" 6 "PARK" 7 "NEUTRAL" 8 "FB_SWITCH" 9 "TC_2WD" 10 "DRIVE" 11 "SPEED_LT2" 12 "RPM_L1000" 13 "RPM_A900" 14 "COLD" 15 "ECT_HIGH" 16 "EOT_HIGH" 17 "FAULT" 31 "SNA" ;
VAL_ 810 FuelTransSts 0 "NONE" 1 "M1" 2 "M2" 3 "M3" 4 "M4" 5 "M5" 6 "M6" 7 "M7" ;
VAL_ 816 HILL_DES_RQ 0 "NOT_PSD" 1 "PSD" 3 "SNA" ;
VAL_ 820 DR_LK_STAT 0 "LKD" 1 "DRV_DR_UNLKD" 2 "ALL_DR_UNLKD" 3 "SNA" ;
VAL_ 820 FOB_SrchRq 0 "NO_ACT" 1 "SEARCH" 2 "RCVD_RSLT" ;
VAL_ 820 IGN_OFF_TIME_LNG 4095 "SNA" ;
VAL_ 820 SHIP_STAT 0 "CUST_MD" 1 "ABBRV_MD" 2 "SHIP_MD" 3 "NOT_PROG" ;
VAL_ 820 PANEL_INTS 255 "SNA" ;
VAL_ 820 PTC_REL1_STAT 0 "OFF" 1 "ON" 2 "FLT" 3 "SNA" ;
VAL_ 820 PTC_REL2_STAT 0 "OFF" 1 "ON" 2 "FLT" 3 "SNA" ;
VAL_ 820 PTC_REL3_STAT 0 "OFF" 1 "ON" 2 "FLT" 3 "SNA" ;
VAL_ 825 PTS_CHIME_TYPE 0 "NONE" 1 "TYP_1" 2 "TYP_2" 3 "TYP_3" 4 "TYP_4" 5 "TYP_5" 6 "TYP_6" 7 "TYP_7" 8 "TYP_8" 9 "TYP_9" 10 "TYP_10" 11 "TYP_11" 12 "TYP_12" 13 "TYP_13" 14 "TYP_14" 15 "SNA" ;
VAL_ 825 PTS_RR_VOL 0 "LOW" 1 "MED" 2 "HIGH" 3 "SNA" ;
VAL_ 825 PTS_FT_VOL 0 "LOW" 1 "MED" 2 "HIGH" 3 "SNA" ;
VAL_ 826 PTS_AlrRL 0 "PTS_ALR_NOD" 1 "ARC1" 2 "ARC2" 3 "ARC3" 4 "ARC4" 5 "ARC5" 6 "ARC6" 7 "ARC7" 8 "ARC8" 15 "SNA" ;
VAL_ 826 PTS_GraphicRL 0 "SLOW_FLS_RQ" 1 "FAST_FLS_RQ" 2 "CONT_FLS_RQ" 3 "None" ;
VAL_ 826 PTS_AlrRR 0 "PTS_ALR_NOD" 1 "ARC1" 2 "ARC2" 3 "ARC3" 4 "ARC4" 5 "ARC5" 6 "ARC6" 7 "ARC7" 8 "ARC8" 15 "SNA" ;
VAL_ 826 PTS_GraphicRR 0 "SLOW_FLS_RQ" 1 "FAST_FLS_RQ" 2 "CONT_FLS_RQ" 3 "None" ;
VAL_ 826 PTS_AlrRC 0 "PTS_ALR_NOD" 1 "ARC1" 2 "ARC2" 3 "ARC3" 4 "ARC4" 5 "ARC5" 6 "ARC6" 7 "ARC7" 8 "ARC8" 15 "SNA" ;
VAL_ 826 PTS_GraphicRC 0 "SLOW_FLS_RQ" 1 "FAST_FLS_RQ" 2 "CONT_FLS_RQ" 3 "None" ;
VAL_ 826 PTS_STAT 0 "OFF" 1 "CONT" 2 "BLINK" 3 "SNA" ;
VAL_ 826 PTS_AlrFC 0 "PTS_ALR_NOD" 1 "ARC1" 2 "ARC2" 3 "ARC3" 4 "ARC4" 5 "ARC5" 6 "ARC6" 7 "ARC7" 8 "ARC8" 15 "SNA" ;
VAL_ 826 PTS_AlrFL 0 "PTS_ALR_NOD" 1 "ARC1" 2 "ARC2" 3 "ARC3" 4 "ARC4" 5 "ARC5" 6 "ARC6" 7 "ARC7" 8 "ARC8" 15 "SNA" ;
VAL_ 826 PTS_AlrFR 0 "PTS_ALR_NOD" 1 "ARC1" 2 "ARC2" 3 "ARC3" 4 "ARC4" 5 "ARC5" 6 "ARC6" 7 "ARC7" 8 "ARC8" 15 "SNA" ;
VAL_ 826 PTS_GraphicFC 0 "SLOW_FLS_RQ" 1 "FAST_FLS_RQ" 2 "CONT_FLS_RQ" 3 "None" ;
VAL_ 826 PTS_GraphicFL 0 "SLOW_FLS_RQ" 1 "FAST_FLS_RQ" 2 "CONT_FLS_RQ" 3 "None" ;
VAL_ 826 PTS_GraphicFR 0 "SLOW_FLS_RQ" 1 "FAST_FLS_RQ" 2 "CONT_FLS_RQ" 3 "None" ;
VAL_ 832 VehSpdDisp 65535 "SNA" ;
VAL_ 832 xtended_AvgFuelLvl 4095 "SNA" ;
VAL_ 838 AS_CHIME_TYPE 0 "NONE" 1 "TYP_1" 2 "TYP_2" 3 "TYP_3" 4 "TYP_4" 5 "TYP_5" 6 "TYP_6" 7 "TYP_7" 8 "TYP_8" 9 "TYP_9" 10 "TYP_10" 11 "TYP_11" 12 "TYP_12" 13 "TYP_13" 14 "TYP_14" 15 "SNA" ;
VAL_ 840 FailSafeError 65535 "SNA" ;
VAL_ 848 DateTmSec 255 "SNA" ;
VAL_ 848 DateTmMinute 255 "SNA" ;
VAL_ 848 DateTmHour 255 "SNA" ;
VAL_ 848 DateTmYear 65535 "SNA" ;
VAL_ 848 DateTmMonth 255 "SNA" ;
VAL_ 848 DateTmDay 255 "SNA" ;
VAL_ 848 DateTmFormat 0 "NDEF0" 1 "FORMAT_12H" 2 "FORMAT_24H" 3 "FORMAT_0" 4 "FORMAT_1" 5 "FORMAT_2" 6 "FORMAT_3" 7 "SNA" ;
VAL_ 853 RrAxleLckr_Rq 0 "NPSD" 1 "PSD" 2 "NDEF2" 3 "SNA" ;
VAL_ 853 TCASE_NEUT_RQ 0 "NPSD" 1 "PSD" 2 "NDEF2" 3 "SNA" ;
VAL_ 853 TcaseSwTyp 0 "ROT" 1 "PB" 3 "SNA" ;
VAL_ 853 TcaseAWD_Rq 0 "NPSD" 1 "PSD" 2 "NDEF2" 3 "SNA" ;
VAL_ 853 Tcase4Low_Rq 0 "NPSD" 1 "PSD" 2 "NDEF2" 3 "SNA" ;
VAL_ 853 Tcase4Lock_Rq 0 "NPSD" 1 "PSD" 2 "NDEF2" 3 "SNA" ;
VAL_ 853 Tcase2WD_Rq 0 "NPSD" 1 "PSD" 2 "NDEF2" 3 "SNA" ;
VAL_ 853 PARK_ASST_RQ 0 "NOT_PSD" 1 "PSD" 3 "SNA" ;
VAL_ 853 FT_PARK_ASST_RQ 0 "NOT_PSD" 1 "PSD" 3 "SNA" ;
VAL_ 856 CMP_DIR 0 "CMP_N" 1 "CMP_N_E" 2 "CMP_E" 3 "CMP_S_E" 4 "CMP_S" 5 "CMP_S_W" 6 "CMP_W" 7 "CMP_N_W" 8 "NONE" 15 "SNA" ;
VAL_ 856 VAR_VAL 15 "SNA_Default" ;
VAL_ 856 CMP_DIR_RAW 511 "SNA_Default" ;
VAL_ 860 DIST_TO_TURN 65535 "SNA" ;
VAL_ 860 UNITS 0 "NO_UNITS" 1 "MILE" 2 "FEET" 3 "KM" 4 "METER" 5 "YARD" 7 "SNA" ;
VAL_ 860 NAV_ARROW 0 "NAV_NOT_ACT" ;
VAL_ 863 RevOilLifeRst 65535 "SNA" ;
VAL_ 882 LANG_C 0 "GERMAN" 1 "US_ENGLISH" 2 "FRENCH" 3 "ITALIAN" 4 "SPANISH" 5 "JAPANESE" 6 "PORTUGESE" 7 "DUTCH" 8 "UK_ENGLISH" 9 "MANDARIN_S" 10 "RUSSIAN" 11 "KOREAN" 12 "ARABIC" 13 "BRAZILIAN" 14 "MANDARIN_T" 15 "HINDI" 16 "TURKISH" 17 "POLISH" 31 "LANG_NO_CHG" ;
VAL_ 882 PowerUnit 0 "KW" 1 "HP_UK" 2 "HP_US" ;
VAL_ 882 PressureUnit 0 "KPA" 1 "BAR" 2 "PSI" ;
VAL_ 882 CapacityUnit 0 "L" 1 "G_UK" 2 "G_US" ;
VAL_ 882 ConsumptionUnit 0 "KMPL" 1 "LP100KM" 2 "MPG_UK" 3 "MPG_US" 7 "SNA" ;
VAL_ 882 UNIT_SET_CSO 0 "UnitSet_1" 1 "UnitSet_2" 2 "UnitSet_3" 3 "UnitSet_4" ;
VAL_ 897 VC_VehCfg7_Stat 0 "NA" 1 "PROGAMMED" 2 "REQUEST_DATA" 3 "SNA" ;
VAL_ 897 VC_TransType 0 "NP" 1 "SI_EVT_Hybrid_Trans" 2 "MTA" 3 "c40TES" 4 "Aisin_LD" 5 "W5A580" 6 "c62TE" 7 "c65RFE" 8 "c66RFE" 9 "c68RFE" 10 "AISIN_HD" 11 "DDCT_C635" 12 "HPT_6F24" 13 "ZF_8Spd" 14 "ZF_9Spd" 63 "SNA" ;
VAL_ 897 VC_AS_ERS 0 "NONE" 1 "ERS" 2 "AS" 3 "SNA" ;
VAL_ 897 VC_ACC_Type 0 "NONE" 1 "ACC" 2 "STOP" 3 "GO" ;
VAL_ 897 VC_AxleLockerPrsnt 0 "NONE" 1 "REAR" 2 "FTRR" ;
VAL_ 897 VC_PBTyp 0 "MECH" 1 "EPB_MOC" 2 "EPB_CP" 3 "IMOC" 4 "ICP" 7 "SNA" ;
VAL_ 897 VC_TPMS_Configuration 0 "NHTSA" 1 "NAFTA" 2 "ECE" 3 "OTHER" 4 "CHINA" 7 "SNA" ;
VAL_ 897 VC_HybridType 0 "NONE" 1 "BEV" 2 "HEV" 3 "PHEV" 4 "BSG48" ;
VAL_ 897 VC_Temp_Display_Resolution 0 "One_Degree_C" 1 "Half_Degree_C" ;
VAL_ 897 VC_Suspension_Type 0 "None" 1 "1" 2 "2" 3 "3" 4 "4" 5 "5" 6 "6" 7 "7" 8 "8" 9 "9" 10 "10" 11 "11" 12 "12" 13 "13" 14 "14" 15 "15" ;
VAL_ 897 VC_MOC_Type 0 "NO_MOC" 1 "MOC_BREMBO" 2 "MOC_CONTI" ;
VAL_ 897 VC_Brake_Type 0 "None" 1 "1" 2 "2" 3 "3" 4 "4" 5 "5" 6 "6" 7 "7" 8 "8" 9 "9" 10 "10" 11 "11" 12 "12" 13 "13" 14 "14" 15 "15" ;
VAL_ 897 VC_AGSprsnt 0 "Not_Present" 1 "Present" ;
VAL_ 897 VC_GlareFree_Prsnt 0 "Not_Present" 1 "Present" ;
VAL_ 897 VC_Vehicle_Package 0 "None" 1 "Type_1" 2 "Type_2" 3 "Type_3" 4 "Type_4" 5 "Type_5" 6 "Type_6" 7 "Type_7" ;
VAL_ 897 VC_TrafficSignInfo 0 "Not_Present" 1 "Present" ;
VAL_ 897 VC_PAD_Lamp_Ctrl 0 "CLUSTER" 1 "ORC" ;
VAL_ 897 VC_LDW_Audio 0 "Not_Present" 1 "Present" ;
VAL_ 897 VC_LaneCentering 0 "Not_Present" 1 "Present" ;
VAL_ 898 VC_BU_VehCfg7_Stat 0 "NA" 1 "PROGAMMED" 2 "NA1" 3 "SNA" ;
VAL_ 898 VC_BU_TransType 0 "NP" 1 "SI_EVT_Hybrid_Trans" 2 "MTA" 3 "c40TES" 4 "Aisin_LD" 5 "W5A580" 6 "c62TE" 7 "c65RFE" 8 "c66RFE" 9 "c68RFE" 10 "AISIN_HD" 11 "DDCT_C635" 12 "HPT_6F24" 13 "ZF_8Spd" 14 "ZF_9Spd" 63 "SNA" ;
VAL_ 898 VC_BU_AS_ERS 0 "NONE" 1 "ERS" 2 "AS" 3 "SNA" ;
VAL_ 898 VC_BU_ACC_Type 0 "NONE" 1 "ACC" 2 "STOP" 3 "GO" ;
VAL_ 898 VC_BU_AxleLockerPrsnt 0 "NONE" 1 "REAR" 2 "FTRR" ;
VAL_ 898 VC_BU_PBTyp 0 "MECH" 1 "EPB_MOC" 2 "EPB_CP" 3 "IMOC" 4 "ICP" 7 "SNA" ;
VAL_ 898 VC_BU_TPMS_Configuration 0 "NHTSA" 1 "NAFTA" 2 "ECE" 3 "OTHER" 4 "CHINA" 7 "SNA" ;
VAL_ 898 VC_BU_HybridType 0 "NONE" 1 "BEV" 2 "HEV" 3 "PHEV" 4 "BSG48" ;
VAL_ 898 VC_BU_Temp_Display_Resolution 0 "One_Degree_C" 1 "Half_Degree_C" ;
VAL_ 898 VC_BU_Suspension_Type 0 "None" 1 "1" 2 "2" 3 "3" 4 "4" 5 "5" 6 "6" 7 "7" 8 "8" 9 "9" 10 "10" 11 "11" 12 "12" 13 "13" 14 "14" 15 "15" ;
VAL_ 898 VC_BU_MOC_Type 0 "NO_MOC" 1 "MOC_BREMBO" 2 "MOC_CONTI" ;
VAL_ 898 VC_BU_Brake_Type 0 "None" 1 "1" 2 "2" 3 "3" 4 "4" 5 "5" 6 "6" 7 "7" 8 "8" 9 "9" 10 "10" 11 "11" 12 "12" 13 "13" 14 "14" 15 "15" ;
VAL_ 898 VC_BU_AGSprsnt 0 "Not_Present" 1 "Present" ;
VAL_ 898 VC_BU_Vehicle_Package 0 "NA" 1 "Type_1" 2 "Type_2" 3 "Type_3" 4 "Type_4" 5 "Type_5" 6 "Type_6" 7 "Type_7" ;
VAL_ 898 VC_BU_TrafficSignInfo 0 "Not_Present" 1 "Present" ;
VAL_ 898 VC_BU_PAD_Lamp_Ctrl 0 "CLUSTER" 1 "ORC" ;
VAL_ 898 VC_BU_GlareFree_Prsnt 0 "Not_Present" 1 "Present" ;
VAL_ 898 VC_BU_LDW_Audio 0 "Not_Present" 1 "Present" ;
VAL_ 898 VC_BU_LaneCentering 0 "Not_Present" 1 "Present" ;
VAL_ 937 ILL_APRCH_TIME 255 "SNA" ;
VAL_ 937 HL_DLY_TIME 255 "SNA" ;
VAL_ 937 ACC_DLY_TIME 65535 "SNA" ;
VAL_ 937 SOUND_LK_1ST_2ND 0 "OFF" 1 "FIRST" 2 "SECOND" 3 "SNA" ;
VAL_ 947 VC_VehCfgCSO1_Stat 0 "NA" 1 "PROGAMMED" 2 "REQUEST_DATA" 3 "SNA" ;
VAL_ 947 VC_PRK_AST_CSO 0 "Absent" 1 "Option_1_2" 2 "Option_2_3" ;
VAL_ 947 VC_FCW_CSO 0 "Absent" 1 "Option_1_2" 2 "Option_2_3" ;
VAL_ 947 VC_HRN_RMT_LK_CSO 0 "Absent" 1 "Option_1_2" 2 "Option_2_3" ;
VAL_ 947 VC_DCS_CSO 0 "Absent" 1 "Option_1_2" 2 "Option_2_3" ;
VAL_ 947 VC_AUX_SWS_CSO 0 "Absent" 1 "SWITCH_1_4" 2 "SWITCH_2_5" 3 "SWITCH_3_6" ;
VAL_ 947 VC_CMRA_GRDLNS_CSO 0 "Absent" 1 "STATIC" 2 "DYNAMIC" 3 "STATIC_DYNAMIC" ;
VAL_ 948 VC_VehCfgCSO2_Stat 0 "NA" 1 "PROGAMMED" 2 "REQUEST_DATA" 3 "SNA" ;
VAL_ 948 VC_SPEED_WARNING_CSO 0 "ABSENT" 1 "ONE" 2 "FIVE" ;
VAL_ 949 VC_BU_VehCfgCSO1_Stat 0 "NA" 1 "PROGAMMED" 2 "REQUEST_DATA" 3 "SNA" ;
VAL_ 949 VC_BU_PRK_AST_CSO 0 "Absent" 1 "Option_1_2" 2 "Option_2_3" ;
VAL_ 949 VC_BU_FCW_CSO 0 "Absent" 1 "Option_1_2" 2 "Option_2_3" ;
VAL_ 949 VC_BU_HRN_RMT_LK_CSO 0 "Absent" 1 "Option_1_2" 2 "Option_2_3" ;
VAL_ 949 VC_BU_DCS_CSO 0 "Absent" 1 "Option_1_2" 2 "Option_2_3" ;
VAL_ 949 VC_BU_AUX_SWS_CSO 0 "Absent" 1 "SWITCH_1_4" 2 "SWITCH_2_5" 3 "SWITCH_3_6" ;
VAL_ 949 VC_BU_CMRA_GRDLNS_CSO 0 "Absent" 1 "STATIC" 2 "DYNAMIC" 3 "STATIC_DYNAMIC" ;
VAL_ 950 VC_BU_VehCfgCSO2_Stat 0 "NA" 1 "PROGAMMED" 2 "REQUEST_DATA" 3 "SNA" ;
VAL_ 950 VC_BU_SPEED_WARNING_CSO 0 "ABSENT" 1 "ONE" 2 "FIVE" ;
VAL_ 956 NAV_GrpTyp 0 "NO_TEXT" 63 "SNA" ;
VAL_ 969 AMB_TEMP_AVG_F 255 "SNA" ;
VAL_ 969 AMB_TEMP_AVG_C 255 "SNA" ;
VAL_ 974 FT_HVAC_BLW_FN_SP 127 "SNA" ;
VAL_ 974 DRV_TEMP_DR_POS 127 "SNA" ;
VAL_ 977 TransTyp 0 "NS" 1 "TRNS1" 2 "TRNS2" 255 "SNA" ;
VAL_ 979 EC_ECUCfg14_Stat 0 "NA" 1 "PROGAMMED" 2 "REQUEST_DATA" 3 "SNA" ;
VAL_ 980 EC_ECUCfg13_Stat 0 "NA" 1 "PROGAMMED" 2 "REQUEST_DATA" 3 "SNA" ;
VAL_ 981 EC_ECUCfg12_Stat 0 "NA" 1 "PROGAMMED" 2 "REQUEST_DATA" 3 "SNA" ;
VAL_ 982 EC_ECUCfg11_Stat 0 "NA" 1 "PROGAMMED" 2 "REQUEST_DATA" 3 "SNA" ;
VAL_ 983 EC_ECUCfg10_Stat 0 "NA" 1 "PROGAMMED" 2 "REQUEST_DATA" 3 "SNA" ;
VAL_ 984 EC_ECUCfg9_Stat 0 "NA" 1 "PROGAMMED" 2 "REQUEST_DATA" 3 "SNA" ;
VAL_ 985 EC_BU_ECUCfg14_Stat 0 "NA" 1 "PROGAMMED" 2 "NA1" 3 "SNA" ;
VAL_ 986 EC_BU_ECUCfg13_Stat 0 "NA" 1 "PROGAMMED" 2 "NA1" 3 "SNA" ;
VAL_ 987 EC_BU_ECUCfg12_Stat 0 "NA" 1 "PROGAMMED" 2 "NA1" 3 "SNA" ;
VAL_ 988 EC_BU_ECUCfg11_Stat 0 "NA" 1 "PROGAMMED" 2 "REQUEST_DATA" 3 "SNA" ;
VAL_ 989 EC_BU_ECUCfg10_Stat 0 "NA" 1 "PROGAMMED" 2 "NA1" 3 "SNA" ;
VAL_ 991 EC_BU_ECUCfg9_Stat 0 "NA" 1 "PROGAMMED" 2 "NA1" 3 "SNA" ;
VAL_ 993 DISPLACEMENT 255 "SNA" ;
VAL_ 993 NUM_CYL 15 "SNA" ;
VAL_ 993 ENG_ASP 0 "INTAKE_NORM" 1 "TURBO1" 2 "TURBO2" 3 "SUPER" 7 "SNA" ;
VAL_ 993 FUEL_TYPE 0 "UNLEADED" 1 "DIESEL" 2 "FLEX" 3 "CNG" 7 "SNA" ;
VAL_ 993 ECM_Vehi_Type 0 "STANDARD" 1 "EVEHICLE" 3 "SNA" ;
VAL_ 993 Manufacture 0 "ENG_DCA" 1 "ENG_DCS" 2 "ENG_MMC" 3 "ENG_HY" 7 "ENG_NP" ;
VAL_ 993 NUM_VALVE 7 "SNA" ;
VAL_ 993 EngStyle 0 "CHOICE1" 1 "CHOICE2" 2 "CHOICE3" 3 "CHOICE4" 4 "CHOICE5" 5 "CHOICE6" 7 "SNA" ;
VAL_ 995 NET_CFG_STAT_INT 0 "NA" 1 "PROGAMMED" 2 "REQUEST_DATA" 3 "SNA" ;
VAL_ 995 NetCfg_ANC_I 0 "Not_Present" 1 "Present" ;
VAL_ 995 NetCfg_TTM 0 "Not_Present" 1 "Present" ;
VAL_ 996 NET_CFG_STAT_PT 0 "NA" 1 "PROGAMMED" 2 "REQUEST_DATA" 3 "SNA" ;
VAL_ 996 NetCfg_BSMO 0 "Not_Present" 1 "Present" ;
VAL_ 996 NetCfg_SGW 0 "Not_Present" 1 "Present" ;
VAL_ 996 NetCfg_DPDM 0 "Not_Present" 1 "Present" ;
VAL_ 996 NetCfg_ASBS 0 "Not_Present" 1 "Present" ;
VAL_ 996 NetCfg_SWSM 0 "Not_Present" 1 "Present" ;
VAL_ 996 NetCfg_MSBD 0 "Not_Present" 1 "Present" ;
VAL_ 998 BU_NET_CFG_STAT_INT 0 "NA" 1 "PROGAMMED" 2 "NA1" 3 "SNA" ;
VAL_ 998 BU_NetCfg_ANC_I 0 "Not_Present" 1 "Present" ;
